VERSION ""

NS_ :

BS_:

BU_: TCM HCM IPMA_ADAS PSCM ABS_ESC TCCM TCM_DSL PCM_HEV PCM ECM_HEVDSL ECM_HEV ECM_Diesel ECM SIMA_DLCS BCMD_IPDB VDM CMR_DSMC SOBDMC_HPCM CHCM GWM _delete AWD_DLCM GENERIC TSTR

BO_ 495 EngineData_14_FD1: 8 GWM
 SG_ AlchlLck_D_RqLimActvtn : 2|2@0+ (1,0) [0|3] "unitless"  ECM,ECM_Diesel,ECM_HEV,PCM,PCM_HEV
 SG_ AlchlLck2_D_RqLim : 7|5@0+ (1,0) [0|31] "unitless"  ECM,ECM_Diesel,ECM_HEV,PCM,PCM_HEV
 SG_ AlchlLck1_D_RqLim : 15|5@0+ (1,0) [0|31] "unitless"  ECM,ECM_Diesel,ECM_HEV,PCM,PCM_HEV

BO_ 466 EngineData_13: 8 ECM
 SG_ AlchlLck1_D_ResLim : 27|5@0+ (1,0) [0|31] "unitless"  GWM
 SG_ AlchlLck2_D_ResLim : 35|5@0+ (1,0) [0|31] "unitless"  GWM
 SG_ AlchlLck1_D_StatLim : 38|3@0+ (1,0) [0|7] "unitless"  GWM
 SG_ AlchlLck2_D_StatLim : 46|3@0+ (1,0) [0|7] "unitless"  GWM

BO_ 283 HEV_EngineData3: 8 ECM_HEV
 SG_ AirCondClnt_Te_Actl : 7|8@0+ (1,-60) [-60|194] "degC"  SOBDMC_HPCM

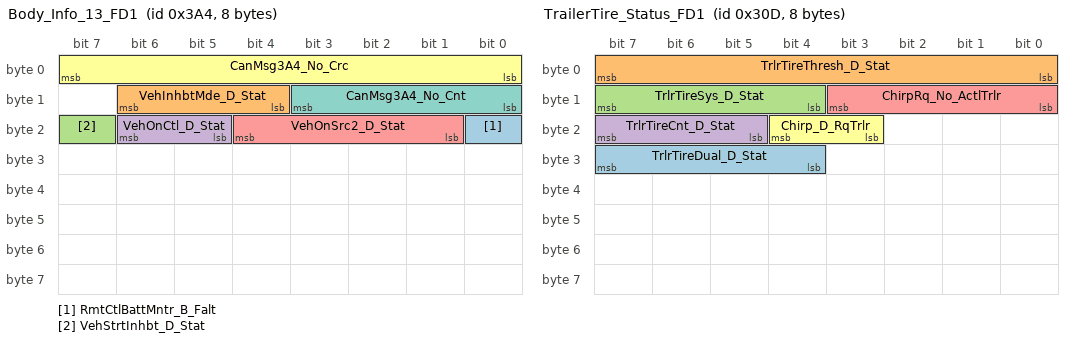
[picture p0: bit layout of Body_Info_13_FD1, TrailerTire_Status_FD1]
BO_ 932 Body_Info_13_FD1: 8 BCM
 SG_ RmtCtlBattMntr_B_Falt : 16|1@0+ (1,0) [0|1] "SED"  GENERIC
 SG_ VehInhbtMde_D_Stat : 14|3@0+ (1,0) [0|7] "SED"  GENERIC
 SG_ VehStrtInhbt_D_Stat : 23|1@0+ (1,0) [0|1] "SED"  GENERIC
 SG_ VehOnCtl_D_Stat : 22|2@0+ (1,0) [0|3] "SED"  GENERIC
 SG_ VehOnSrc2_D_Stat : 20|4@0+ (1,0) [0|15] "SED"  IPMA_ADAS
 SG_ CanMsg3A4_No_Crc : 7|8@0+ (1,0) [0|255] "Unitless"  GENERIC
 SG_ CanMsg3A4_No_Cnt : 11|4@0+ (1,0) [0|15] "Unitless"  GENERIC

BO_ 781 TrailerTire_Status_FD1: 8 GFM_TTPMS
 SG_ TrlrTireDual_D_Stat : 31|4@0+ (1,0) [0|15] "SED"  GENERIC
 SG_ TrlrTireThresh_D_Stat : 7|8@0+ (1,0) [0|255] "unitless"  GENERIC
 SG_ TrlrTireSys_D_Stat : 15|4@0+ (1,0) [0|15] "SED"  IPMA_ADAS
 SG_ TrlrTireCnt_D_Stat : 23|3@0+ (1,0) [0|6] "SED"  GENERIC
 SG_ ChirpRq_No_ActlTrlr : 11|4@0+ (1,0) [0|15] "unitless"  GENERIC
 SG_ Chirp_D_RqTrlr : 20|2@0+ (1,0) [0|3] "SED"  GENERIC

BO_ 368 PowertrainData_4: 8 SOBDMC_HPCM
 SG_ PrplBrkTqCtl_No_Cs : 7|8@0+ (1,0) [0|255] "Unitless"  ABS_ESC
 SG_ PrplBrkTqCtl_No_Cnt : 15|4@0+ (1,0) [0|15] "Unitless"  ABS_ESC
 SG_ PrplWhlTot_Tq_RqFilt : 23|16@0+ (4,-131072) [-131072|131060] "Nm"  ABS_ESC

BO_ 1267 Battery_Traction_14_FD1: 8 BECM
 SG_ BattTracLearn_R_Est : 7|20@0+ (1E-005,0) [0|10.48573] "ohm"  SOBDMC_HPCM
 SG_ BattTracLearnRC_C_Est : 19|20@0+ (0.1,0) [0|104857.3] "farad"  SOBDMC_HPCM
 SG_ BattTracLearnRC_R_Est : 47|20@0+ (1E-005,0) [0|10.48573] "ohm"  SOBDMC_HPCM

BO_ 393 AssistedFrontLighting: 64 IPMA_ADAS
 SG_ Afl6TrnstnRight_An_Rq : 419|4@0+ (0.2,0) [0|3] "degrees" Vector__XXX
 SG_ Afl6TrnstnLeft_An_Rq : 423|4@0+ (0.2,0) [0|3] "degrees" Vector__XXX
 SG_ Afl6RightLghtRigh_An_Rq : 432|9@0+ (0.1,-25.6) [-25.6|25.5] "degrees" Vector__XXX
 SG_ Afl6RightLghtLeft_An_Rq : 400|9@0+ (0.1,-25.6) [-25.6|25.5] "degrees" Vector__XXX
 SG_ Afl6Ramping_T_Rq : 387|4@0+ (0.2,0) [0|3] "second" Vector__XXX
 SG_ Afl6LeftLghtRight_An_Rq : 431|9@0+ (0.1,-25.6) [-25.6|25.5] "degrees" Vector__XXX
 SG_ Afl6LeftLghtLeft_An_Rq : 399|9@0+ (0.1,-25.6) [-25.6|25.5] "degrees" Vector__XXX
 SG_ Afl6BrdrTop_An_Rq : 438|6@0+ (0.1,-5) [-5|1.3] "degrees" Vector__XXX
 SG_ Afl6BrdrBottom_An_Rq : 406|6@0+ (0.1,-5) [-5|1.3] "degrees" Vector__XXX
 SG_ Afl5TrnstnRight_An_Rq : 355|4@0+ (0.2,0) [0|3] "degrees" Vector__XXX
 SG_ Afl5TrnstnLeft_An_Rq : 359|4@0+ (0.2,0) [0|3] "degrees" Vector__XXX
 SG_ Afl5RightLghtRigh_An_Rq : 368|9@0+ (0.1,-25.6) [-25.6|25.5] "degrees" Vector__XXX
 SG_ Afl5RightLghtLeft_An_Rq : 336|9@0+ (0.1,-25.6) [-25.6|25.5] "degrees" Vector__XXX
 SG_ Afl5Ramping_T_Rq : 323|4@0+ (0.2,0) [0|3] "second" Vector__XXX
 SG_ Afl5LeftLghtRight_An_Rq : 367|9@0+ (0.1,-25.6) [-25.6|25.5] "degrees" Vector__XXX
 SG_ Afl5LeftLghtLeft_An_Rq : 335|9@0+ (0.1,-25.6) [-25.6|25.5] "degrees" Vector__XXX
 SG_ Afl5BrdrTop_An_Rq : 374|6@0+ (0.1,-5) [-5|1.3] "degrees" Vector__XXX
 SG_ Afl5BrdrBottom_An_Rq : 342|6@0+ (0.1,-5) [-5|1.3] "degrees" Vector__XXX
 SG_ Afl4TrnstnRight_An_Rq : 291|4@0+ (0.2,0) [0|3] "degrees" Vector__XXX
 SG_ Afl4TrnstnLeft_An_Rq : 295|4@0+ (0.2,0) [0|3] "degrees" Vector__XXX
 SG_ Afl4RightLghtRigh_An_Rq : 304|9@0+ (0.1,-25.6) [-25.6|25.5] "degrees" Vector__XXX
 SG_ Afl4RightLghtLeft_An_Rq : 272|9@0+ (0.1,-25.6) [-25.6|25.5] "degrees" Vector__XXX
 SG_ Afl4Ramping_T_Rq : 259|4@0+ (0.2,0) [0|3] "second" Vector__XXX
 SG_ Afl4LeftLghtRight_An_Rq : 303|9@0+ (0.1,-25.6) [-25.6|25.5] "degrees" Vector__XXX
 SG_ Afl4LeftLghtLeft_An_Rq : 271|9@0+ (0.1,-25.6) [-25.6|25.5] "degrees" Vector__XXX
 SG_ Afl4BrdrTop_An_Rq : 310|6@0+ (0.1,-5) [-5|1.3] "degrees" Vector__XXX
 SG_ Afl4BrdrBottom_An_Rq : 278|6@0+ (0.1,-5) [-5|1.3] "degrees" Vector__XXX
 SG_ Afl3TrnstnRight_An_Rq : 227|4@0+ (0.2,0) [0|3] "degrees" Vector__XXX
 SG_ Afl3TrnstnLeft_An_Rq : 231|4@0+ (0.2,0) [0|3] "degrees" Vector__XXX
 SG_ Afl3RightLghtRigh_An_Rq : 240|9@0+ (0.1,-25.6) [-25.6|25.5] "degrees" Vector__XXX
 SG_ Afl3RightLghtLeft_An_Rq : 208|9@0+ (0.1,-25.6) [-25.6|25.5] "degrees" Vector__XXX
 SG_ Afl3Ramping_T_Rq : 195|4@0+ (0.2,0) [0|3] "second" Vector__XXX
 SG_ Afl3LeftLghtRight_An_Rq : 239|9@0+ (0.1,-25.6) [-25.6|25.5] "degrees" Vector__XXX
 SG_ Afl3BrdrTop_An_Rq : 246|6@0+ (0.1,-5) [-5|1.3] "degrees" Vector__XXX
 SG_ Afl3BrdrBottom_An_Rq : 214|6@0+ (0.1,-5) [-5|1.3] "degrees" Vector__XXX
 SG_ Afl2BrdrBottom_An_Rq : 150|6@0+ (0.1,-5) [-5|1.3] "degrees" Vector__XXX
 SG_ Afl1BrdrBottom_An_Rq : 86|6@0+ (0.1,-5) [-5|1.3] "degrees" Vector__XXX
 SG_ Afl2BrdrTop_An_Rq : 182|6@0+ (0.1,-5) [-5|1.3] "degrees" Vector__XXX
 SG_ Afl1BrdrTop_An_Rq : 118|6@0+ (0.1,-5) [-5|1.3] "degrees" Vector__XXX
 SG_ Afl2TrnstnRight_An_Rq : 163|4@0+ (0.2,0) [0|3] "degrees" Vector__XXX
 SG_ Afl1TrnstnRight_An_Rq : 99|4@0+ (0.2,0) [0|3] "degrees" Vector__XXX
 SG_ Afl2RightLghtRigh_An_Rq : 176|9@0+ (0.1,-25.6) [-25.6|25.5] "degrees" Vector__XXX
 SG_ Afl1RightLghtRigh_An_Rq : 112|9@0+ (0.1,-25.6) [-25.6|25.5] "degrees" Vector__XXX
 SG_ Afl2LeftLghtRight_An_Rq : 175|9@0+ (0.1,-25.6) [-25.6|25.5] "degrees" Vector__XXX
 SG_ Afl1LeftLghtRight_An_Rq : 111|9@0+ (0.1,-25.6) [-25.6|25.5] "degrees" Vector__XXX
 SG_ Afl2TrnstnLeft_An_Rq : 167|4@0+ (0.2,0) [0|3] "degrees" Vector__XXX
 SG_ Afl1TrnstnLeft_An_Rq : 103|4@0+ (0.2,0) [0|3] "degrees" Vector__XXX
 SG_ Afl2RightLghtLeft_An_Rq : 144|9@0+ (0.1,-25.6) [-25.6|25.5] "degrees" Vector__XXX
 SG_ Afl1RightLghtLeft_An_Rq : 80|9@0+ (0.1,-25.6) [-25.6|25.5] "degrees" Vector__XXX
 SG_ Afl3LeftLghtLeft_An_Rq : 207|9@0+ (0.1,-25.6) [-25.6|25.5] "degrees" Vector__XXX
 SG_ Afl2LeftLghtLeft_An_Rq : 143|9@0+ (0.1,-25.6) [-25.6|25.5] "degrees" Vector__XXX
 SG_ Afl1LeftLghtLeft_An_Rq : 79|9@0+ (0.1,-25.6) [-25.6|25.5] "degrees" Vector__XXX
 SG_ Afl2Ramping_T_Rq : 131|4@0+ (0.2,0) [0|3] "second" Vector__XXX
 SG_ Afl1Ramping_T_Rq : 67|4@0+ (0.2,0) [0|3] "second" Vector__XXX
 SG_ Afl6Mde_D_Rq : 391|4@0+ (1,0) [0|15] "SED" Vector__XXX
 SG_ Afl5Mde_D_Rq : 327|4@0+ (1,0) [0|15] "SED" Vector__XXX
 SG_ Afl4Mde_D_Rq : 263|4@0+ (1,0) [0|15] "SED" Vector__XXX
 SG_ Afl3Mde_D_Rq : 199|4@0+ (1,0) [0|15] "SED" Vector__XXX
 SG_ Afl2Mde_D_Rq : 135|4@0+ (1,0) [0|15] "SED" Vector__XXX
 SG_ Afl1Mde_D_Rq : 71|4@0+ (1,0) [0|15] "SED" Vector__XXX
 SG_ HeadLghtHi_T_Rq : 4|4@0+ (0.2,0) [0|3] "second" Vector__XXX
 SG_ HeadLghtHi_D_Rq : 7|3@0+ (1,0) [0|7] "SED" Vector__XXX

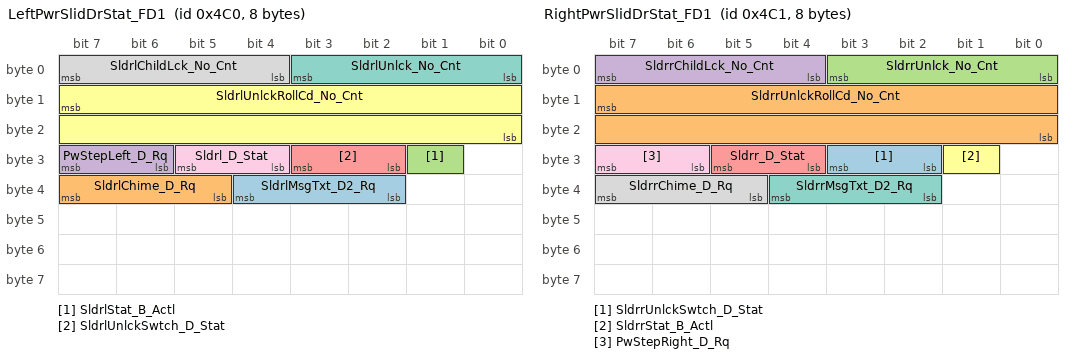
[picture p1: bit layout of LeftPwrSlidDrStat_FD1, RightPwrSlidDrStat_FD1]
BO_ 1216 LeftPwrSlidDrStat_FD1: 8 DCMG_LPSDM
 SG_ SldrlMsgTxt_D2_Rq : 36|3@0+ (1,0) [0|7] "SED"  GENERIC
 SG_ SldrlChime_D_Rq : 39|3@0+ (1,0) [0|7] "SED"  GENERIC
 SG_ SldrlStat_B_Actl : 25|1@0+ (1,0) [0|1] "SED"  GENERIC
 SG_ PwStepLeft_D_Rq : 31|2@0+ (1,0) [0|3] "SED"  GENERIC
 SG_ SldrlUnlckSwtch_D_Stat : 27|2@0+ (1,0) [0|3] "SED"  GENERIC
 SG_ SldrlUnlckRollCd_No_Cnt : 15|16@0+ (1,0) [0|65535] "unitless"  GENERIC
 SG_ SldrlUnlck_No_Cnt : 3|4@0+ (1,0) [0|15] "unitless"  GENERIC
 SG_ SldrlChildLck_No_Cnt : 7|4@0+ (1,0) [0|15] "unitless"  GENERIC
 SG_ Sldrl_D_Stat : 29|2@0+ (1,0) [0|3] "SED"  IPMA_ADAS

BO_ 1217 RightPwrSlidDrStat_FD1: 8 DCMH_RPSDM
 SG_ SldrrUnlckSwtch_D_Stat : 27|2@0+ (1,0) [0|3] "SED"  GENERIC
 SG_ SldrrUnlckRollCd_No_Cnt : 15|16@0+ (1,0) [0|65535] "unitless"  GENERIC
 SG_ SldrrUnlck_No_Cnt : 3|4@0+ (1,0) [0|15] "unitless"  GENERIC
 SG_ SldrrChildLck_No_Cnt : 7|4@0+ (1,0) [0|15] "unitless"  GENERIC
 SG_ Sldrr_D_Stat : 29|2@0+ (1,0) [0|3] "SED"  IPMA_ADAS
 SG_ SldrrStat_B_Actl : 25|1@0+ (1,0) [0|1] "SED"  GENERIC
 SG_ SldrrMsgTxt_D2_Rq : 36|3@0+ (1,0) [0|7] "SED"  GENERIC
 SG_ SldrrChime_D_Rq : 39|3@0+ (1,0) [0|7] "SED"  GENERIC
 SG_ PwStepRight_D_Rq : 31|2@0+ (1,0) [0|3] "SED"  GENERIC

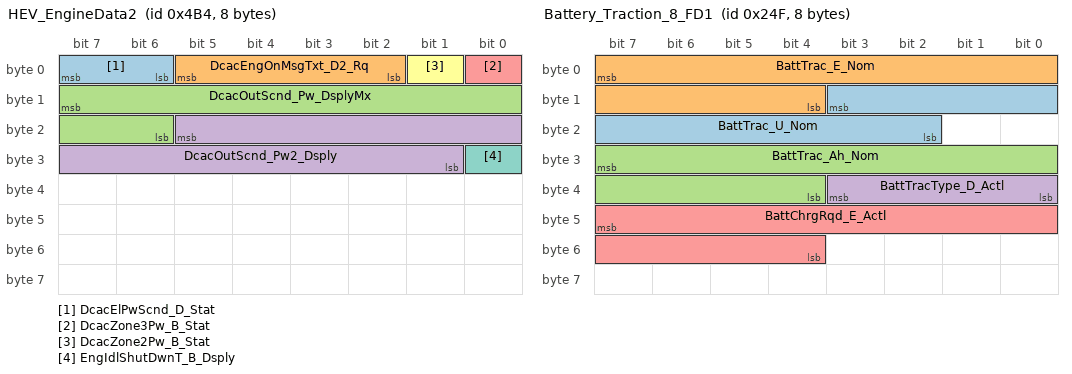
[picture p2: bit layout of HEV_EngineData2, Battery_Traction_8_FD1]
BO_ 1204 HEV_EngineData2: 8 ECM_HEV
 SG_ DcacElPwScnd_D_Stat : 7|2@0+ (1,0) [0|3] "SED"  GWM
 SG_ DcacEngOnMsgTxt_D2_Rq : 5|4@0+ (1,0) [0|15] "SED"  GWM
 SG_ DcacOutScnd_Pw_DsplyMx : 15|10@0+ (10,0) [0|10220] "watts"  GWM
 SG_ DcacOutScnd_Pw2_Dsply : 21|13@0+ (1,0) [0|8189] "watts"  GWM
 SG_ DcacZone3Pw_B_Stat : 0|1@0+ (1,0) [0|1] "SED"  GWM
 SG_ DcacZone2Pw_B_Stat : 1|1@0+ (1,0) [0|1] "SED"  GWM
 SG_ EngIdlShutDwnT_B_Dsply : 24|1@0+ (1,0) [0|1] "SED"  GWM

BO_ 816 APIM_Send_Signals_3_FD1: 8 APIM_CISM
 SG_ Dimming_Lvl_RqMnu : 63|5@0+ (1,0) [0|31] "SED"  GENERIC
 SG_ DcacPwResetScnd_B_Rq : 24|1@0+ (1,0) [0|1] "SED"  ECM_HEV
 SG_ DcacPwScnd_D_Rq : 53|2@0+ (1,0) [0|3] "SED"  ECM_HEV
 SG_ DcacZone3Pw_D_Rq : 55|2@0+ (1,0) [0|3] "SED"  ECM_HEV
 SG_ DcacZone2Pw_D_Rq : 35|2@0+ (1,0) [0|3] "SED"  ECM_HEV
 SG_ DcacAllZone_D_Rq : 37|2@0+ (1,0) [0|3] "SED"  ECM_HEV
 SG_ DcacLoFuelLim_L_RqMnu : 32|9@0+ (1,0) [0|509] "kilometer"  ECM_HEV
 SG_ KeylessIdl_D_Rq : 39|2@0+ (1,0) [0|3] "SED"  GENERIC
 SG_ KeyPadCodeDgt7_D_Stat : 31|4@0+ (1,0) [0|15] "SED"  GENERIC
 SG_ KeyPadCodeDgt6_D_Stat : 19|4@0+ (1,0) [0|15] "SED"  GENERIC
 SG_ KeyPadCodeDgt5_D_Stat : 23|4@0+ (1,0) [0|15] "SED"  GENERIC
 SG_ KeyPadCodeDgt4_D_Stat : 11|4@0+ (1,0) [0|15] "SED"  GENERIC
 SG_ KeyPadCodeDgt3_D_Stat : 15|4@0+ (1,0) [0|15] "SED"  GENERIC
 SG_ KeyPadCodeDgt2_D_Stat : 3|4@0+ (1,0) [0|15] "SED"  GENERIC
 SG_ HybMdeSel_D_Rq : 58|3@0+ (1,0) [0|7] "SED"  PCM_HEV,SOBDMC_HPCM
 SG_ KeyPadCodeDgt1_D_Stat : 7|4@0+ (1,0) [0|15] "SED"  GENERIC
 SG_ CntrStk2_D_RqAssoc : 27|3@0+ (1,0) [0|7] "SED"  GENERIC

BO_ 805 InstFuelEconomy_2_FD1: 8 IPC
 SG_ FuelRange_L2_Dsply : 31|15@0+ (0.1,0) [0|3276.7] "kilometer"  ECM_HEV,ECM_Diesel
 SG_ InstFeTripUnit_D_Stat : 23|4@0+ (1,0) [0|15] "SED"  GENERIC
 SG_ InstFe_No_Dsply : 7|14@0+ (0.1,0) [0|1638.3] "unitless"  GENERIC

BO_ 646 Battery_Traction_13_FD1: 8 BECM
 SG_ BattTrac3_Pw_LimDchrg : 55|16@0+ (50,0) [0|3276750] "watts"  SOBDMC_HPCM
 SG_ BattTrac3_Pw_LimChrg : 39|16@0+ (50,0) [0|3276750] "watts"  SOBDMC_HPCM
 SG_ BattTrac3_Pw_DchrgInst : 23|16@0+ (50,0) [0|3276750] "watts"  SOBDMC_HPCM
 SG_ BattTrac3_Pw_ChrgInst : 7|16@0+ (50,0) [0|3276750] "watts"  SOBDMC_HPCM

BO_ 591 Battery_Traction_8_FD1: 8 BECM
 SG_ BattTrac_U_Nom : 11|10@0+ (0.5,0) [0|510.5] "volt"  GENERIC
 SG_ BattTrac_E_Nom : 7|12@0+ (50,0) [0|204650] "watt*hr"  GENERIC
 SG_ BattTrac_Ah_Nom : 31|12@0+ (0.1,0) [0|409.4] "ampere*hour"  GENERIC
 SG_ BattTracType_D_Actl : 35|4@0+ (1,0) [0|15] "SED"  GENERIC
 SG_ BattChrgRqd_E_Actl : 47|12@0+ (50,0) [0|204650] "watt*hour"  SOBDMC_HPCM

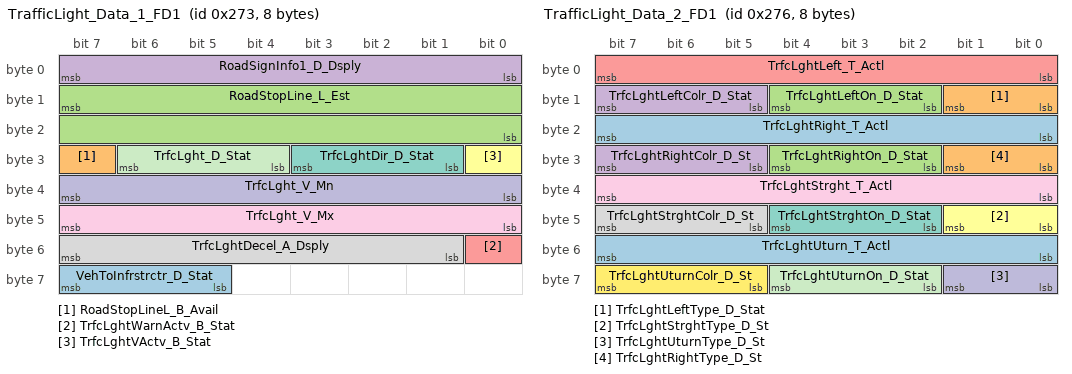
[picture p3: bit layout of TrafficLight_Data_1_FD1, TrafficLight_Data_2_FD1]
BO_ 627 TrafficLight_Data_1_FD1: 8 APIM_CISM
 SG_ VehToInfrstrctr_D_Stat : 63|3@0+ (1,0) [0|7] "SED"  PCM
 SG_ RoadStopLineL_B_Avail : 31|1@0+ (1,0) [0|1] "SED"  PCM
 SG_ RoadStopLine_L_Est : 15|16@0+ (1,0) [0|65533] "cm"  PCM
 SG_ RoadSignInfo1_D_Dsply : 7|8@0+ (1,0) [0|255] "SED"  PCM
 SG_ TrfcLghtWarnActv_B_Stat : 48|1@0+ (1,0) [0|1] "SED"  PCM
 SG_ TrfcLghtVActv_B_Stat : 24|1@0+ (1,0) [0|1] "SED"  PCM
 SG_ TrfcLghtDir_D_Stat : 27|3@0+ (1,0) [0|7] "SED"  PCM
 SG_ TrfcLghtDecel_A_Dsply : 55|7@0+ (1,0) [0|125] "km/hour"  PCM
 SG_ TrfcLght_V_Mx : 47|8@0+ (1,0) [0|253] "km/hour"  PCM
 SG_ TrfcLght_V_Mn : 39|8@0+ (1,0) [0|253] "km/hour"  PCM
 SG_ TrfcLght_D_Stat : 30|3@0+ (1,0) [0|7] "SED"  PCM

BO_ 630 TrafficLight_Data_2_FD1: 8 APIM_CISM
 SG_ TrfcLghtRight_T_Actl : 23|8@0+ (1,0) [0|253] "second"  PCM
 SG_ TrfcLghtLeftType_D_Stat : 9|2@0+ (1,0) [0|3] "SED"  PCM
 SG_ TrfcLghtLeftOn_D_Stat : 12|3@0+ (1,0) [0|7] "SED"  PCM
 SG_ TrfcLghtLeftColr_D_Stat : 15|3@0+ (1,0) [0|7] "SED"  PCM
 SG_ TrfcLghtLeft_T_Actl : 7|8@0+ (1,0) [0|253] "second"  PCM
 SG_ TrfcLghtStrghtType_D_St : 41|2@0+ (1,0) [0|3] "SED"  PCM
 SG_ TrfcLghtStrghtOn_D_Stat : 44|3@0+ (1,0) [0|7] "SED"  PCM
 SG_ TrfcLghtStrghtColr_D_St : 47|3@0+ (1,0) [0|7] "SED"  PCM
 SG_ TrfcLghtStrght_T_Actl : 39|8@0+ (1,0) [0|253] "second"  PCM
 SG_ TrfcLghtUturnType_D_St : 57|2@0+ (1,0) [0|3] "SED"  PCM
 SG_ TrfcLghtUturnOn_D_Stat : 60|3@0+ (1,0) [0|7] "SED"  PCM
 SG_ TrfcLghtUturnColr_D_St : 63|3@0+ (1,0) [0|7] "SED"  PCM
 SG_ TrfcLghtUturn_T_Actl : 55|8@0+ (1,0) [0|253] "second"  PCM
 SG_ TrfcLghtRightType_D_St : 25|2@0+ (1,0) [0|3] "SED"  PCM
 SG_ TrfcLghtRightOn_D_Stat : 28|3@0+ (1,0) [0|7] "SED"  PCM
 SG_ TrfcLghtRightColr_D_St : 31|3@0+ (1,0) [0|7] "SED"  PCM

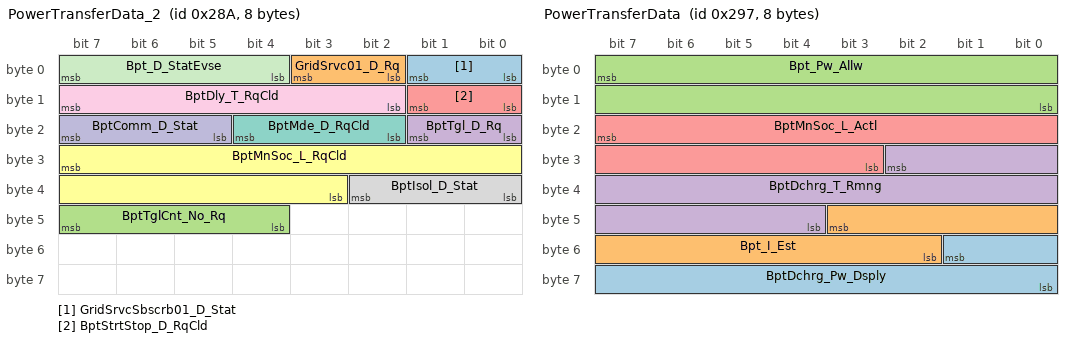
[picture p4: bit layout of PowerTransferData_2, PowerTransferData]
BO_ 650 PowerTransferData_2: 8 GWM
 SG_ GridSrvcSbscrb01_D_Stat : 1|2@0+ (1,0) [0|3] "SED"  SOBDMC_HPCM
 SG_ GridSrvc01_D_Rq : 3|2@0+ (1,0) [0|3] "SED"  SOBDMC_HPCM
 SG_ BptTglCnt_No_Rq : 47|4@0+ (1,0) [0|13] "unitless"  SOBDMC_HPCM
 SG_ BptTgl_D_Rq : 17|2@0+ (1,0) [0|3] "SED"  SOBDMC_HPCM
 SG_ BptStrtStop_D_RqCld : 9|2@0+ (1,0) [0|3] "SED"  SOBDMC_HPCM
 SG_ BptMnSoc_L_RqCld : 31|13@0+ (0.1,0) [0|818.9] "kilometer"  SOBDMC_HPCM
 SG_ BptMde_D_RqCld : 20|3@0+ (1,0) [0|7] "SED"  SOBDMC_HPCM
 SG_ BptIsol_D_Stat : 34|3@0+ (1,0) [0|7] "SED"  SOBDMC_HPCM
 SG_ BptDly_T_RqCld : 15|6@0+ (0.5,0) [0|30.5] "minute"  SOBDMC_HPCM
 SG_ BptComm_D_Stat : 23|3@0+ (1,0) [0|7] "SED"  SOBDMC_HPCM
 SG_ Bpt_D_StatEvse : 7|4@0+ (1,0) [0|15] "SED"  SOBDMC_HPCM

BO_ 663 PowerTransferData: 8 SOBDMC_HPCM
 SG_ BptDchrg_Pw_Dsply : 49|10@0+ (0.1,0) [0|102.1] "kilowatt"  GWM
 SG_ Bpt_I_Est : 43|10@0+ (1,-510) [-510|511] "ampere"  GWM
 SG_ Bpt_Pw_Allw : 7|16@0+ (0.1,0) [0|6553.3] "kilowatt"  GWM
 SG_ BptDchrg_T_Rmng : 26|15@0+ (1,0) [0|32765] "minute"  GWM
 SG_ BptMnSoc_L_Actl : 23|13@0+ (0.1,0) [0|818.9] "kilometer"  GWM

BO_ 655 ECG_Data5_FD1: 8 GWM
 SG_ EvseChrgOutHi_U_ActlBpt : 42|10@0+ (0.5,0) [0|510.5] "volt"  SOBDMC_HPCM
 SG_ EvseChrgOutHi_I_ActlBpt : 25|15@0+ (0.05,-750) [-750|888.25] "ampere"  SOBDMC_HPCM
 SG_ EvseDchrg_Pw_Mx : 8|15@0+ (50,0) [0|1638250] "wattS"  SOBDMC_HPCM
 SG_ EvseDchrg_I_Mx : 7|15@0+ (0.05,0) [0|1638.25] "ampere"  SOBDMC_HPCM

BO_ 599 Battery_Traction_12_FD1: 8 BECM
 SG_ Bpt_D_StatBattTrac : 7|3@0+ (1,0) [0|7] "SED"  SOBDMC_HPCM

BO_ 1227 DCACB_Data6_FD1: 8 GFM3_DCACB
 SG_ DcacCabinScnd_I_Actl : 55|16@0+ (0.001,0) [0|65.533] "ampere"  ECM_HEV,PCM
 SG_ DcacOutlet8Scnd_I_Actl : 39|16@0+ (0.001,0) [0|65.533] "ampere"  ECM_HEV,PCM
 SG_ DcacOutlet7Scnd_I_Actl : 23|16@0+ (0.001,0) [0|65.533] "ampere"  ECM_HEV,PCM
 SG_ DcacOutlet6Scnd_I_Actl : 7|16@0+ (0.001,0) [0|65.533] "ampere"  ECM_HEV,PCM

BO_ 1222 DCACA_Data5_FD1: 8 DCACA_HEV
 SG_ DcacOutlet8_I_Actl : 55|16@0+ (0.001,0) [0|65.533] "ampere"  ECM_HEV,PCM
 SG_ DcacOutlet7_I_Actl : 39|16@0+ (0.001,0) [0|65.533] "ampere"  ECM_HEV,PCM
 SG_ DcacOutlet6_I_Actl : 23|16@0+ (0.001,0) [0|65.533] "ampere"  ECM_HEV,PCM
 SG_ DcacCabin_I_Actl : 7|16@0+ (0.001,0) [0|65.533] "ampere"  ECM_HEV,PCM

BO_ 595 APIM_Send_Signals_7_FD1: 8 APIM_CISM
 SG_ DrvIdMde_D_Rq : 7|3@0+ (1,0) [0|7] "SED"  CMR_DSMC
 SG_ DrvIdDelete_No_Rq : 15|32@0+ (1,0) [0|4294967295] "Unitless"  CMR_DSMC

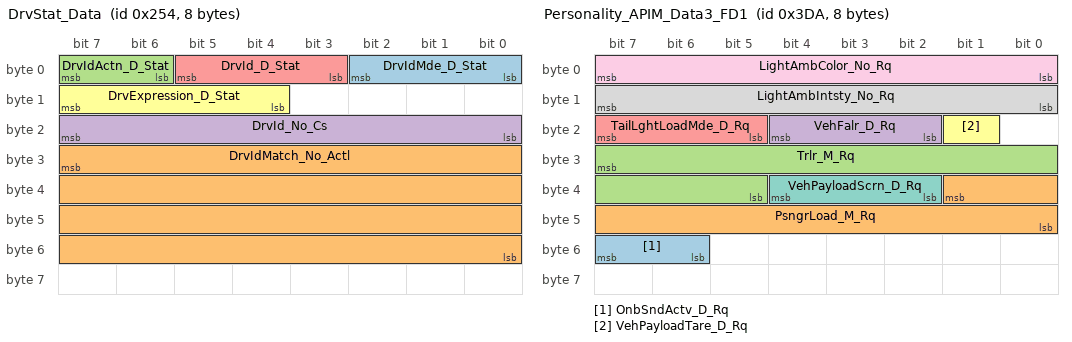
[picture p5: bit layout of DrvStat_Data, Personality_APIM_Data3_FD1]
BO_ 596 DrvStat_Data: 8 CMR_DSMC
 SG_ DrvIdMde_D_Stat : 2|3@0+ (1,0) [0|7] "SED"  GWM
 SG_ DrvIdMatch_No_Actl : 31|32@0+ (1,0) [0|4294967295] "Unitless"  GWM
 SG_ DrvIdActn_D_Stat : 7|2@0+ (1,0) [0|3] "SED"  GWM
 SG_ DrvId_No_Cs : 23|8@0+ (1,0) [0|255] "unitless"  GWM
 SG_ DrvId_D_Stat : 5|3@0+ (1,0) [0|7] "SED"  GWM
 SG_ DrvExpression_D_Stat : 15|4@0+ (1,0) [0|15] "SED"  GWM

BO_ 612 AUXM_Data_FD1: 8 BCMB_AUXM
 SG_ SelDrvMdeSwtch_D_Stat6 : 7|2@0+ (1,0) [0|3] "SED"  ABS_ESC

BO_ 1015 Clmt_Button_Stat8_FD1: 8 FCIM
 SG_ SelDrvMdeSwtch_D_Stat7 : 1|2@0+ (1,0) [0|3] "SED"  ABS_ESC
 SG_ E_Frt_Btn_Status_2nd : 15|6@0+ (1,0) [0|63] "SED"  GENERIC
 SG_ E_Frt_Btn_Status_1st : 7|6@0+ (1,0) [0|63] "SED"  GENERIC

BO_ 2611034328 PARSEDPhysGWM_ECGtoLDCMB: 64 GWM
 SG_ PARSEDPhysGWM_ECGtoLDCMB : 7|29@0+ (1,0) [0|536870911] "unitless"  HCM

BO_ 2611035352 PARSEDPhysGWM_ECGtoLDCMA: 64 GWM
 SG_ PARSEDPhysGWM_ECGtoLDCMA : 7|29@0+ (1,0) [0|536870911] "unitless"  HCM

BO_ 2611175502 PARSEDPhysLDCMBtoGWM_ECG: 64 HCM
 SG_ PARSEDPhysLDCMBtoGWM_ECG : 7|29@0+ (1,0) [0|536870911] "Unitless"  GWM

BO_ 2611175503 PARSEDPhysLDCMAtoGWM_ECG: 64 HCM
 SG_ PARSEDPhysLDCMAtoGWM_ECG : 7|29@0+ (1,0) [0|536870911] "unitless"  GWM

BO_ 2612224078 PARSEDPushLDCMBtoGWM_ECG: 8 HCM
 SG_ PARSEDPushLDCMBtoGWM_ECG : 7|29@0+ (1,0) [0|536870911] "unitless"  GWM

BO_ 2612224079 PARSEDPushLDCMAtoGWM_ECG: 8 HCM
 SG_ PARSEDPushLDCMAtoGWM_ECG : 7|29@0+ (1,0) [0|536870911] "unitless"  GWM

BO_ 2612082904 PARSEDPushFcGWM_ECGtoLDCMB: 8 GWM
 SG_ PARSEDPushFcGWM_ECGtoLDCMB : 7|29@0+ (1,0) [0|536870911] "unitless"  HCM

BO_ 2612083928 PARSEDPushFcGWM_ECGtoLDCMA: 8 GWM
 SG_ PARSEDPushFcGWM_ECGtoLDCMA : 7|29@0+ (1,0) [0|536870911] "unitless"  HCM

BO_ 2610126926 OTAPhysLDCMBtoGWM_ECG: 64 HCM
 SG_ OTAPhysLDCMBtoGWM_ECG : 7|29@0+ (1,0) [0|536870911] "unitless"  GWM

BO_ 2610126927 OTAPhysLDCMAtoGWM_ECG: 64 HCM
 SG_ OTAPhysLDCMAtoGWM_ECG : 7|29@0+ (1,0) [0|536870911] "unitless"  GWM

BO_ 2609985752 OTAPhysGWM_ECGtoLDCMB: 64 GWM
 SG_ OTAPhysGWM_ECGtoLDCMB : 7|29@0+ (1,0) [0|536870911] "unitless"  HCM

BO_ 2609986776 OTAPhysGWM_ECGtoLDCMA: 64 GWM
 SG_ OTAPhysGWM_ECGtoLDCMA : 7|29@0+ (1,0) [0|536870911] "unitless"  HCM

BO_ 986 Personality_APIM_Data3_FD1: 8 APIM
 SG_ OnbSndActv_D_Rq : 55|2@0+ (1,0) [0|3] "SED"  GENERIC
 SG_ PsngrLoad_M_Rq : 33|10@0+ (1,0) [0|1021] "kilogram"  VDM
 SG_ Trlr_M_Rq : 31|11@0+ (10,0) [0|20450] "kilogram"  VDM
 SG_ VehFalr_D_Rq : 20|3@0+ (1,0) [0|7] "SED"  VDM
 SG_ TailLghtLoadMde_D_Rq : 23|3@0+ (1,0) [0|7] "SED"  GENERIC
 SG_ VehPayloadTare_D_Rq : 17|1@0+ (1,0) [0|1] "SED"  VDM
 SG_ VehPayloadScrn_D_Rq : 36|3@0+ (1,0) [0|7] "SED"  VDM
 SG_ LightAmbIntsty_No_Rq : 15|8@0+ (1,0) [0|255] "unitless"  GENERIC
 SG_ LightAmbColor_No_Rq : 7|8@0+ (1,0) [0|255] "Discrete"  GENERIC

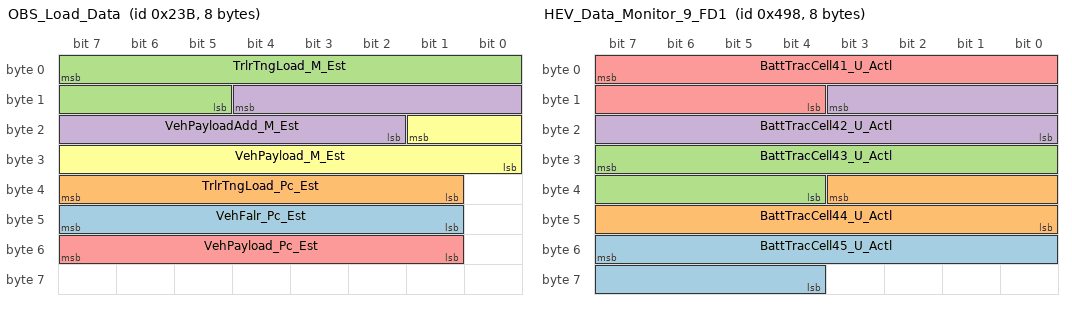
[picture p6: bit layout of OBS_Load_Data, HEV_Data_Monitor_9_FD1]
BO_ 571 OBS_Load_Data: 8 VDM
 SG_ VehFalr_Pc_Est : 47|7@0+ (1,0) [0|125] "percent"  GWM
 SG_ TrlrTngLoad_Pc_Est : 39|7@0+ (1,0) [0|125] "percent"  GWM
 SG_ TrlrTngLoad_M_Est : 7|11@0+ (10,-10240) [-10240|10210] "kilogram"  GWM
 SG_ VehPayloadAdd_M_Est : 12|11@0+ (5,-5115) [-5115|5110] "kilogram"  GWM
 SG_ VehPayload_Pc_Est : 55|7@0+ (1,0) [0|125] "percent"  GWM
 SG_ VehPayload_M_Est : 17|10@0+ (5,0) [0|5105] "kilogram"  ABS_ESC,GWM

BO_ 2612224024 PARSEDPushTCMtoGWM_ECG: 8 TCM_DSL
 SG_ PARSEDPushTCMtoGWM_ECG : 7|29@0+ (1,0) [0|536870911] "unitless"  GWM

BO_ 2612027608 PARSEDPushFcGWM_ECGtoTCM: 8 GWM
 SG_ PARSEDPushFcGWM_ECGtoTCM : 7|29@0+ (1,0) [0|536870911] "unitless"  TCM_DSL

BO_ 2610126872 OTAPhysTCMtoGWM_ECG: 64 TCM_DSL
 SG_ OTAPhysTCMtoGWM_ECG : 7|29@0+ (1,0) [0|536870911] "unitless"  GWM

BO_ 2609930456 OTAPhysGWM_ECGtoTCM: 64 GWM
 SG_ OTAPhysGWM_ECGtoTCM : 7|29@0+ (1,0) [0|536870911] "unitless"  TCM_DSL

BO_ 2610979032 PARSEDPhysGWM_ECGtoTCM: 64 GWM
 SG_ PARSEDPhysGWM_ECGtoTCM : 7|29@0+ (1,0) [0|536870911] "unitless"  TCM_DSL

BO_ 2611175448 PARSEDPhysTCMtoGWM_ECG: 64 TCM_DSL
 SG_ PARSEDPhysTCMCtoGWM_ECG : 7|29@0+ (1,0) [0|536870911] "Unitless"  GWM

BO_ 537 ABS_BrkBst_Data_2: 8 ABS_ESC
 SG_ BrkVacPmpDmd_D_Stat : 5|2@0+ (1,0) [0|3] "SED"  ECM,ECM_HEV
 SG_ BrkBstrStat_No_Cs : 15|8@0+ (1,0) [0|255] "Unitless"  ECM,ECM_HEV
 SG_ BrkBstrStat_No_Cnt : 3|4@0+ (1,0) [0|15] "Unitless"  ECM,ECM_HEV
 SG_ BrkBstrAvail_D_Stat : 7|2@0+ (1,0) [0|3] "SED"  ECM,ECM_HEV

BO_ 1176 HEV_Data_Monitor_9_FD1: 8 BECM
 SG_ BattTracCell45_U_Actl : 55|12@0+ (0.001,1) [1|5.093] "volt"  SOBDMC_HPCM
 SG_ BattTracCell44_U_Actl : 35|12@0+ (0.001,1) [1|5.093] "volt"  SOBDMC_HPCM
 SG_ BattTracCell43_U_Actl : 31|12@0+ (0.001,1) [1|5.093] "volt"  SOBDMC_HPCM
 SG_ BattTracCell42_U_Actl : 11|12@0+ (0.001,1) [1|5.093] "volt"  SOBDMC_HPCM
 SG_ BattTracCell41_U_Actl : 7|12@0+ (0.001,1) [1|5.093] "volt"  SOBDMC_HPCM

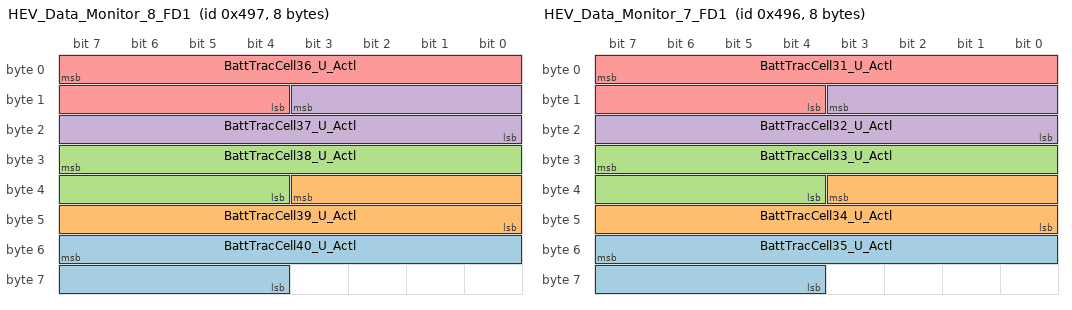
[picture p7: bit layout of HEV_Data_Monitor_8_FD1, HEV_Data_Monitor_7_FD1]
BO_ 1175 HEV_Data_Monitor_8_FD1: 8 BECM
 SG_ BattTracCell40_U_Actl : 55|12@0+ (0.001,1) [1|5.093] "volt"  SOBDMC_HPCM
 SG_ BattTracCell39_U_Actl : 35|12@0+ (0.001,1) [1|5.093] "volt"  SOBDMC_HPCM
 SG_ BattTracCell38_U_Actl : 31|12@0+ (0.001,1) [1|5.093] "volt"  SOBDMC_HPCM
 SG_ BattTracCell37_U_Actl : 11|12@0+ (0.001,1) [1|5.093] "volt"  SOBDMC_HPCM
 SG_ BattTracCell36_U_Actl : 7|12@0+ (0.001,1) [1|5.093] "volt"  SOBDMC_HPCM

BO_ 1174 HEV_Data_Monitor_7_FD1: 8 BECM
 SG_ BattTracCell35_U_Actl : 55|12@0+ (0.001,1) [1|5.093] "volt"  SOBDMC_HPCM
 SG_ BattTracCell34_U_Actl : 35|12@0+ (0.001,1) [1|5.093] "volt"  SOBDMC_HPCM
 SG_ BattTracCell33_U_Actl : 31|12@0+ (0.001,1) [1|5.093] "volt"  SOBDMC_HPCM
 SG_ BattTracCell32_U_Actl : 11|12@0+ (0.001,1) [1|5.093] "volt"  SOBDMC_HPCM
 SG_ BattTracCell31_U_Actl : 7|12@0+ (0.001,1) [1|5.093] "volt"  SOBDMC_HPCM

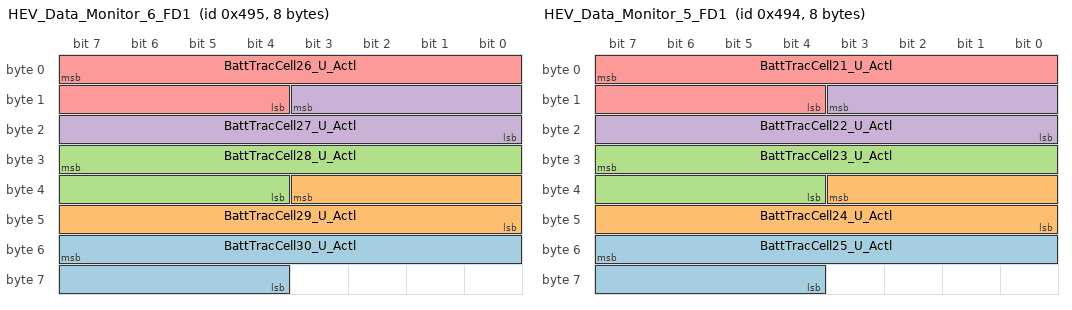
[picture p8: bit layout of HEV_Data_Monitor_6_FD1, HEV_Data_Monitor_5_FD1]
BO_ 1173 HEV_Data_Monitor_6_FD1: 8 BECM
 SG_ BattTracCell30_U_Actl : 55|12@0+ (0.001,1) [1|5.093] "volt"  SOBDMC_HPCM
 SG_ BattTracCell29_U_Actl : 35|12@0+ (0.001,1) [1|5.093] "volt"  SOBDMC_HPCM
 SG_ BattTracCell28_U_Actl : 31|12@0+ (0.001,1) [1|5.093] "volt"  SOBDMC_HPCM
 SG_ BattTracCell27_U_Actl : 11|12@0+ (0.001,1) [1|5.093] "volt"  SOBDMC_HPCM
 SG_ BattTracCell26_U_Actl : 7|12@0+ (0.001,1) [1|5.093] "volt"  SOBDMC_HPCM

BO_ 1172 HEV_Data_Monitor_5_FD1: 8 BECM
 SG_ BattTracCell25_U_Actl : 55|12@0+ (0.001,1) [1|5.093] "volt"  SOBDMC_HPCM
 SG_ BattTracCell24_U_Actl : 35|12@0+ (0.001,1) [1|5.093] "volt"  SOBDMC_HPCM
 SG_ BattTracCell23_U_Actl : 31|12@0+ (0.001,1) [1|5.093] "volt"  SOBDMC_HPCM
 SG_ BattTracCell22_U_Actl : 11|12@0+ (0.001,1) [1|5.093] "volt"  SOBDMC_HPCM
 SG_ BattTracCell21_U_Actl : 7|12@0+ (0.001,1) [1|5.093] "volt"  SOBDMC_HPCM

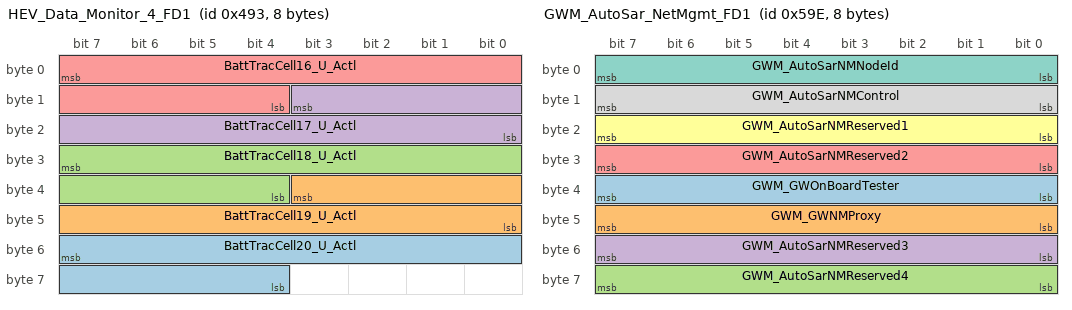
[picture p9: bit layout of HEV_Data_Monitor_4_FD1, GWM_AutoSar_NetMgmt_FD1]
BO_ 1171 HEV_Data_Monitor_4_FD1: 8 BECM
 SG_ BattTracCell20_U_Actl : 55|12@0+ (0.001,1) [1|5.093] "volt"  SOBDMC_HPCM
 SG_ BattTracCell19_U_Actl : 35|12@0+ (0.001,1) [1|5.093] "volt"  SOBDMC_HPCM
 SG_ BattTracCell18_U_Actl : 31|12@0+ (0.001,1) [1|5.093] "volt"  SOBDMC_HPCM
 SG_ BattTracCell17_U_Actl : 11|12@0+ (0.001,1) [1|5.093] "volt"  SOBDMC_HPCM
 SG_ BattTracCell16_U_Actl : 7|12@0+ (0.001,1) [1|5.093] "volt"  SOBDMC_HPCM

BO_ 1822 TesterPhysicalResGWM_FD1: 64 GWM
 SG_ TesterPhysicalResGWM_F1 : 7|64@0+ (1,0) [0|1.84467E+019] "unitless"  TSTR

BO_ 1438 GWM_AutoSar_NetMgmt_FD1: 8 GWM
 SG_ GWM_GWOnBoardTester : 39|8@0+ (1,0) [0|255] "unitless"  HCM,CHCM,SOBDMC_HPCM,SIMA_DLCS,CMR_DSMC,ABS_ESC,AWD_DLCM,ECM,ECM_Diesel,ECM_HEV,ECM_HEVDSL,PCM,PCM_HEV,PSCM,TCCM,TCM,TCM_DSL
 SG_ GWM_GWNMProxy : 47|8@0+ (1,0) [0|255] "unitless"  HCM,SIMA_DLCS,CHCM,SOBDMC_HPCM,CMR_DSMC,ABS_ESC,AWD_DLCM,ECM,ECM_Diesel,ECM_HEV,ECM_HEVDSL,PCM,PCM_HEV,PSCM,TCCM,TCM,TCM_DSL
 SG_ GWM_AutoSarNMReserved4 : 63|8@0+ (1,0) [0|255] "unitless"  HCM,SIMA_DLCS,CHCM,SOBDMC_HPCM,CMR_DSMC,ABS_ESC,AWD_DLCM,ECM,ECM_Diesel,ECM_HEV,ECM_HEVDSL,PCM,PCM_HEV,PSCM,TCCM,TCM,TCM_DSL
 SG_ GWM_AutoSarNMReserved3 : 55|8@0+ (1,0) [0|255] "unitless"  HCM,SIMA_DLCS,CHCM,SOBDMC_HPCM,CMR_DSMC,ABS_ESC,AWD_DLCM,ECM,ECM_Diesel,ECM_HEV,ECM_HEVDSL,PCM,PCM_HEV,PSCM,TCCM,TCM,TCM_DSL
 SG_ GWM_AutoSarNMReserved2 : 31|8@0+ (1,0) [0|255] "unitless"  HCM,SIMA_DLCS,CHCM,SOBDMC_HPCM,CMR_DSMC,ABS_ESC,AWD_DLCM,ECM,ECM_Diesel,ECM_HEV,ECM_HEVDSL,PCM,PCM_HEV,PSCM,TCCM,TCM,TCM_DSL
 SG_ GWM_AutoSarNMReserved1 : 23|8@0+ (1,0) [0|255] "unitless"  HCM,SIMA_DLCS,CHCM,SOBDMC_HPCM,CMR_DSMC,ABS_ESC,AWD_DLCM,ECM,ECM_Diesel,ECM_HEV,ECM_HEVDSL,PCM,PCM_HEV,PSCM,TCCM,TCM,TCM_DSL
 SG_ GWM_AutoSarNMNodeId : 7|8@0+ (1,0) [0|255] "unitless"  HCM,SIMA_DLCS,CHCM,SOBDMC_HPCM,CMR_DSMC,ABS_ESC,AWD_DLCM,ECM,ECM_Diesel,ECM_HEV,ECM_HEVDSL,PCM,PCM_HEV,PSCM,TCCM,TCM,TCM_DSL
 SG_ GWM_AutoSarNMControl : 15|8@0+ (1,0) [0|255] "unitless"  HCM,SIMA_DLCS,SOBDMC_HPCM,CMR_DSMC,ABS_ESC,AWD_DLCM,ECM,ECM_Diesel,ECM_HEV,ECM_HEVDSL,PCM,PCM_HEV,PSCM,TCCM,TCM,TCM_DSL

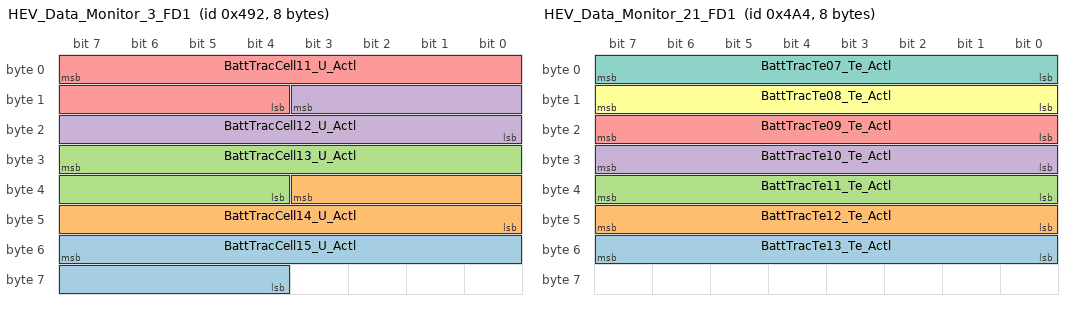
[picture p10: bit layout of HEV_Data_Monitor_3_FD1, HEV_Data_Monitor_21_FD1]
BO_ 1170 HEV_Data_Monitor_3_FD1: 8 BECM
 SG_ BattTracCell15_U_Actl : 55|12@0+ (0.001,1) [1|5.093] "volt"  SOBDMC_HPCM
 SG_ BattTracCell14_U_Actl : 35|12@0+ (0.001,1) [1|5.093] "volt"  SOBDMC_HPCM
 SG_ BattTracCell13_U_Actl : 31|12@0+ (0.001,1) [1|5.093] "volt"  SOBDMC_HPCM
 SG_ BattTracCell12_U_Actl : 11|12@0+ (0.001,1) [1|5.093] "volt"  SOBDMC_HPCM
 SG_ BattTracCell11_U_Actl : 7|12@0+ (0.001,1) [1|5.093] "volt"  SOBDMC_HPCM

BO_ 1191 HEV_Data_Monitor_23_FD1: 8 BECM
 SG_ BattTracTe14_Te_Actl : 7|8@0+ (1,-50) [-50|203] "degC"  SOBDMC_HPCM
 SG_ BattTracTe19_Te_Actl : 47|8@0+ (1,-50) [-50|203] "degC"  SOBDMC_HPCM
 SG_ BattTracTe18_Te_Actl : 39|8@0+ (1,-50) [-50|203] "degC"  SOBDMC_HPCM
 SG_ BattTracTe17_Te_Actl : 31|8@0+ (1,-50) [-50|203] "degC"  SOBDMC_HPCM
 SG_ BattTracTe16_Te_Actl : 23|8@0+ (1,-50) [-50|203] "degC"  SOBDMC_HPCM
 SG_ BattTracTe15_Te_Actl : 15|8@0+ (1,-50) [-50|203] "degC"  SOBDMC_HPCM

BO_ 1190 HEV_Data_Monitor_22_FD1: 8 BECM
 SG_ BattTracUMxArry_No_Actl : 52|5@0+ (1,0) [0|30] "unitless"  SOBDMC_HPCM
 SG_ BattTracCellUMx_No_Actl : 63|8@0+ (1,0) [0|253] "Unitless"  SOBDMC_HPCM
 SG_ BattChrgUMx_B_Falt : 53|1@0+ (1,0) [0|1] "SED"  SOBDMC_HPCM
 SG_ BattTracCellUMn_No_Actl : 15|8@0+ (1,0) [0|253] "Unitless"  SOBDMC_HPCM
 SG_ BattTracCellCnt_No_Actl : 7|8@0+ (1,0) [0|253] "Unitless"  SOBDMC_HPCM
 SG_ BattChrgIsltn_B_Falt : 47|1@0+ (1,0) [0|1] "SED"  SOBDMC_HPCM
 SG_ BattTracCellDiff_B_Falt : 43|1@0+ (1,0) [0|1] "SED"  SOBDMC_HPCM
 SG_ BattChrgSocMx_B_Falt : 44|1@0+ (1,0) [0|1] "SED"  SOBDMC_HPCM
 SG_ BattChrgSocMn_B_Falt : 45|1@0+ (1,0) [0|1] "SED"  SOBDMC_HPCM
 SG_ BattChrgSocErrtc_B_Falt : 46|1@0+ (1,0) [0|1] "SED"  SOBDMC_HPCM
 SG_ BattTracUMx_B_Falt : 54|1@0+ (1,0) [0|1] "SED"  SOBDMC_HPCM
 SG_ BattTracUMn_B_Falt : 55|1@0+ (1,0) [0|1] "SED"  SOBDMC_HPCM
 SG_ BattTracTeMx_No_Actl : 39|8@0+ (1,0) [0|253] "Unitless"  SOBDMC_HPCM
 SG_ BattTracTeMx_B_Falt : 40|1@0+ (1,0) [0|1] "SED"  SOBDMC_HPCM
 SG_ BattTracTeMn_No_Actl : 31|8@0+ (1,0) [0|253] "Unitless"  SOBDMC_HPCM
 SG_ BattTracTeDelta_B_Falt : 41|1@0+ (1,0) [0|1] "SED"  SOBDMC_HPCM
 SG_ BattTracTeCnt_No_Actl : 23|8@0+ (1,0) [0|253] "Unitless"  SOBDMC_HPCM
 SG_ BattTracSoftware_B_Falt : 42|1@0+ (1,0) [0|1] "SED"  SOBDMC_HPCM

BO_ 1188 HEV_Data_Monitor_21_FD1: 8 BECM
 SG_ BattTracTe13_Te_Actl : 55|8@0+ (1,-50) [-50|203] "degC"  SOBDMC_HPCM
 SG_ BattTracTe12_Te_Actl : 47|8@0+ (1,-50) [-50|203] "degC"  SOBDMC_HPCM
 SG_ BattTracTe11_Te_Actl : 39|8@0+ (1,-50) [-50|203] "degC"  SOBDMC_HPCM
 SG_ BattTracTe10_Te_Actl : 31|8@0+ (1,-50) [-50|203] "degC"  SOBDMC_HPCM
 SG_ BattTracTe09_Te_Actl : 23|8@0+ (1,-50) [-50|203] "degC"  SOBDMC_HPCM
 SG_ BattTracTe08_Te_Actl : 15|8@0+ (1,-50) [-50|203] "degC"  SOBDMC_HPCM
 SG_ BattTracTe07_Te_Actl : 7|8@0+ (1,-50) [-50|203] "degC"  SOBDMC_HPCM

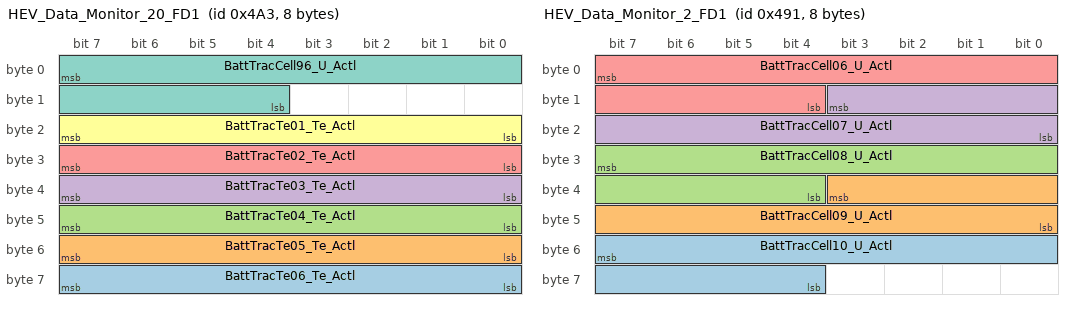
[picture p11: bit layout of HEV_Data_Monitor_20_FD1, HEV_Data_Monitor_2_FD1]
BO_ 1187 HEV_Data_Monitor_20_FD1: 8 BECM
 SG_ BattTracTe06_Te_Actl : 63|8@0+ (1,-50) [-50|203] "degC"  SOBDMC_HPCM
 SG_ BattTracTe05_Te_Actl : 55|8@0+ (1,-50) [-50|203] "degC"  SOBDMC_HPCM
 SG_ BattTracTe04_Te_Actl : 47|8@0+ (1,-50) [-50|203] "degC"  SOBDMC_HPCM
 SG_ BattTracTe03_Te_Actl : 39|8@0+ (1,-50) [-50|203] "degC"  SOBDMC_HPCM
 SG_ BattTracTe02_Te_Actl : 31|8@0+ (1,-50) [-50|203] "degC"  SOBDMC_HPCM
 SG_ BattTracTe01_Te_Actl : 23|8@0+ (1,-50) [-50|203] "degC"  SOBDMC_HPCM
 SG_ BattTracCell96_U_Actl : 7|12@0+ (0.001,1) [1|5.093] "volt"  SOBDMC_HPCM

BO_ 1169 HEV_Data_Monitor_2_FD1: 8 BECM
 SG_ BattTracCell10_U_Actl : 55|12@0+ (0.001,1) [1|5.093] "volt"  SOBDMC_HPCM
 SG_ BattTracCell09_U_Actl : 35|12@0+ (0.001,1) [1|5.093] "volt"  SOBDMC_HPCM
 SG_ BattTracCell08_U_Actl : 31|12@0+ (0.001,1) [1|5.093] "volt"  SOBDMC_HPCM
 SG_ BattTracCell07_U_Actl : 11|12@0+ (0.001,1) [1|5.093] "volt"  SOBDMC_HPCM
 SG_ BattTracCell06_U_Actl : 7|12@0+ (0.001,1) [1|5.093] "volt"  SOBDMC_HPCM

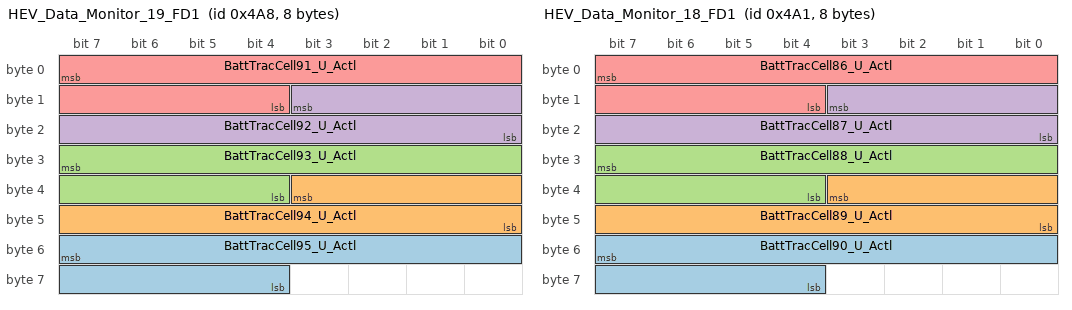
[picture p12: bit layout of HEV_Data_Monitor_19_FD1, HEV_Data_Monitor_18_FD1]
BO_ 1192 HEV_Data_Monitor_19_FD1: 8 BECM
 SG_ BattTracCell95_U_Actl : 55|12@0+ (0.001,1) [1|5.093] "volt"  SOBDMC_HPCM
 SG_ BattTracCell94_U_Actl : 35|12@0+ (0.001,1) [1|5.093] "volt"  SOBDMC_HPCM
 SG_ BattTracCell93_U_Actl : 31|12@0+ (0.001,1) [1|5.093] "volt"  SOBDMC_HPCM
 SG_ BattTracCell92_U_Actl : 11|12@0+ (0.001,1) [1|5.093] "volt"  SOBDMC_HPCM
 SG_ BattTracCell91_U_Actl : 7|12@0+ (0.001,1) [1|5.093] "volt"  SOBDMC_HPCM

BO_ 1185 HEV_Data_Monitor_18_FD1: 8 BECM
 SG_ BattTracCell90_U_Actl : 55|12@0+ (0.001,1) [1|5.093] "volt"  SOBDMC_HPCM
 SG_ BattTracCell89_U_Actl : 35|12@0+ (0.001,1) [1|5.093] "volt"  SOBDMC_HPCM
 SG_ BattTracCell88_U_Actl : 31|12@0+ (0.001,1) [1|5.093] "volt"  SOBDMC_HPCM
 SG_ BattTracCell87_U_Actl : 11|12@0+ (0.001,1) [1|5.093] "volt"  SOBDMC_HPCM
 SG_ BattTracCell86_U_Actl : 7|12@0+ (0.001,1) [1|5.093] "volt"  SOBDMC_HPCM

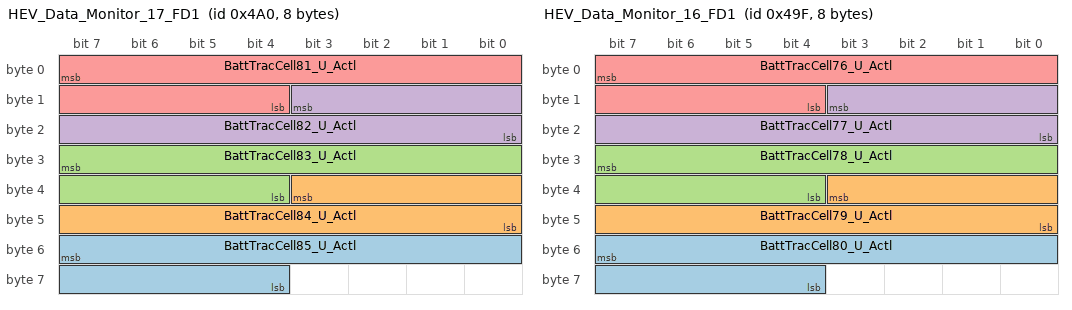
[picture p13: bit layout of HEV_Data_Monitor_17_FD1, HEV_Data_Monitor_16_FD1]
BO_ 1184 HEV_Data_Monitor_17_FD1: 8 BECM
 SG_ BattTracCell85_U_Actl : 55|12@0+ (0.001,1) [1|5.093] "volt"  SOBDMC_HPCM
 SG_ BattTracCell84_U_Actl : 35|12@0+ (0.001,1) [1|5.093] "volt"  SOBDMC_HPCM
 SG_ BattTracCell83_U_Actl : 31|12@0+ (0.001,1) [1|5.093] "volt"  SOBDMC_HPCM
 SG_ BattTracCell82_U_Actl : 11|12@0+ (0.001,1) [1|5.093] "volt"  SOBDMC_HPCM
 SG_ BattTracCell81_U_Actl : 7|12@0+ (0.001,1) [1|5.093] "volt"  SOBDMC_HPCM

BO_ 1183 HEV_Data_Monitor_16_FD1: 8 BECM
 SG_ BattTracCell80_U_Actl : 55|12@0+ (0.001,1) [1|5.093] "volt"  SOBDMC_HPCM
 SG_ BattTracCell79_U_Actl : 35|12@0+ (0.001,1) [1|5.093] "volt"  SOBDMC_HPCM
 SG_ BattTracCell78_U_Actl : 31|12@0+ (0.001,1) [1|5.093] "volt"  SOBDMC_HPCM
 SG_ BattTracCell77_U_Actl : 11|12@0+ (0.001,1) [1|5.093] "volt"  SOBDMC_HPCM
 SG_ BattTracCell76_U_Actl : 7|12@0+ (0.001,1) [1|5.093] "volt"  SOBDMC_HPCM

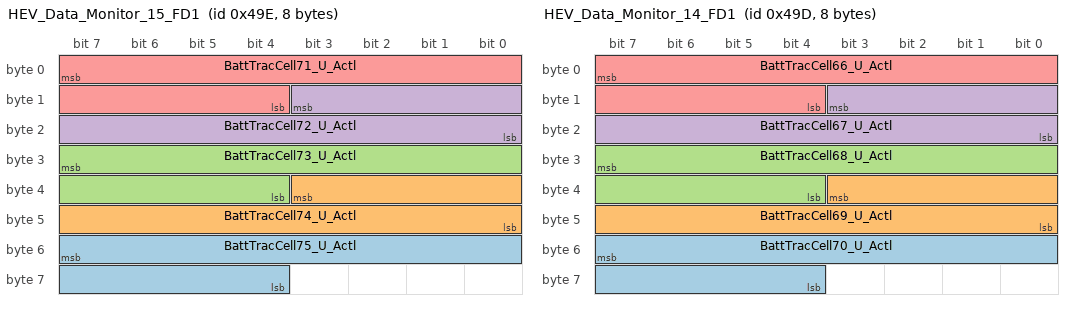
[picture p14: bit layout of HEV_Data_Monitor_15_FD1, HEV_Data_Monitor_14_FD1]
BO_ 1182 HEV_Data_Monitor_15_FD1: 8 BECM
 SG_ BattTracCell75_U_Actl : 55|12@0+ (0.001,1) [1|5.093] "volt"  SOBDMC_HPCM
 SG_ BattTracCell74_U_Actl : 35|12@0+ (0.001,1) [1|5.093] "volt"  SOBDMC_HPCM
 SG_ BattTracCell73_U_Actl : 31|12@0+ (0.001,1) [1|5.093] "volt"  SOBDMC_HPCM
 SG_ BattTracCell72_U_Actl : 11|12@0+ (0.001,1) [1|5.093] "volt"  SOBDMC_HPCM
 SG_ BattTracCell71_U_Actl : 7|12@0+ (0.001,1) [1|5.093] "volt"  SOBDMC_HPCM

BO_ 1181 HEV_Data_Monitor_14_FD1: 8 BECM
 SG_ BattTracCell70_U_Actl : 55|12@0+ (0.001,1) [1|5.093] "volt"  SOBDMC_HPCM
 SG_ BattTracCell69_U_Actl : 35|12@0+ (0.001,1) [1|5.093] "volt"  SOBDMC_HPCM
 SG_ BattTracCell68_U_Actl : 31|12@0+ (0.001,1) [1|5.093] "volt"  SOBDMC_HPCM
 SG_ BattTracCell67_U_Actl : 11|12@0+ (0.001,1) [1|5.093] "volt"  SOBDMC_HPCM
 SG_ BattTracCell66_U_Actl : 7|12@0+ (0.001,1) [1|5.093] "volt"  SOBDMC_HPCM

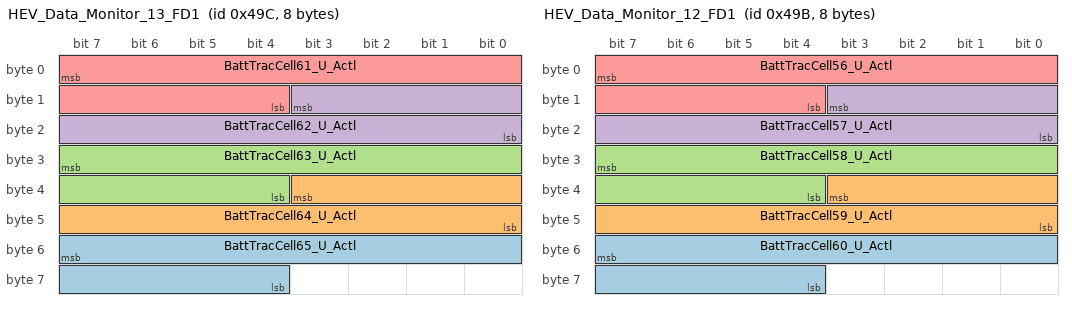
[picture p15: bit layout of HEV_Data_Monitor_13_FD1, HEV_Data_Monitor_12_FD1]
BO_ 1180 HEV_Data_Monitor_13_FD1: 8 BECM
 SG_ BattTracCell65_U_Actl : 55|12@0+ (0.001,1) [1|5.093] "volt"  SOBDMC_HPCM
 SG_ BattTracCell64_U_Actl : 35|12@0+ (0.001,1) [1|5.093] "volt"  SOBDMC_HPCM
 SG_ BattTracCell63_U_Actl : 31|12@0+ (0.001,1) [1|5.093] "volt"  SOBDMC_HPCM
 SG_ BattTracCell62_U_Actl : 11|12@0+ (0.001,1) [1|5.093] "volt"  SOBDMC_HPCM
 SG_ BattTracCell61_U_Actl : 7|12@0+ (0.001,1) [1|5.093] "volt"  SOBDMC_HPCM

BO_ 1179 HEV_Data_Monitor_12_FD1: 8 BECM
 SG_ BattTracCell60_U_Actl : 55|12@0+ (0.001,1) [1|5.093] "volt"  SOBDMC_HPCM
 SG_ BattTracCell59_U_Actl : 35|12@0+ (0.001,1) [1|5.093] "volt"  SOBDMC_HPCM
 SG_ BattTracCell58_U_Actl : 31|12@0+ (0.001,1) [1|5.093] "volt"  SOBDMC_HPCM
 SG_ BattTracCell57_U_Actl : 11|12@0+ (0.001,1) [1|5.093] "volt"  SOBDMC_HPCM
 SG_ BattTracCell56_U_Actl : 7|12@0+ (0.001,1) [1|5.093] "volt"  SOBDMC_HPCM

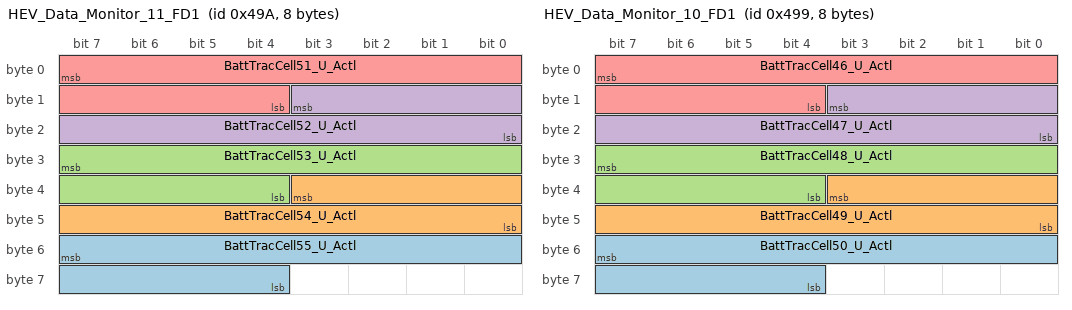
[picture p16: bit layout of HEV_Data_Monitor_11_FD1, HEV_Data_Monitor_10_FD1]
BO_ 1178 HEV_Data_Monitor_11_FD1: 8 BECM
 SG_ BattTracCell55_U_Actl : 55|12@0+ (0.001,1) [1|5.093] "volt"  SOBDMC_HPCM
 SG_ BattTracCell54_U_Actl : 35|12@0+ (0.001,1) [1|5.093] "volt"  SOBDMC_HPCM
 SG_ BattTracCell53_U_Actl : 31|12@0+ (0.001,1) [1|5.093] "volt"  SOBDMC_HPCM
 SG_ BattTracCell52_U_Actl : 11|12@0+ (0.001,1) [1|5.093] "volt"  SOBDMC_HPCM
 SG_ BattTracCell51_U_Actl : 7|12@0+ (0.001,1) [1|5.093] "volt"  SOBDMC_HPCM

BO_ 1177 HEV_Data_Monitor_10_FD1: 8 BECM
 SG_ BattTracCell50_U_Actl : 55|12@0+ (0.001,1) [1|5.093] "volt"  SOBDMC_HPCM
 SG_ BattTracCell49_U_Actl : 35|12@0+ (0.001,1) [1|5.093] "volt"  SOBDMC_HPCM
 SG_ BattTracCell48_U_Actl : 31|12@0+ (0.001,1) [1|5.093] "volt"  SOBDMC_HPCM
 SG_ BattTracCell47_U_Actl : 11|12@0+ (0.001,1) [1|5.093] "volt"  SOBDMC_HPCM
 SG_ BattTracCell46_U_Actl : 7|12@0+ (0.001,1) [1|5.093] "volt"  SOBDMC_HPCM

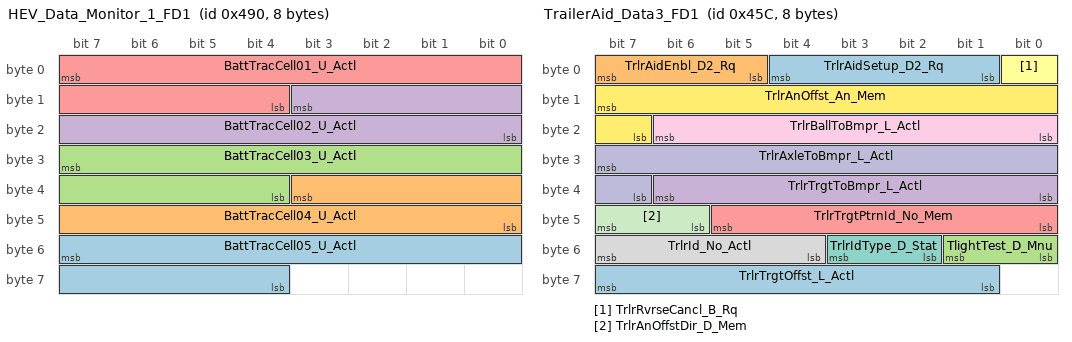
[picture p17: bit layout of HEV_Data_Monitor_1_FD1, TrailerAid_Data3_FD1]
BO_ 1168 HEV_Data_Monitor_1_FD1: 8 BECM
 SG_ BattTracCell05_U_Actl : 55|12@0+ (0.001,1) [1|5.093] "volt"  SOBDMC_HPCM
 SG_ BattTracCell04_U_Actl : 35|12@0+ (0.001,1) [1|5.093] "volt"  SOBDMC_HPCM
 SG_ BattTracCell03_U_Actl : 31|12@0+ (0.001,1) [1|5.093] "volt"  SOBDMC_HPCM
 SG_ BattTracCell02_U_Actl : 11|12@0+ (0.001,1) [1|5.093] "volt"  SOBDMC_HPCM
 SG_ BattTracCell01_U_Actl : 7|12@0+ (0.001,1) [1|5.093] "volt"  SOBDMC_HPCM

BO_ 1245 DrivelineCstmFeatures: 8 GWM
 SG_ RearDiffLckLamp_D_Cstm : 13|2@0+ (1,0) [0|3] "SED"  AWD_DLCM
 SG_ FrontDiffLckLamp_D_Cstm : 15|2@0+ (1,0) [0|3] "SED"  AWD_DLCM,TCCM
 SG_ AwdMdeCstm_D_RqDrv : 7|3@0+ (1,0) [0|7] "SED"  AWD_DLCM,TCCM
 SG_ SelDrvMdeAwd2_D_Cstm : 4|5@0+ (1,0) [0|31] "SED"  AWD_DLCM,TCCM

BO_ 1242 PowertrainCstmData: 8 GWM
 SG_ SelDrvMdeCstmPt_D_Rq : 4|5@0+ (1,0) [0|31] "SED"  ECM_Diesel,ECM_HEV,ECM_HEVDSL,PCM_HEV,ECM,PCM
 SG_ EngExhMdeQuietCstm_D_Rq : 7|3@0+ (1,0) [0|7] "SED"  PCM_HEV,ECM_HEVDSL,ECM_HEV,ECM_Diesel,ECM,PCM
 SG_ StopStrtCstm_D_Rq : 15|2@0+ (1,0) [0|3] "SED"  ECM_HEV,PCM_HEV,ECM_Diesel,ECM_HEVDSL,ECM,PCM

BO_ 1116 TrailerAid_Data3_FD1: 8 APIM
 SG_ TrlrAidSetup_D2_Rq : 4|4@0+ (1,0) [0|15] "SED"  IPMA_ADAS,PSCM
 SG_ TrlrAidEnbl_D2_Rq : 7|3@0+ (1,0) [0|7] "SED"  PSCM,IPMA_ADAS
 SG_ TlightTest_D_Mnu : 49|2@0+ (1,0) [0|3] "SED"  GENERIC
 SG_ TrlrTrgtToBmpr_L_Actl : 38|7@0+ (0.0127,0) [0|1.6129] "meter"  IPMA_ADAS,PSCM
 SG_ TrlrTrgtPtrnId_No_Mem : 45|6@0+ (1,0) [0|63] "unitless"  IPMA_ADAS
 SG_ TrlrRvrseCancl_B_Rq : 0|1@0+ (1,0) [0|1] "SED"  IPMA_ADAS,PSCM
 SG_ TrlrIdType_D_Stat : 51|2@0+ (1,0) [0|3] "SED"  IPMA_ADAS,PSCM
 SG_ TrlrId_No_Actl : 55|4@0+ (1,0) [0|15] "unitless"  IPMA_ADAS,PSCM
 SG_ TrlrBallToBmpr_L_Actl : 22|7@0+ (0.0127,0) [0|1.6129] "meter"  IPMA_ADAS,PSCM
 SG_ TrlrAxleToBmpr_L_Actl : 31|9@0+ (0.0254,0) [0|12.9794] "meter"  IPMA_ADAS,PSCM
 SG_ TrlrAnOffstDir_D_Mem : 47|2@0+ (1,0) [0|3] "SED"  IPMA_ADAS,PSCM
 SG_ TrlrAnOffst_An_Mem : 15|9@0+ (0.1,0) [0|51.1] "degrees"  IPMA_ADAS,PSCM
 SG_ TrlrTrgtOffst_L_Actl : 63|7@0+ (0.0127,0) [0|1.6129] "meter"  PSCM,IPMA_ADAS

BO_ 1844 TesterPhysicalReqHCM: 64 TSTR
 SG_ TesterPhysicalReqHCM : 7|64@0+ (1,0) [0|1.84467E+019] "unitless"  HCM

BO_ 954 Body_Info_10_FD1: 8 BCM
 SG_ ExtLghtFront_D_RqBody : 61|2@0+ (1,0) [0|3] "SED"  HCM
 SG_ VehWlcmFrwlMde_D_Stat : 29|3@0+ (1,0) [0|7] "SED"  ABS_ESC,HCM,SIMA_DLCS
 SG_ CrtsyLghtRear_D_Stat : 63|2@0+ (1,0) [0|3] "SED"  GENERIC
 SG_ TrlrHitchLamp_D2_Stat : 57|2@0+ (1,0) [0|3] "SED" Vector__XXX
 SG_ ChildLckMaint_D_Stat : 59|2@0+ (1,0) [0|3] "SED"  IPMA_ADAS
 SG_ GenericSwtch3_No_Actl : 15|3@0+ (1,0) [0|7] "unitless"  PCM,HCM,GENERIC
 SG_ GenericSwtch2_No_Actl : 4|3@0+ (1,0) [0|7] "unitless"  PCM,PCM_HEV,TCM_DSL,HCM
 SG_ GenericSwtch1_No_Actl : 7|3@0+ (1,0) [0|7] "unitless"  HCM,GENERIC
 SG_ PosLghtFl_D_Stat : 51|2@0+ (1,0) [0|3] "SED"  HCM
 SG_ PosLghtFr_D_Stat : 49|2@0+ (1,0) [0|3] "SED"  HCM
 SG_ PudSptLghtRight_D_Rq : 17|2@0+ (1,0) [0|3] "SED"  GENERIC
 SG_ PudSptLghtLeft_D_Rq : 19|2@0+ (1,0) [0|3] "SED"  GENERIC
 SG_ ExtLghtRight_D_Stat : 21|2@0+ (1,0) [0|3] "SED"  GENERIC
 SG_ ExtLghtRear_D_Stat : 23|2@0+ (1,0) [0|3] "SED"  GENERIC
 SG_ ExtLghtLeft_D_Stat : 9|2@0+ (1,0) [0|3] "SED"  GENERIC
 SG_ ExtLghtFront_D_Stat : 11|2@0+ (1,0) [0|3] "SED"  GENERIC
 SG_ CargoLght_D_Stat : 55|2@0+ (1,0) [0|3] "SED" Vector__XXX
 SG_ TlghtTestLght_D_Stat : 44|3@0+ (1,0) [0|7] "SED"  GENERIC
 SG_ LghtAmbDrvMde_B_Stat : 34|1@0+ (1,0) [0|1] "SED"  GENERIC
 SG_ KeylessIdl_B_Stat : 41|1@0+ (1,0) [0|1] "SED"  GENERIC
 SG_ PwRnngBoardPoll_D_Stat : 36|2@0+ (1,0) [0|3] "SED"  GENERIC
 SG_ PoliceDmngLvl_D_Stat : 39|3@0+ (1,0) [0|7] "SED"  GENERIC
 SG_ TrlrHitchLamp_D_Stat : 25|1@0+ (1,0) [0|1] "SED"  GENERIC
 SG_ LicPlateLght_B_Stat : 26|1@0+ (1,0) [0|1] "SED"  GENERIC
 SG_ TrukBedLght_B_Stat : 24|1@0+ (1,0) [0|1] "SED"  GENERIC
 SG_ VehWlcmFrwl_D_Stat : 31|2@0+ (1,0) [0|3] "SED"  HCM,SIMA_DLCS
 SG_ TlghtTestPrecnd_D_Stat : 47|3@0+ (1,0) [0|7] "SED"  GENERIC
 SG_ TlghtTest_D_Stat : 33|2@0+ (1,0) [0|3] "SED"  GENERIC
 SG_ ExtLghtAlrt_B_Rq : 12|1@0+ (1,0) [0|1] "SED"  GENERIC
 SG_ ExtLght_D_Falt : 1|2@0+ (1,0) [0|3] "SED"  GENERIC

BO_ 1852 TesterPhysicalResHCM: 64 HCM
 SG_ TesterPhysicalResHCM : 7|64@0+ (1,0) [0|1.84467E+019] "unitless"  TSTR

BO_ 989 Personality_HCM_Data: 8 HCM
 SG_ FeatNoHcm_No_Actl : 23|16@0+ (1,0) [0|65535] "Number"  GWM
 SG_ FeatConfigHcmActl : 7|16@0+ (1,0) [0|65535] "Undefined"  GWM

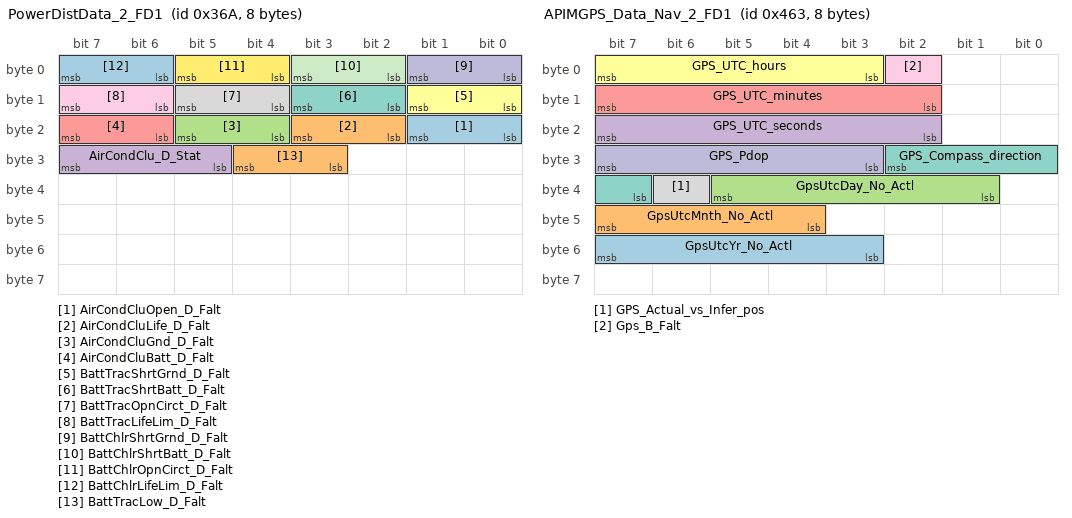
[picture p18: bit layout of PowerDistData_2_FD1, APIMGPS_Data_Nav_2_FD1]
BO_ 874 PowerDistData_2_FD1: 8 BCMC_CPDB
 SG_ AirCondCluOpen_D_Falt : 17|2@0+ (1,0) [0|3] "SED"  ECM_Diesel,ECM_HEVDSL,PCM
 SG_ AirCondCluLife_D_Falt : 19|2@0+ (1,0) [0|3] "SED"  ECM_Diesel,ECM_HEVDSL,PCM
 SG_ AirCondCluGnd_D_Falt : 21|2@0+ (1,0) [0|3] "SED"  ECM_Diesel,ECM_HEVDSL,PCM
 SG_ AirCondClu_D_Stat : 31|3@0+ (1,0) [0|7] "SED"  ECM_Diesel,ECM_HEVDSL,PCM
 SG_ AirCondCluBatt_D_Falt : 23|2@0+ (1,0) [0|3] "SED"  ECM_Diesel,ECM_HEVDSL,PCM
 SG_ BattTracShrtGrnd_D_Falt : 9|2@0+ (1,0) [0|3] "SED"  SOBDMC_HPCM,GENERIC,BCMD_IPDB
 SG_ BattTracShrtBatt_D_Falt : 11|2@0+ (1,0) [0|3] "SED"  SOBDMC_HPCM,GENERIC,BCMD_IPDB
 SG_ BattTracOpnCirct_D_Falt : 13|2@0+ (1,0) [0|3] "SED"  SOBDMC_HPCM,GENERIC,BCMD_IPDB
 SG_ BattTracLifeLim_D_Falt : 15|2@0+ (1,0) [0|3] "SED"  SOBDMC_HPCM,GENERIC,BCMD_IPDB
 SG_ BattChlrShrtGrnd_D_Falt : 1|2@0+ (1,0) [0|3] "SED"  SOBDMC_HPCM,GENERIC,BCMD_IPDB
 SG_ BattChlrShrtBatt_D_Falt : 3|2@0+ (1,0) [0|3] "SED"  SOBDMC_HPCM,GENERIC,BCMD_IPDB
 SG_ BattChlrOpnCirct_D_Falt : 5|2@0+ (1,0) [0|3] "SED"  SOBDMC_HPCM,GENERIC,BCMD_IPDB
 SG_ BattChlrLifeLim_D_Falt : 7|2@0+ (1,0) [0|3] "SED"  SOBDMC_HPCM,GENERIC,BCMD_IPDB
 SG_ BattTracLow_D_Falt : 28|2@0+ (1,0) [0|3] "SED"  SOBDMC_HPCM,BCMD_IPDB

BO_ 551 APIM_Request_Signals_1_FD1: 8 APIM_CISM
 SG_ PrkBrkPerfMnuOn_D_Stat : 1|2@0+ (1,0) [0|3] "SED"  ABS_ESC
 SG_ PrkBrkPerfButtn_D_Stat : 3|2@0+ (1,0) [0|3] "SED"  ABS_ESC
 SG_ TjaLaneBiasEnbl_D_RqMnu : 5|2@0+ (1,0) [0|3] "SED"  IPMA_ADAS
 SG_ VehPerfDemo_B_RqDrv : 8|1@0+ (1,0) [0|1] "SED"  SOBDMC_HPCM
 SG_ Rba_D_Rq : 31|2@0+ (1,0) [0|3] "SED"  IPMA_ADAS
 SG_ EmPrflNo_D_Rq : 61|3@0+ (1,0) [0|7] "SED"  GENERIC
 SG_ EmPrflButtnAssoc_D_Rq : 33|2@0+ (1,0) [0|3] "SED"  GENERIC
 SG_ EmPrflKeyAssoc_D_Rq : 46|3@0+ (1,0) [0|7] "SED"  GENERIC
 SG_ Em_D_Stat : 63|2@0+ (1,0) [0|3] "SED"  GENERIC
 SG_ ChrgOvrdExitScrn_D_Rq : 58|2@0+ (1,0) [0|3] "SED"  GENERIC
 SG_ PrcondEdit_D_RqMnu : 15|3@0+ (1,0) [0|7] "SED"  SOBDMC_HPCM
 SG_ ChrgToPcEdit_Pc_RqMnu : 23|7@0+ (1,0) [0|125] "percent"  SOBDMC_HPCM
 SG_ EcoIdl_D_Rq : 7|2@0+ (1,0) [0|3] "SED"  PCM_HEV,SOBDMC_HPCM
 SG_ PmCabnLvl_D_Stat : 36|3@0+ (1,0) [0|7] "SED"  GENERIC
 SG_ PmCabn_D_Stat : 38|2@0+ (1,0) [0|3] "SED"  GENERIC
 SG_ PwRnngBoardSwtch_D_Rq : 27|2@0+ (1,0) [0|3] "SED"  GENERIC
 SG_ PwRnngBoardMde_D_Rq : 29|2@0+ (1,0) [0|3] "SED"  GENERIC
 SG_ PwRnngBoardT_D_Rq : 25|2@0+ (1,0) [0|3] "SED"  GENERIC
 SG_ OneTEditActv_B_RqMnu : 40|1@0+ (1,0) [0|1] "SED"  SOBDMC_HPCM
 SG_ GoTElementEdit_No_RqMnu : 12|4@0+ (1,0) [0|15] "unitless"  SOBDMC_HPCM
 SG_ Cntr_Plg_Mode_Cmd : 39|1@0+ (1,0) [0|1] "SED"  GENERIC
 SG_ BattTracLoThres_D_Rq : 43|3@0+ (1,0) [0|7] "SED"  SOBDMC_HPCM
 SG_ ChrgCrdLckEnbl_B_Stat : 47|1@0+ (1,0) [0|1] "SED"  GENERIC
 SG_ Btt_L_Actl2 : 55|7@0+ (0.1,0) [0|12.5] "meter"  IPMA_ADAS

BO_ 132 GlobalClock_Data_FD1: 8 BCM
 SG_ GlblClkYr_No_Actl : 7|8@0+ (1,2000) [2000|2255] "year"  ECM_Diesel,SOBDMC_HPCM,IPMA_ADAS,CMR_DSMC
 SG_ GlblClkScnd_No_Actl : 47|8@0+ (1,0) [0|255] "second"  SOBDMC_HPCM,IPMA_ADAS,CMR_DSMC
 SG_ GlblClkMnte_No_Actl : 39|8@0+ (1,0) [0|255] "minute"  SOBDMC_HPCM,IPMA_ADAS,CMR_DSMC
 SG_ GlblClkHr_No_Actl : 55|8@0+ (1,0) [0|255] "hour"  PCM,SOBDMC_HPCM,IPMA_ADAS,CMR_DSMC,ECM
 SG_ GlblClkDay_No_Actl : 23|16@0+ (1,0) [0|65535] "julian day"  ECM_Diesel,SOBDMC_HPCM,IPMA_ADAS,CMR_DSMC

BO_ 1006 Personality_IPMB_Data: 8 IPMA_ADAS
 SG_ PersIndexIpmb_D_Actl : 39|3@0+ (1,0) [0|7] "SED"  GWM
 SG_ FeatNoIpmbActl : 23|16@0+ (1,0) [0|65535] "Number"  GWM
 SG_ FeatConfigIpmbActl : 7|16@0+ (1,0) [0|65535] "Undefined"  GWM

BO_ 1123 APIMGPS_Data_Nav_2_FD1: 8 APIM
 SG_ GpsUtcYr_No_Actl : 55|5@0+ (1,2010) [2010|2040] "Year"  SOBDMC_HPCM,IPMA_ADAS
 SG_ GpsUtcMnth_No_Actl : 47|4@0+ (1,1) [1|15] "Month"  SOBDMC_HPCM,IPMA_ADAS
 SG_ GpsUtcDay_No_Actl : 37|5@0+ (1,1) [1|32] "Day"  SOBDMC_HPCM,IPMA_ADAS
 SG_ GPS_UTC_seconds : 23|6@0+ (1,0) [0|59] "seconds"  SOBDMC_HPCM,IPMA_ADAS
 SG_ GPS_UTC_minutes : 15|6@0+ (1,0) [0|59] "Minutes"  SOBDMC_HPCM,IPMA_ADAS
 SG_ GPS_UTC_hours : 7|5@0+ (1,0) [0|23] "Hours"  SOBDMC_HPCM,IPMA_ADAS
 SG_ GPS_Compass_direction : 26|4@0+ (1,0) [0|15] "SED"  SOBDMC_HPCM,IPMA_ADAS
 SG_ GPS_Actual_vs_Infer_pos : 38|1@0+ (1,0) [0|1] "SED"  SOBDMC_HPCM,IPMA_ADAS
 SG_ Gps_B_Falt : 2|1@0+ (1,0) [0|1] "SED"  SOBDMC_HPCM,IPMA_ADAS
 SG_ GPS_Pdop : 31|5@0+ (0.2,0) [0|5.8] "unitless"  IPMA_ADAS,SOBDMC_HPCM

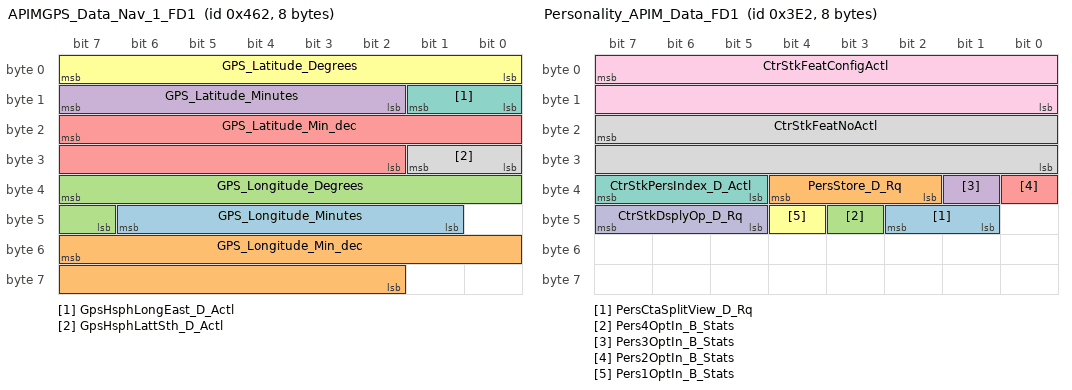
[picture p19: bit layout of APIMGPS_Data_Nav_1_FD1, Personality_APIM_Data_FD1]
BO_ 1122 APIMGPS_Data_Nav_1_FD1: 8 APIM
 SG_ GPS_Longitude_Minutes : 46|6@0+ (1,0) [0|61] "Minutes"  SOBDMC_HPCM,IPMA_ADAS
 SG_ GPS_Longitude_Min_dec : 55|14@0+ (0.0001,0) [0|1.6381] "Minutes"  SOBDMC_HPCM,IPMA_ADAS
 SG_ GPS_Longitude_Degrees : 39|9@0+ (1,-179) [-179|330] "Degrees"  SOBDMC_HPCM,IPMA_ADAS
 SG_ GPS_Latitude_Minutes : 15|6@0+ (1,0) [0|61] "Minutes"  SOBDMC_HPCM,IPMA_ADAS
 SG_ GPS_Latitude_Min_dec : 23|14@0+ (0.0001,0) [0|1.6381] "Minutes"  SOBDMC_HPCM,IPMA_ADAS
 SG_ GPS_Latitude_Degrees : 7|8@0+ (1,-89) [-89|164] "Degrees"  SOBDMC_HPCM,IPMA_ADAS
 SG_ GpsHsphLongEast_D_Actl : 9|2@0+ (1,0) [0|3] "SED"  SOBDMC_HPCM,IPMA_ADAS
 SG_ GpsHsphLattSth_D_Actl : 25|2@0+ (1,0) [0|3] "SED"  SOBDMC_HPCM,IPMA_ADAS

BO_ 1003 Personality_BCM2_Data_FD1: 8 BCM
 SG_ TailLghtLoadMde_D_Stat : 60|3@0+ (1,0) [0|7] "SED"  GENERIC
 SG_ PersRecallSrc_D_Actl : 63|3@0+ (1,0) [0|7] "SED"  GENERIC
 SG_ Pers4Key_D_Stat : 49|2@0+ (1,0) [0|3] "SED"  GENERIC
 SG_ Pers3Key_D_Stat : 41|2@0+ (1,0) [0|3] "SED"  GENERIC
 SG_ Pers2Key_D_Stat : 43|2@0+ (1,0) [0|3] "SED"  GENERIC
 SG_ Pers1Key_D_Stat : 12|2@0+ (1,0) [0|3] "SED"  GENERIC
 SG_ EmPrflNo_D_Stat : 52|3@0+ (1,0) [0|7] "SED"  GENERIC
 SG_ EmPrflKeyAssoc_D_Stat : 55|3@0+ (1,0) [0|7] "SED"  GENERIC
 SG_ VehKeyActv_D_Stat : 47|4@0+ (1,0) [0|15] "SED"  SOBDMC_HPCM,HCM,GENERIC
 SG_ PersNoPos_D_Actl : 18|3@0+ (1,0) [0|7] "SED"  HCM,VDM,GENERIC
 SG_ PersSetupRestr_D_Actl : 21|2@0+ (1,0) [0|3] "SED"  SOBDMC_HPCM,HCM,VDM,GENERIC
 SG_ PersSetupAccessCtrl : 19|1@0+ (1,0) [0|1] "SED"  SOBDMC_HPCM,HCM,VDM,GENERIC
 SG_ PersSetup_No_Actl : 31|16@0+ (1,0) [0|65535] "Number"  SOBDMC_HPCM,HCM,VDM,GENERIC
 SG_ PersConflict_D_Actl : 22|1@0+ (1,0) [0|1] "SED"  HCM,GENERIC
 SG_ AssocConfirm_D_Actl : 15|3@0+ (1,0) [0|7] "SED"  HCM,GENERIC
 SG_ RecallEvent_No_Cnt : 7|8@0+ (1,0) [0|255] "Counts"  HCM,VDM,IPMA_ADAS
 SG_ PersNo_D_Actl : 10|3@0+ (1,0) [0|7] "SED"  ECM_HEV,SOBDMC_HPCM,HCM,VDM,IPMA_ADAS,ABS_ESC

BO_ 580 Battery_Traction_11_FD1: 8 BECM
 SG_ BattTracVrtOck_B_Rq : 7|1@0+ (1,0) [0|1] "SED"  SOBDMC_HPCM

BO_ 994 Personality_APIM_Data_FD1: 8 APIM
 SG_ PersCtaSplitView_D_Rq : 42|2@0+ (1,0) [0|3] "SED"  IPMA_ADAS
 SG_ PersStore_D_Rq : 36|3@0+ (1,0) [0|7] "SED"  GENERIC
 SG_ Pers4OptIn_B_Stats : 43|1@0+ (1,0) [0|1] "SED"  GENERIC
 SG_ Pers3OptIn_B_Stats : 33|1@0+ (1,0) [0|1] "SED"  GENERIC
 SG_ Pers2OptIn_B_Stats : 32|1@0+ (1,0) [0|1] "SED"  GENERIC
 SG_ Pers1OptIn_B_Stats : 44|1@0+ (1,0) [0|1] "SED"  GENERIC
 SG_ CtrStkPersIndex_D_Actl : 39|3@0+ (1,0) [0|7] "SED"  ECM_HEV,ABS_ESC,SOBDMC_HPCM,HCM,VDM,IPMA_ADAS
 SG_ CtrStkFeatNoActl : 23|16@0+ (1,0) [0|65535] "Undefined"  ECM_HEV,PCM,ABS_ESC,SOBDMC_HPCM,HCM,VDM,IPMA_ADAS
 SG_ CtrStkFeatConfigActl : 7|16@0+ (1,0) [0|65535] "Undefined"  ECM_HEV,PCM,ABS_ESC,SOBDMC_HPCM,HCM,VDM,IPMA_ADAS
 SG_ CtrStkDsplyOp_D_Rq : 47|3@0+ (1,0) [0|7] "SED"  ECM_HEV,PCM,ABS_ESC,SOBDMC_HPCM,HCM,VDM,IPMA_ADAS

BO_TX_BU_ 466 : PCM_HEV,PCM,ECM_HEV,ECM_Diesel,ECM;

CM_ "FNV2 FD1 CAN";
CM_ BU_ TCM "Transmission Control Module";
CM_ BU_ HCM "Headlamp Ctrl. Mod.A (HS_CAN), Adaptive Headlamps";
CM_ BU_ IPMA_ADAS "Assist Driving Alert System";
CM_ BU_ PSCM "Power Steering Control Module";
CM_ BU_ ABS_ESC "Anti-lock Brake / Traction Control Module";
CM_ BU_ TCCM "Transfer Case Control Module, 4x4 Control Module";
CM_ BU_ TCM_DSL "Transmission Control Module";
CM_ BU_ PCM_HEV "PCM HEV";
CM_ BU_ PCM "Powertrain Control Module";
CM_ BU_ ECM_HEVDSL "HEV Diesel ";
CM_ BU_ ECM_HEV "HEV ECM";
CM_ BU_ ECM_Diesel "Diesel";
CM_ BU_ ECM "Gas FD";
CM_ BU_ SIMA_DLCS "Switch Input Module A - Driveline Chassis Switch";
CM_ BU_ BCMD_IPDB "IPDB Interior Power Distribtuion Box";
CM_ BU_ VDM "Vehicle Dynamics Control Module";
CM_ BU_ CMR_DSMC "Driver Status Monitor Camera";
CM_ BU_ CHCM "Chassis Control Module Stabilizer bar disconnect module ";
CM_ BU_ GWM "Gateway Module CGEA1.3(Star Architecture)";
CM_ BU_ AWD_DLCM "Differential Lock Control module";
CM_ BU_ GENERIC "holding pattern ECU for developmental messages";
CM_ BU_ TSTR "Diagnostic Tester";
CM_ BO_ 932 "NOTE: START BITS 8-11 MUST BE OPEN SPEC REQUIREMENT";
CM_ SG_ 932 CanMsg3A4_No_Crc "Signal not transmitted on gas and HEV variants.";
CM_ SG_ 932 CanMsg3A4_No_Cnt "Signal not transmitted on gas and HEV variants.";
CM_ SG_ 368 PrplBrkTqCtl_No_Cs "Signal not transmitted on gas variants.";
CM_ SG_ 612 SelDrvMdeSwtch_D_Stat6 "ECM_HEV does not support or Transmit signal.";
CM_ BO_ 986 "APIM Tx";
CM_ SG_ 954 GenericSwtch2_No_Actl "U625 Police Wig Wag feature";
CM_ BO_ 1123 "HS3 APIM Sync Gen3 Tx 0x463.  FrameGateway to 0x466 on HS1, HS2, HS3 and MS1.";
CM_ BO_ 1122 "HS3 APIM Sync Gen3 Tx 0x462.  FrameGateway to 0x465 on HS1, HS2, HS3 and MS1.";
BA_DEF_ BO_  "VFrameFormat" ENUM  "StandardCAN","ExtendedCAN","reserved","reserved","reserved","reserved","reserved","reserved","reserved","reserved","reserved","reserved","reserved","reserved","StandardCAN_FD","ExtendedCAN_FD";
BA_DEF_  "BusType" STRING ;
BA_DEF_ SG_  "GenSigSendType" ENUM  "Cyclic","OnWrite","vector_leerstring","OnChange","vector_leerstring","IfActive","vector_leerstring","NoSigSendType";
BA_DEF_ SG_  "GenSigInactiveValue" INT 0 100000;
BA_DEF_ SG_  "WakeupSignal" ENUM  "No","Yes";
BA_DEF_ SG_  "UsedOnPgmDBC" ENUM  "No","Yes";
BA_DEF_ SG_  "GenSigStartValueInteger" INT 0 1000000000;
BA_DEF_ SG_  "ContentDependant" ENUM  "No","Yes";
BA_DEF_ SG_  "MetaData" ENUM  "No","Yes";
BA_DEF_ SG_  "GenSigStartValue" HEX 0 268435455;
BA_DEF_ SG_  "U_CX727_MY2021_Rx" ENUM  "No","Yes";
BA_DEF_ SG_  "U_P702_MY2021_Rx" ENUM  "No","Yes";
BA_DEF_ SG_  "U_T6_MCA_MY2020_Rx" ENUM  "No","Yes";
BA_DEF_ SG_  "ECGUsedRxSignal" ENUM  "No","Yes";
BA_DEF_ SG_  "U_CD542_MY2021_Rx" ENUM  "No","Yes";
BA_DEF_ SG_  "U_U55X_MY2022_Rx" ENUM  "No","Yes";
BA_DEF_ SG_  "U_CD764_MY2022_Rx" ENUM  "No","Yes";
BA_DEF_ SG_  "U_CDX706_MY2023_Rx" ENUM  "No","Yes";
BA_DEF_ SG_  "U_CX727_MY2021_Tx" ENUM  "No","Yes";
BA_DEF_ SG_  "U_P702_MY2021_Tx" ENUM  "No","Yes";
BA_DEF_ SG_  "U_T6_MCA_MY2020_Tx" ENUM  "No","Yes";
BA_DEF_ SG_  "ECGUsedTxSignal" ENUM  "No","Yes";
BA_DEF_ SG_  "U_CD542_MY2021_Tx" ENUM  "No","Yes";
BA_DEF_ SG_  "U_U55X_MY2022_Tx" ENUM  "No","Yes";
BA_DEF_ SG_  "U_CD764_MY2022_Tx" ENUM  "No","Yes";
BA_DEF_ SG_  "U_CDX706_MY2023_Tx" ENUM  "No","Yes";
BA_DEF_ BO_  "GenMsgILSupport" ENUM  "No","Yes";
BA_DEF_ BO_  "DiagResponse" ENUM  "No","Yes";
BA_DEF_ BO_  "DiagRequest" ENUM  "No","Yes";
BA_DEF_ BO_  "TpTxIndex" INT 0 536870911;
BA_DEF_ BO_  "DiagState" ENUM  "No","Yes";
BA_DEF_ BO_  "TpApplType" STRING ;
BA_DEF_ BO_  "NmAsrMessage" ENUM  "No","Yes";
BA_DEF_ BO_  "ProgBWConditional" STRING ;
BA_DEF_ BO_  "SCP_AuthInfoTxLength" INT 0 512;
BA_DEF_ BO_  "SCP_FreshnessValueTxLength" INT 0 512;
BA_DEF_ BO_  "SCP_FreshnessValueLength" INT 0 512;
BA_DEF_ BO_  "OvtpPushApplication" ENUM  "FALSE","TRUE";
BA_DEF_ BO_  "GenMsgSendType" ENUM  "FixedPeriodic","Event","EnabledPeriodic","NotUsed","NotUsed","EventPeriodic","NotUsed","NotUsed","NoMsgSendType";
BA_DEF_ BO_  "GenMsgCycleTime" INT 0 100000;
BA_DEF_ BO_  "GenMsgDelayTime" INT 0 1000;
BA_DEF_ BO_  "GenMsgNrOfRepetition" INT 0 100;
BA_DEF_ BO_  "GenMsgStartDelayTime" INT 0 10000;
BA_DEF_ BO_  "EventRateOfChange" INT 10 10000;
BA_DEF_ BO_  "FrameGatewayId" HEX 0 1407;
BA_DEF_ BO_  "NetworkInitialization" ENUM  "No","Yes";
BA_DEF_ BO_  "FrameGatewayNetwork" STRING ;
BA_DEF_ BO_  "FrameRouting" STRING ;
BA_DEF_ BU_  "GatewayECU" ENUM  "No","Yes";
BA_DEF_ BU_  "PackageID" STRING ;
BA_DEF_ BU_  "NosPackage" ENUM  "None","I3_1","I3_2","1.0.1","RP","EuCD","Volcano","I3_3","FNOS_Autosar";
BA_DEF_ BU_  "NmStationAddress" INT 0 255;
BA_DEF_ BU_  "EOL_SB_Flash" ENUM  "GGDS","GDS","NONE","vector_leerstring";
BA_DEF_ BU_  "DiagNode" ENUM  "GGDS","GDS","NONE";
BA_DEF_ BU_  "PowerType" ENUM  "Switched","Latched","Sleep","vector_leerstring","vector_leerstring";
BA_DEF_ BU_  "NmAsrNode" ENUM  "No","Yes";
BA_DEF_ BU_  "NmAsrNodeIdentifier" HEX 0 255;
BA_DEF_ BU_  "NodeStartUpTime" INT 0 10000;
BA_DEF_ BU_  "NodeWakeUpTime" INT 0 10000;
BA_DEF_ BU_  "Terminator" ENUM  "No","Yes";
BA_DEF_ BU_  "ILUsed" ENUM  "No","Yes";
BA_DEF_ BU_  "OvtpEcuAddress" INT 0 1022;
BA_DEF_ BU_  "OvtpOperationMode" ENUM  "SERVER","CLIENT";
BA_DEF_  "NmMessageCount" INT 0 128;
BA_DEF_  "NmBaseAddress" HEX 1280 1280;
BA_DEF_  "VersionYear" INT 2000 3000;
BA_DEF_  "VersionMonth" INT 1 12;
BA_DEF_  "Manufacturer" STRING ;
BA_DEF_  "VersionDay" INT 1 31;
BA_DEF_  "DBName" STRING ;
BA_DEF_  "NmAsrBaseAddress" HEX 1280 1408;
BA_DEF_  "NmAsrMessageCount" INT 128 256;
BA_DEF_  "NmType" STRING ;
BA_DEF_  "CMDB_Version" STRING ;
BA_DEF_  "StarNetworkGwType" ENUM  "0=NotDefined","1=HS1","2=HS2","3=HS3","4=HS4","5=HS5","6=MS1","7=HS6","8=HS7","9=MS2","10=FD1","11=FD2","12=FD3","13=FD4","14=FD5","15=FD6","16=FD7","17=FD8";
BA_DEF_  "VersionNumber" INT 0 10000;
BA_DEF_  "NetworkSpeed" ENUM  "500kBits/s","125kBit/s";
BA_DEF_DEF_  "VFrameFormat" "ExtendedCAN_FD";
BA_DEF_DEF_  "BusType" "";
BA_DEF_DEF_  "GenSigSendType" "NoSigSendType";
BA_DEF_DEF_  "GenSigInactiveValue" 0;
BA_DEF_DEF_  "WakeupSignal" "No";
BA_DEF_DEF_  "UsedOnPgmDBC" "Yes";
BA_DEF_DEF_  "GenSigStartValueInteger" 0;
BA_DEF_DEF_  "ContentDependant" "No";
BA_DEF_DEF_  "MetaData" "No";
BA_DEF_DEF_  "GenSigStartValue" 0;
BA_DEF_DEF_  "U_CX727_MY2021_Rx" "No";
BA_DEF_DEF_  "U_P702_MY2021_Rx" "No";
BA_DEF_DEF_  "U_T6_MCA_MY2020_Rx" "No";
BA_DEF_DEF_  "ECGUsedRxSignal" "No";
BA_DEF_DEF_  "U_CD542_MY2021_Rx" "No";
BA_DEF_DEF_  "U_U55X_MY2022_Rx" "No";
BA_DEF_DEF_  "U_CD764_MY2022_Rx" "No";
BA_DEF_DEF_  "U_CDX706_MY2023_Rx" "No";
BA_DEF_DEF_  "U_CX727_MY2021_Tx" "No";
BA_DEF_DEF_  "U_P702_MY2021_Tx" "No";
BA_DEF_DEF_  "U_T6_MCA_MY2020_Tx" "No";
BA_DEF_DEF_  "ECGUsedTxSignal" "No";
BA_DEF_DEF_  "U_CD542_MY2021_Tx" "No";
BA_DEF_DEF_  "U_U55X_MY2022_Tx" "No";
BA_DEF_DEF_  "U_CD764_MY2022_Tx" "No";
BA_DEF_DEF_  "U_CDX706_MY2023_Tx" "No";
BA_DEF_DEF_  "GenMsgILSupport" "Yes";
BA_DEF_DEF_  "DiagResponse" "No";
BA_DEF_DEF_  "DiagRequest" "No";
BA_DEF_DEF_  "TpTxIndex" 0;
BA_DEF_DEF_  "DiagState" "No";
BA_DEF_DEF_  "TpApplType" "";
BA_DEF_DEF_  "NmAsrMessage" "No";
BA_DEF_DEF_  "ProgBWConditional" "NONE";
BA_DEF_DEF_  "SCP_AuthInfoTxLength" 53;
BA_DEF_DEF_  "SCP_FreshnessValueTxLength" 11;
BA_DEF_DEF_  "SCP_FreshnessValueLength" 64;
BA_DEF_DEF_  "OvtpPushApplication" "FALSE";
BA_DEF_DEF_  "GenMsgSendType" "NoMsgSendType";
BA_DEF_DEF_  "GenMsgCycleTime" 0;
BA_DEF_DEF_  "GenMsgDelayTime" 20;
BA_DEF_DEF_  "GenMsgNrOfRepetition" 1;
BA_DEF_DEF_  "GenMsgStartDelayTime" 0;
BA_DEF_DEF_  "EventRateOfChange" 10000;
BA_DEF_DEF_  "FrameGatewayId" 0;
BA_DEF_DEF_  "NetworkInitialization" "Yes";
BA_DEF_DEF_  "FrameGatewayNetwork" "NONE";
BA_DEF_DEF_  "FrameRouting" "";
BA_DEF_DEF_  "GatewayECU" "No";
BA_DEF_DEF_  "PackageID" "08.05.00.00.71.xx.xx.rr.00.00";
BA_DEF_DEF_  "NosPackage" "I3_3";
BA_DEF_DEF_  "NmStationAddress" 0;
BA_DEF_DEF_  "EOL_SB_Flash" "GGDS";
BA_DEF_DEF_  "DiagNode" "GGDS";
BA_DEF_DEF_  "PowerType" "Switched";
BA_DEF_DEF_  "NmAsrNode" "No";
BA_DEF_DEF_  "NmAsrNodeIdentifier" 128;
BA_DEF_DEF_  "NodeStartUpTime" 250;
BA_DEF_DEF_  "NodeWakeUpTime" 100;
BA_DEF_DEF_  "Terminator" "No";
BA_DEF_DEF_  "ILUsed" "Yes";
BA_DEF_DEF_  "OvtpEcuAddress" 0;
BA_DEF_DEF_  "OvtpOperationMode" "SERVER";
BA_DEF_DEF_  "NmMessageCount" 128;
BA_DEF_DEF_  "NmBaseAddress" 1280;
BA_DEF_DEF_  "VersionYear" 2011;
BA_DEF_DEF_  "VersionMonth" 1;
BA_DEF_DEF_  "Manufacturer" "Ford";
BA_DEF_DEF_  "VersionDay" 1;
BA_DEF_DEF_  "DBName" "";
BA_DEF_DEF_  "NmAsrBaseAddress" 1408;
BA_DEF_DEF_  "NmAsrMessageCount" 128;
BA_DEF_DEF_  "NmType" "Ford-OSEK";
BA_DEF_DEF_  "CMDB_Version" "v11.01";
BA_DEF_DEF_  "StarNetworkGwType" "0=NotDefined";
BA_DEF_DEF_  "VersionNumber" 1;
BA_DEF_DEF_  "NetworkSpeed" "500kBits/s";

BA_ "GenMsgSendType" BO_ 932 0;
BA_ "GenMsgCycleTime" BO_ 932 200;
BA_ "GenMsgSendType" BO_ 781 5;
BA_ "GenMsgCycleTime" BO_ 781 100;
BA_ "GenMsgSendType" BO_ 1267 0;
BA_ "GenMsgCycleTime" BO_ 1267 1000;
BA_ "GenMsgSendType" BO_ 1216 5;
BA_ "GenMsgCycleTime" BO_ 1216 1000;
BA_ "GenMsgSendType" BO_ 1217 5;
BA_ "GenMsgCycleTime" BO_ 1217 1000;
BA_ "GenMsgSendType" BO_ 816 5;
BA_ "GenMsgCycleTime" BO_ 816 1000;
BA_ "GenMsgSendType" BO_ 805 0;
BA_ "GenMsgCycleTime" BO_ 805 100;
BA_ "GenMsgSendType" BO_ 646 0;
BA_ "GenMsgCycleTime" BO_ 646 100;
BA_ "GenMsgSendType" BO_ 591 0;
BA_ "GenMsgCycleTime" BO_ 591 1000;
BA_ "GenMsgSendType" BO_ 627 0;
BA_ "GenMsgCycleTime" BO_ 627 100;
BA_ "GenMsgSendType" BO_ 630 0;
BA_ "GenMsgCycleTime" BO_ 630 100;
BA_ "GenMsgSendType" BO_ 599 5;
BA_ "GenMsgCycleTime" BO_ 599 1000;
BA_ "GenMsgSendType" BO_ 1227 0;
BA_ "GenMsgCycleTime" BO_ 1227 1000;
BA_ "GenMsgSendType" BO_ 1222 0;
BA_ "GenMsgCycleTime" BO_ 1222 1000;
BA_ "GenMsgSendType" BO_ 595 5;
BA_ "GenMsgCycleTime" BO_ 595 500;
BA_ "GenMsgSendType" BO_ 612 5;
BA_ "GenMsgCycleTime" BO_ 612 1000;
BA_ "GenMsgSendType" BO_ 1015 5;
BA_ "GenMsgCycleTime" BO_ 1015 1000;
BA_ "GenMsgSendType" BO_ 986 5;
BA_ "GenMsgCycleTime" BO_ 986 1000;
BA_ "GenMsgSendType" BO_ 1176 0;
BA_ "GenMsgCycleTime" BO_ 1176 1000;
BA_ "GenMsgSendType" BO_ 1175 0;
BA_ "GenMsgCycleTime" BO_ 1175 1000;
BA_ "GenMsgSendType" BO_ 1174 0;
BA_ "GenMsgCycleTime" BO_ 1174 1000;
BA_ "GenMsgSendType" BO_ 1173 0;
BA_ "GenMsgCycleTime" BO_ 1173 1000;
BA_ "GenMsgSendType" BO_ 1172 0;
BA_ "GenMsgCycleTime" BO_ 1172 1000;
BA_ "GenMsgSendType" BO_ 1171 0;
BA_ "GenMsgCycleTime" BO_ 1171 1000;
BA_ "GenMsgSendType" BO_ 1170 0;
BA_ "GenMsgCycleTime" BO_ 1170 1000;
BA_ "GenMsgSendType" BO_ 1191 0;
BA_ "GenMsgCycleTime" BO_ 1191 1000;
BA_ "GenMsgSendType" BO_ 1190 0;
BA_ "GenMsgCycleTime" BO_ 1190 1000;
BA_ "GenMsgSendType" BO_ 1188 0;
BA_ "GenMsgCycleTime" BO_ 1188 1000;
BA_ "GenMsgSendType" BO_ 1187 0;
BA_ "GenMsgCycleTime" BO_ 1187 1000;
BA_ "GenMsgSendType" BO_ 1169 0;
BA_ "GenMsgCycleTime" BO_ 1169 1000;
BA_ "GenMsgSendType" BO_ 1192 0;
BA_ "GenMsgCycleTime" BO_ 1192 1000;
BA_ "GenMsgSendType" BO_ 1185 0;
BA_ "GenMsgCycleTime" BO_ 1185 1000;
BA_ "GenMsgSendType" BO_ 1184 0;
BA_ "GenMsgCycleTime" BO_ 1184 1000;
BA_ "GenMsgSendType" BO_ 1183 0;
BA_ "GenMsgCycleTime" BO_ 1183 1000;
BA_ "GenMsgSendType" BO_ 1182 0;
BA_ "GenMsgCycleTime" BO_ 1182 1000;
BA_ "GenMsgSendType" BO_ 1181 0;
BA_ "GenMsgCycleTime" BO_ 1181 1000;
BA_ "GenMsgSendType" BO_ 1180 0;
BA_ "GenMsgCycleTime" BO_ 1180 1000;
BA_ "GenMsgSendType" BO_ 1179 0;
BA_ "GenMsgCycleTime" BO_ 1179 1000;
BA_ "GenMsgSendType" BO_ 1178 0;
BA_ "GenMsgCycleTime" BO_ 1178 1000;
BA_ "GenMsgSendType" BO_ 1177 0;
BA_ "GenMsgCycleTime" BO_ 1177 1000;
BA_ "GenMsgSendType" BO_ 1168 0;
BA_ "GenMsgCycleTime" BO_ 1168 1000;
BA_ "GenMsgSendType" BO_ 1116 5;
BA_ "GenMsgCycleTime" BO_ 1116 1000;
BA_ "GenMsgSendType" BO_ 954 5;
BA_ "GenMsgCycleTime" BO_ 954 1000;
BA_ "GenMsgSendType" BO_ 874 5;
BA_ "GenMsgCycleTime" BO_ 874 1000;
BA_ "GenMsgSendType" BO_ 551 5;
BA_ "GenMsgCycleTime" BO_ 551 1000;
BA_ "GenMsgSendType" BO_ 132 1;
BA_ "GenMsgSendType" BO_ 1123 1;
BA_ "GenMsgSendType" BO_ 1122 1;
BA_ "GenMsgSendType" BO_ 1003 5;
BA_ "GenMsgCycleTime" BO_ 1003 1000;
BA_ "GenMsgSendType" BO_ 580 5;
BA_ "GenMsgCycleTime" BO_ 580 1000;
BA_ "GenMsgSendType" BO_ 994 5;
BA_ "GenMsgCycleTime" BO_ 994 1000;

BA_ "VersionYear" 2021;
BA_ "VersionMonth" 9;
BA_ "VersionDay" 23;
BA_ "CMDB_Version" "FNV2_v21.07";
BA_ "StarNetworkGwType" 10;
BA_ "VersionNumber" 7;
BA_ "BusType" "CAN FD";
BA_ "DBName" "FD1_CAN";
BA_ "NosPackage" BU_ TCM 4;
BA_ "NmStationAddress" BU_ TCM 32;
BA_ "PowerType" BU_ TCM 2;
BA_ "NmAsrNode" BU_ TCM 1;
BA_ "NmAsrNodeIdentifier" BU_ TCM 160;
BA_ "NodeStartUpTime" BU_ TCM 1000;
BA_ "NodeWakeUpTime" BU_ TCM 150;
BA_ "OvtpEcuAddress" BU_ TCM 24;
BA_ "NmStationAddress" BU_ HCM 55;
BA_ "OvtpEcuAddress" BU_ HCM 113;
BA_ "NmStationAddress" BU_ IPMA_ADAS 28;
BA_ "PowerType" BU_ IPMA_ADAS 1;
BA_ "NmAsrNode" BU_ IPMA_ADAS 1;
BA_ "NmAsrNodeIdentifier" BU_ IPMA_ADAS 156;
BA_ "NodeStartUpTime" BU_ IPMA_ADAS 300;
BA_ "OvtpEcuAddress" BU_ IPMA_ADAS 33;
BA_ "NmStationAddress" BU_ PSCM 53;
BA_ "PowerType" BU_ PSCM 1;
BA_ "NmAsrNode" BU_ PSCM 1;
BA_ "NmAsrNodeIdentifier" BU_ PSCM 181;
BA_ "Terminator" BU_ PSCM 1;
BA_ "OvtpEcuAddress" BU_ PSCM 48;
BA_ "NmStationAddress" BU_ ABS_ESC 22;
BA_ "PowerType" BU_ ABS_ESC 2;
BA_ "NmAsrNode" BU_ ABS_ESC 1;
BA_ "NmAsrNodeIdentifier" BU_ ABS_ESC 150;
BA_ "NodeStartUpTime" BU_ ABS_ESC 1000;
BA_ "NodeWakeUpTime" BU_ ABS_ESC 300;
BA_ "OvtpEcuAddress" BU_ ABS_ESC 40;
BA_ "NmStationAddress" BU_ TCCM 33;
BA_ "NmAsrNode" BU_ TCCM 1;
BA_ "NmAsrNodeIdentifier" BU_ TCCM 161;
BA_ "NodeStartUpTime" BU_ TCCM 1000;
BA_ "NodeWakeUpTime" BU_ TCCM 25;
BA_ "OvtpEcuAddress" BU_ TCCM 25;
BA_ "NosPackage" BU_ TCM_DSL 4;
BA_ "NmStationAddress" BU_ TCM_DSL 32;
BA_ "PowerType" BU_ TCM_DSL 1;
BA_ "NmAsrNode" BU_ TCM_DSL 1;
BA_ "NmAsrNodeIdentifier" BU_ TCM_DSL 160;
BA_ "NodeWakeUpTime" BU_ TCM_DSL 250;
BA_ "OvtpEcuAddress" BU_ TCM_DSL 24;
BA_ "NmStationAddress" BU_ PCM_HEV 21;
BA_ "PowerType" BU_ PCM_HEV 1;
BA_ "NmAsrNode" BU_ PCM_HEV 1;
BA_ "NmAsrNodeIdentifier" BU_ PCM_HEV 149;
BA_ "NodeStartUpTime" BU_ PCM_HEV 350;
BA_ "Terminator" BU_ PCM_HEV 1;
BA_ "OvtpEcuAddress" BU_ PCM_HEV 16;
BA_ "NmStationAddress" BU_ PCM 21;
BA_ "PowerType" BU_ PCM 1;
BA_ "NmAsrNode" BU_ PCM 1;
BA_ "NmAsrNodeIdentifier" BU_ PCM 149;
BA_ "NodeStartUpTime" BU_ PCM 350;
BA_ "Terminator" BU_ PCM 1;
BA_ "OvtpEcuAddress" BU_ PCM 16;
BA_ "NmStationAddress" BU_ ECM_HEVDSL 21;
BA_ "PowerType" BU_ ECM_HEVDSL 1;
BA_ "NmAsrNode" BU_ ECM_HEVDSL 1;
BA_ "NmAsrNodeIdentifier" BU_ ECM_HEVDSL 149;
BA_ "Terminator" BU_ ECM_HEVDSL 1;
BA_ "OvtpEcuAddress" BU_ ECM_HEVDSL 16;
BA_ "NmStationAddress" BU_ ECM_HEV 21;
BA_ "PowerType" BU_ ECM_HEV 1;
BA_ "NmAsrNode" BU_ ECM_HEV 1;
BA_ "NmAsrNodeIdentifier" BU_ ECM_HEV 149;
BA_ "NodeStartUpTime" BU_ ECM_HEV 350;
BA_ "Terminator" BU_ ECM_HEV 1;
BA_ "OvtpEcuAddress" BU_ ECM_HEV 16;
BA_ "NmStationAddress" BU_ ECM_Diesel 21;
BA_ "PowerType" BU_ ECM_Diesel 1;
BA_ "NmAsrNode" BU_ ECM_Diesel 1;
BA_ "NmAsrNodeIdentifier" BU_ ECM_Diesel 149;
BA_ "Terminator" BU_ ECM_Diesel 1;
BA_ "OvtpEcuAddress" BU_ ECM_Diesel 16;
BA_ "NmStationAddress" BU_ ECM 21;
BA_ "PowerType" BU_ ECM 1;
BA_ "NmAsrNode" BU_ ECM 1;
BA_ "NmAsrNodeIdentifier" BU_ ECM 149;
BA_ "NodeStartUpTime" BU_ ECM 350;
BA_ "Terminator" BU_ ECM 1;
BA_ "OvtpEcuAddress" BU_ ECM 16;
BA_ "NmStationAddress" BU_ SIMA_DLCS 247;
BA_ "PowerType" BU_ SIMA_DLCS 2;
BA_ "NmAsrNode" BU_ SIMA_DLCS 1;
BA_ "NmAsrNodeIdentifier" BU_ SIMA_DLCS 247;
BA_ "NodeWakeUpTime" BU_ SIMA_DLCS 250;
BA_ "OvtpEcuAddress" BU_ SIMA_DLCS 67;
BA_ "NmStationAddress" BU_ BCMD_IPDB 47;
BA_ "PowerType" BU_ BCMD_IPDB 2;
BA_ "NmAsrNode" BU_ BCMD_IPDB 1;
BA_ "NmAsrNodeIdentifier" BU_ BCMD_IPDB 175;
BA_ "OvtpEcuAddress" BU_ BCMD_IPDB 85;
BA_ "NmStationAddress" BU_ VDM 48;
BA_ "PowerType" BU_ VDM 1;
BA_ "NmAsrNode" BU_ VDM 1;
BA_ "NmAsrNodeIdentifier" BU_ VDM 176;
BA_ "OvtpEcuAddress" BU_ VDM 32;
BA_ "NmStationAddress" BU_ CMR_DSMC 95;
BA_ "PowerType" BU_ CMR_DSMC 2;
BA_ "NmAsrNode" BU_ CMR_DSMC 1;
BA_ "NmAsrNodeIdentifier" BU_ CMR_DSMC 223;
BA_ "OvtpEcuAddress" BU_ CMR_DSMC 187;
BA_ "NmStationAddress" BU_ SOBDMC_HPCM 37;
BA_ "PowerType" BU_ SOBDMC_HPCM 1;
BA_ "NmAsrNode" BU_ SOBDMC_HPCM 1;
BA_ "NmAsrNodeIdentifier" BU_ SOBDMC_HPCM 165;
BA_ "OvtpEcuAddress" BU_ SOBDMC_HPCM 17;
BA_ "NmStationAddress" BU_ CHCM 115;
BA_ "PowerType" BU_ CHCM 1;
BA_ "OvtpEcuAddress" BU_ CHCM 46;
BA_ "GatewayECU" BU_ GWM 1;
BA_ "NosPackage" BU_ GWM 4;
BA_ "NmStationAddress" BU_ GWM 30;
BA_ "PowerType" BU_ GWM 2;
BA_ "NmAsrNode" BU_ GWM 1;
BA_ "NmAsrNodeIdentifier" BU_ GWM 158;
BA_ "NodeStartUpTime" BU_ GWM 100;
BA_ "Terminator" BU_ GWM 1;
BA_ "OvtpEcuAddress" BU_ GWM 216;
BA_ "OvtpOperationMode" BU_ GWM 1;
BA_ "NmStationAddress" BU_ AWD_DLCM 112;
BA_ "PowerType" BU_ AWD_DLCM 1;
BA_ "NmAsrNode" BU_ AWD_DLCM 1;
BA_ "NmAsrNodeIdentifier" BU_ AWD_DLCM 240;
BA_ "NodeStartUpTime" BU_ AWD_DLCM 350;
BA_ "OvtpEcuAddress" BU_ AWD_DLCM 30;
BA_ "NmAsrNode" BU_ GENERIC 1;
BA_ "FrameGatewayId" BO_ 495 495;
BA_ "FrameGatewayNetwork" BO_ 495 "MS1_CAN";
BA_ "FrameRouting" BO_ 495 "MS1_CAN,0x1EF;";
BA_ "VFrameFormat" BO_ 495 14;
BA_ "GenMsgSendType" BO_ 466 0;
BA_ "GenMsgCycleTime" BO_ 466 100;
BA_ "VFrameFormat" BO_ 466 14;
BA_ "GenMsgSendType" BO_ 283 0;
BA_ "GenMsgCycleTime" BO_ 283 200;
BA_ "VFrameFormat" BO_ 283 14;
BA_ "FrameGatewayId" BO_ 932 932;
BA_ "FrameGatewayNetwork" BO_ 932 "HS1_CAN";
BA_ "FrameRouting" BO_ 932 "HS1_CAN,0x3A4;";
BA_ "VFrameFormat" BO_ 932 14;
BA_ "FrameGatewayId" BO_ 781 781;
BA_ "FrameGatewayNetwork" BO_ 781 "MS2_CAN";
BA_ "FrameRouting" BO_ 781 "MS2_CAN,0x30D;";
BA_ "VFrameFormat" BO_ 781 14;
BA_ "GenMsgSendType" BO_ 368 0;
BA_ "GenMsgCycleTime" BO_ 368 20;
BA_ "GenMsgDelayTime" BO_ 368 10;
BA_ "VFrameFormat" BO_ 368 14;
BA_ "FrameGatewayId" BO_ 1267 1267;
BA_ "FrameGatewayNetwork" BO_ 1267 "HS1_CAN";
BA_ "FrameRouting" BO_ 1267 "HS1_CAN,0x4F3;";
BA_ "VFrameFormat" BO_ 1267 14;
BA_ "GenMsgSendType" BO_ 393 5;
BA_ "GenMsgCycleTime" BO_ 393 1000;
BA_ "VFrameFormat" BO_ 393 14;
BA_ "FrameGatewayId" BO_ 1216 1216;
BA_ "FrameGatewayNetwork" BO_ 1216 "MS1_CAN";
BA_ "FrameRouting" BO_ 1216 "MS1_CAN,0x4C0;";
BA_ "VFrameFormat" BO_ 1216 14;
BA_ "FrameGatewayId" BO_ 1217 1217;
BA_ "FrameGatewayNetwork" BO_ 1217 "MS1_CAN";
BA_ "FrameRouting" BO_ 1217 "MS1_CAN,0x4C1;";
BA_ "VFrameFormat" BO_ 1217 14;
BA_ "GenMsgSendType" BO_ 1204 5;
BA_ "GenMsgCycleTime" BO_ 1204 1000;
BA_ "VFrameFormat" BO_ 1204 14;
BA_ "FrameGatewayId" BO_ 816 816;
BA_ "FrameGatewayNetwork" BO_ 816 "HS3_CAN";
BA_ "FrameRouting" BO_ 816 "HS3_CAN,0x330;";
BA_ "VFrameFormat" BO_ 816 14;
BA_ "FrameGatewayId" BO_ 805 805;
BA_ "FrameGatewayNetwork" BO_ 805 "HS3_CAN";
BA_ "FrameRouting" BO_ 805 "HS3_CAN,0x325;";
BA_ "VFrameFormat" BO_ 805 14;
BA_ "FrameGatewayId" BO_ 646 646;
BA_ "FrameGatewayNetwork" BO_ 646 "HS1_CAN";
BA_ "FrameRouting" BO_ 646 "HS1_CAN,0x286;";
BA_ "VFrameFormat" BO_ 646 14;
BA_ "FrameGatewayId" BO_ 591 591;
BA_ "FrameGatewayNetwork" BO_ 591 "HS1_CAN";
BA_ "FrameRouting" BO_ 591 "HS1_CAN,0x24F;";
BA_ "VFrameFormat" BO_ 591 14;
BA_ "FrameGatewayId" BO_ 627 627;
BA_ "FrameGatewayNetwork" BO_ 627 "HS3_CAN";
BA_ "FrameRouting" BO_ 627 "HS3_CAN,0x273;";
BA_ "VFrameFormat" BO_ 627 14;
BA_ "FrameGatewayId" BO_ 630 630;
BA_ "FrameGatewayNetwork" BO_ 630 "HS3_CAN";
BA_ "FrameRouting" BO_ 630 "HS3_CAN,0x276;";
BA_ "VFrameFormat" BO_ 630 14;
BA_ "GenMsgSendType" BO_ 650 5;
BA_ "GenMsgCycleTime" BO_ 650 500;
BA_ "VFrameFormat" BO_ 650 14;
BA_ "GenMsgSendType" BO_ 663 0;
BA_ "GenMsgCycleTime" BO_ 663 1000;
BA_ "VFrameFormat" BO_ 663 14;
BA_ "GenMsgSendType" BO_ 655 0;
BA_ "GenMsgCycleTime" BO_ 655 500;
BA_ "VFrameFormat" BO_ 655 14;
BA_ "FrameGatewayId" BO_ 599 599;
BA_ "FrameGatewayNetwork" BO_ 599 "HS1_CAN";
BA_ "FrameRouting" BO_ 599 "HS1_CAN,0x257;";
BA_ "VFrameFormat" BO_ 599 14;
BA_ "FrameGatewayId" BO_ 1227 1227;
BA_ "FrameGatewayNetwork" BO_ 1227 "HS1_CAN";
BA_ "FrameRouting" BO_ 1227 "HS1_CAN,0x4CB;";
BA_ "VFrameFormat" BO_ 1227 14;
BA_ "FrameGatewayId" BO_ 1222 1222;
BA_ "FrameGatewayNetwork" BO_ 1222 "HS1_CAN";
BA_ "FrameRouting" BO_ 1222 "HS1_CAN,0x4C6;";
BA_ "VFrameFormat" BO_ 1222 14;
BA_ "FrameGatewayId" BO_ 595 595;
BA_ "FrameGatewayNetwork" BO_ 595 "HS3_CAN";
BA_ "FrameRouting" BO_ 595 "HS3_CAN,0x253;";
BA_ "VFrameFormat" BO_ 595 14;
BA_ "GenMsgSendType" BO_ 596 5;
BA_ "GenMsgCycleTime" BO_ 596 500;
BA_ "VFrameFormat" BO_ 596 14;
BA_ "FrameGatewayId" BO_ 612 612;
BA_ "FrameGatewayNetwork" BO_ 612 "MS1_CAN";
BA_ "FrameRouting" BO_ 612 "MS1_CAN,0x264;";
BA_ "VFrameFormat" BO_ 612 14;
BA_ "FrameGatewayId" BO_ 1015 1015;
BA_ "FrameGatewayNetwork" BO_ 1015 "MS1_CAN";
BA_ "FrameRouting" BO_ 1015 "MS1_CAN,0x3F7;";
BA_ "VFrameFormat" BO_ 1015 14;
BA_ "TpTxIndex" BO_ 2611034328 463550680;
BA_ "GenMsgSendType" BO_ 2611034328 1;
BA_ "GenMsgDelayTime" BO_ 2611034328 0;
BA_ "TpTxIndex" BO_ 2611035352 463551704;
BA_ "GenMsgSendType" BO_ 2611035352 1;
BA_ "GenMsgDelayTime" BO_ 2611035352 0;
BA_ "TpTxIndex" BO_ 2611175502 463550680;
BA_ "GenMsgSendType" BO_ 2611175502 1;
BA_ "GenMsgDelayTime" BO_ 2611175502 0;
BA_ "TpTxIndex" BO_ 2611175503 463551704;
BA_ "GenMsgSendType" BO_ 2611175503 1;
BA_ "GenMsgDelayTime" BO_ 2611175503 0;
BA_ "TpTxIndex" BO_ 2612224078 464599256;
BA_ "OvtpPushApplication" BO_ 2612224078 1;
BA_ "GenMsgSendType" BO_ 2612224078 1;
BA_ "GenMsgDelayTime" BO_ 2612224078 0;
BA_ "TpTxIndex" BO_ 2612224079 464600280;
BA_ "OvtpPushApplication" BO_ 2612224079 1;
BA_ "GenMsgSendType" BO_ 2612224079 1;
BA_ "GenMsgDelayTime" BO_ 2612224079 0;
BA_ "TpTxIndex" BO_ 2612082904 464599256;
BA_ "OvtpPushApplication" BO_ 2612082904 1;
BA_ "GenMsgSendType" BO_ 2612082904 1;
BA_ "GenMsgDelayTime" BO_ 2612082904 0;
BA_ "TpTxIndex" BO_ 2612083928 464600280;
BA_ "OvtpPushApplication" BO_ 2612083928 1;
BA_ "GenMsgSendType" BO_ 2612083928 1;
BA_ "GenMsgDelayTime" BO_ 2612083928 0;
BA_ "TpTxIndex" BO_ 2610126926 462502104;
BA_ "GenMsgSendType" BO_ 2610126926 1;
BA_ "GenMsgDelayTime" BO_ 2610126926 0;
BA_ "TpTxIndex" BO_ 2610126927 462503128;
BA_ "GenMsgSendType" BO_ 2610126927 1;
BA_ "GenMsgDelayTime" BO_ 2610126927 0;
BA_ "TpTxIndex" BO_ 2609985752 462502104;
BA_ "GenMsgSendType" BO_ 2609985752 1;
BA_ "GenMsgDelayTime" BO_ 2609985752 0;
BA_ "TpTxIndex" BO_ 2609986776 462503128;
BA_ "GenMsgSendType" BO_ 2609986776 1;
BA_ "GenMsgDelayTime" BO_ 2609986776 0;
BA_ "FrameGatewayId" BO_ 986 986;
BA_ "FrameGatewayNetwork" BO_ 986 "HS3_CAN";
BA_ "FrameRouting" BO_ 986 "HS3_CAN,0x3DA;";
BA_ "VFrameFormat" BO_ 986 14;
BA_ "GenMsgSendType" BO_ 571 0;
BA_ "GenMsgCycleTime" BO_ 571 150;
BA_ "VFrameFormat" BO_ 571 14;
BA_ "TpTxIndex" BO_ 2612224024 464543960;
BA_ "OvtpPushApplication" BO_ 2612224024 1;
BA_ "GenMsgSendType" BO_ 2612224024 1;
BA_ "GenMsgDelayTime" BO_ 2612224024 0;
BA_ "TpTxIndex" BO_ 2612027608 464543960;
BA_ "OvtpPushApplication" BO_ 2612027608 1;
BA_ "GenMsgSendType" BO_ 2612027608 1;
BA_ "GenMsgDelayTime" BO_ 2612027608 0;
BA_ "TpTxIndex" BO_ 2610126872 462446808;
BA_ "GenMsgSendType" BO_ 2610126872 1;
BA_ "GenMsgDelayTime" BO_ 2610126872 0;
BA_ "TpTxIndex" BO_ 2609930456 462446808;
BA_ "GenMsgSendType" BO_ 2609930456 1;
BA_ "GenMsgDelayTime" BO_ 2609930456 0;
BA_ "TpTxIndex" BO_ 2610979032 463495384;
BA_ "GenMsgSendType" BO_ 2610979032 1;
BA_ "GenMsgDelayTime" BO_ 2610979032 0;
BA_ "TpTxIndex" BO_ 2611175448 463495384;
BA_ "GenMsgSendType" BO_ 2611175448 1;
BA_ "GenMsgDelayTime" BO_ 2611175448 0;
BA_ "GenMsgSendType" BO_ 537 0;
BA_ "GenMsgCycleTime" BO_ 537 50;
BA_ "VFrameFormat" BO_ 537 14;
BA_ "FrameGatewayId" BO_ 1176 1176;
BA_ "FrameGatewayNetwork" BO_ 1176 "HS1_CAN";
BA_ "FrameRouting" BO_ 1176 "HS1_CAN,0x498;";
BA_ "VFrameFormat" BO_ 1176 14;
BA_ "FrameGatewayId" BO_ 1175 1175;
BA_ "FrameGatewayNetwork" BO_ 1175 "HS1_CAN";
BA_ "FrameRouting" BO_ 1175 "HS1_CAN,0x497;";
BA_ "VFrameFormat" BO_ 1175 14;
BA_ "FrameGatewayId" BO_ 1174 1174;
BA_ "FrameGatewayNetwork" BO_ 1174 "HS1_CAN";
BA_ "FrameRouting" BO_ 1174 "HS1_CAN,0x496;";
BA_ "VFrameFormat" BO_ 1174 14;
BA_ "FrameGatewayId" BO_ 1173 1173;
BA_ "FrameGatewayNetwork" BO_ 1173 "HS1_CAN";
BA_ "FrameRouting" BO_ 1173 "HS1_CAN,0x495;";
BA_ "VFrameFormat" BO_ 1173 14;
BA_ "FrameGatewayId" BO_ 1172 1172;
BA_ "FrameGatewayNetwork" BO_ 1172 "HS1_CAN";
BA_ "FrameRouting" BO_ 1172 "HS1_CAN,0x494;";
BA_ "VFrameFormat" BO_ 1172 14;
BA_ "FrameGatewayId" BO_ 1171 1171;
BA_ "FrameGatewayNetwork" BO_ 1171 "HS1_CAN";
BA_ "FrameRouting" BO_ 1171 "HS1_CAN,0x493;";
BA_ "VFrameFormat" BO_ 1171 14;
BA_ "GenMsgILSupport" BO_ 1822 0;
BA_ "DiagResponse" BO_ 1822 1;
BA_ "GenMsgSendType" BO_ 1822 1;
BA_ "GenMsgDelayTime" BO_ 1822 0;
BA_ "NetworkInitialization" BO_ 1822 0;
BA_ "VFrameFormat" BO_ 1822 14;
BA_ "GenMsgILSupport" BO_ 1438 0;
BA_ "NmAsrMessage" BO_ 1438 1;
BA_ "GenMsgSendType" BO_ 1438 0;
BA_ "GenMsgCycleTime" BO_ 1438 1000;
BA_ "NetworkInitialization" BO_ 1438 0;
BA_ "VFrameFormat" BO_ 1438 14;
BA_ "FrameGatewayId" BO_ 1170 1170;
BA_ "FrameGatewayNetwork" BO_ 1170 "HS1_CAN";
BA_ "FrameRouting" BO_ 1170 "HS1_CAN,0x492;";
BA_ "VFrameFormat" BO_ 1170 14;
BA_ "FrameGatewayId" BO_ 1191 1191;
BA_ "FrameGatewayNetwork" BO_ 1191 "HS1_CAN";
BA_ "FrameRouting" BO_ 1191 "HS1_CAN,0x4A7;";
BA_ "VFrameFormat" BO_ 1191 14;
BA_ "FrameGatewayId" BO_ 1190 1189;
BA_ "FrameGatewayNetwork" BO_ 1190 "HS1_CAN";
BA_ "FrameRouting" BO_ 1190 "HS1_CAN,0x4A5;";
BA_ "VFrameFormat" BO_ 1190 14;
BA_ "FrameGatewayId" BO_ 1188 1188;
BA_ "FrameGatewayNetwork" BO_ 1188 "HS1_CAN";
BA_ "FrameRouting" BO_ 1188 "HS1_CAN,0x4A4;";
BA_ "VFrameFormat" BO_ 1188 14;
BA_ "FrameGatewayId" BO_ 1187 1187;
BA_ "FrameGatewayNetwork" BO_ 1187 "HS1_CAN";
BA_ "FrameRouting" BO_ 1187 "HS1_CAN,0x4A3;";
BA_ "VFrameFormat" BO_ 1187 14;
BA_ "FrameGatewayId" BO_ 1169 1169;
BA_ "FrameGatewayNetwork" BO_ 1169 "HS1_CAN";
BA_ "FrameRouting" BO_ 1169 "HS1_CAN,0x491;";
BA_ "VFrameFormat" BO_ 1169 14;
BA_ "FrameGatewayId" BO_ 1192 1186;
BA_ "FrameGatewayNetwork" BO_ 1192 "HS1_CAN";
BA_ "FrameRouting" BO_ 1192 "HS1_CAN,0x4A2;";
BA_ "VFrameFormat" BO_ 1192 14;
BA_ "FrameGatewayId" BO_ 1185 1185;
BA_ "FrameGatewayNetwork" BO_ 1185 "HS1_CAN";
BA_ "FrameRouting" BO_ 1185 "HS1_CAN,0x4A1;";
BA_ "VFrameFormat" BO_ 1185 14;
BA_ "FrameGatewayId" BO_ 1184 1184;
BA_ "FrameGatewayNetwork" BO_ 1184 "HS1_CAN";
BA_ "FrameRouting" BO_ 1184 "HS1_CAN,0x4A0;";
BA_ "VFrameFormat" BO_ 1184 14;
BA_ "FrameGatewayId" BO_ 1183 1183;
BA_ "FrameGatewayNetwork" BO_ 1183 "HS1_CAN";
BA_ "FrameRouting" BO_ 1183 "HS1_CAN,0x49F;";
BA_ "VFrameFormat" BO_ 1183 14;
BA_ "FrameGatewayId" BO_ 1182 1182;
BA_ "FrameGatewayNetwork" BO_ 1182 "HS1_CAN";
BA_ "FrameRouting" BO_ 1182 "HS1_CAN,0x49E;";
BA_ "VFrameFormat" BO_ 1182 14;
BA_ "FrameGatewayId" BO_ 1181 1181;
BA_ "FrameGatewayNetwork" BO_ 1181 "HS1_CAN";
BA_ "FrameRouting" BO_ 1181 "HS1_CAN,0x49D;";
BA_ "VFrameFormat" BO_ 1181 14;
BA_ "FrameGatewayId" BO_ 1180 1180;
BA_ "FrameGatewayNetwork" BO_ 1180 "HS1_CAN";
BA_ "FrameRouting" BO_ 1180 "HS1_CAN,0x49C;";
BA_ "VFrameFormat" BO_ 1180 14;
BA_ "FrameGatewayId" BO_ 1179 1179;
BA_ "FrameGatewayNetwork" BO_ 1179 "HS1_CAN";
BA_ "FrameRouting" BO_ 1179 "HS1_CAN,0x49B;";
BA_ "VFrameFormat" BO_ 1179 14;
BA_ "FrameGatewayId" BO_ 1178 1178;
BA_ "FrameGatewayNetwork" BO_ 1178 "HS1_CAN";
BA_ "FrameRouting" BO_ 1178 "HS1_CAN,0x49A;";
BA_ "VFrameFormat" BO_ 1178 14;
BA_ "FrameGatewayId" BO_ 1177 1177;
BA_ "FrameGatewayNetwork" BO_ 1177 "HS1_CAN";
BA_ "FrameRouting" BO_ 1177 "HS1_CAN,0x499;";
BA_ "VFrameFormat" BO_ 1177 14;
BA_ "FrameGatewayId" BO_ 1168 1168;
BA_ "FrameGatewayNetwork" BO_ 1168 "HS1_CAN";
BA_ "FrameRouting" BO_ 1168 "HS1_CAN,0x490;";
BA_ "VFrameFormat" BO_ 1168 14;
BA_ "GenMsgSendType" BO_ 1245 5;
BA_ "GenMsgCycleTime" BO_ 1245 1000;
BA_ "VFrameFormat" BO_ 1245 14;
BA_ "GenMsgSendType" BO_ 1242 5;
BA_ "GenMsgCycleTime" BO_ 1242 1000;
BA_ "VFrameFormat" BO_ 1242 14;
BA_ "FrameGatewayId" BO_ 1116 1116;
BA_ "FrameGatewayNetwork" BO_ 1116 "HS3_CAN";
BA_ "FrameRouting" BO_ 1116 "HS3_CAN,0x45C;";
BA_ "VFrameFormat" BO_ 1116 14;
BA_ "GenMsgILSupport" BO_ 1844 0;
BA_ "DiagRequest" BO_ 1844 1;
BA_ "GenMsgSendType" BO_ 1844 1;
BA_ "GenMsgDelayTime" BO_ 1844 0;
BA_ "NetworkInitialization" BO_ 1844 0;
BA_ "VFrameFormat" BO_ 1844 14;
BA_ "FrameGatewayId" BO_ 954 954;
BA_ "FrameGatewayNetwork" BO_ 954 "HS1_CAN";
BA_ "FrameRouting" BO_ 954 "HS1_CAN,0x3BA;";
BA_ "VFrameFormat" BO_ 954 14;
BA_ "GenMsgILSupport" BO_ 1852 0;
BA_ "DiagResponse" BO_ 1852 1;
BA_ "GenMsgSendType" BO_ 1852 1;
BA_ "GenMsgDelayTime" BO_ 1852 0;
BA_ "NetworkInitialization" BO_ 1852 0;
BA_ "VFrameFormat" BO_ 1852 14;
BA_ "GenMsgSendType" BO_ 989 5;
BA_ "GenMsgCycleTime" BO_ 989 1000;
BA_ "VFrameFormat" BO_ 989 14;
BA_ "FrameGatewayId" BO_ 874 874;
BA_ "FrameGatewayNetwork" BO_ 874 "HS1_CAN";
BA_ "FrameRouting" BO_ 874 "HS1_CAN,0x36A;";
BA_ "VFrameFormat" BO_ 874 14;
BA_ "FrameGatewayId" BO_ 551 551;
BA_ "FrameGatewayNetwork" BO_ 551 "HS3_CAN";
BA_ "FrameRouting" BO_ 551 "HS3_CAN,0x227;";
BA_ "VFrameFormat" BO_ 551 14;
BA_ "FrameGatewayId" BO_ 132 132;
BA_ "FrameGatewayNetwork" BO_ 132 "HS1_CAN";
BA_ "FrameRouting" BO_ 132 "HS1_CAN,0x84;";
BA_ "VFrameFormat" BO_ 132 14;
BA_ "GenMsgSendType" BO_ 1006 5;
BA_ "GenMsgCycleTime" BO_ 1006 1000;
BA_ "FrameRouting" BO_ 1006 "FD1_CAN,0x3EE;HS2_CAN,0x3EE";
BA_ "VFrameFormat" BO_ 1006 14;
BA_ "FrameGatewayId" BO_ 1123 1123;
BA_ "FrameGatewayNetwork" BO_ 1123 "HS3_CAN";
BA_ "FrameRouting" BO_ 1123 "HS3_CAN,0x463;";
BA_ "VFrameFormat" BO_ 1123 14;
BA_ "FrameGatewayId" BO_ 1122 1122;
BA_ "FrameGatewayNetwork" BO_ 1122 "HS3_CAN";
BA_ "FrameRouting" BO_ 1122 "HS3_CAN,0x462;";
BA_ "VFrameFormat" BO_ 1122 14;
BA_ "FrameGatewayId" BO_ 1003 1003;
BA_ "FrameGatewayNetwork" BO_ 1003 "HS1_CAN";
BA_ "FrameRouting" BO_ 1003 "HS1_CAN,0x3EB;";
BA_ "VFrameFormat" BO_ 1003 14;
BA_ "FrameGatewayId" BO_ 580 580;
BA_ "FrameGatewayNetwork" BO_ 580 "HS1_CAN";
BA_ "FrameRouting" BO_ 580 "HS1_CAN,0x244;";
BA_ "VFrameFormat" BO_ 580 14;
BA_ "FrameGatewayId" BO_ 994 994;
BA_ "FrameGatewayNetwork" BO_ 994 "HS3_CAN";
BA_ "FrameRouting" BO_ 994 "HS3_CAN,0x3E2;";
BA_ "VFrameFormat" BO_ 994 14;
BA_ "ContentDependant" SG_ 932 CanMsg3A4_No_Crc 1;
BA_ "MetaData" SG_ 932 CanMsg3A4_No_Crc 1;
BA_ "ContentDependant" SG_ 932 CanMsg3A4_No_Cnt 1;
BA_ "MetaData" SG_ 932 CanMsg3A4_No_Cnt 1;
BA_ "ContentDependant" SG_ 368 PrplBrkTqCtl_No_Cs 1;
BA_ "MetaData" SG_ 368 PrplBrkTqCtl_No_Cs 1;
BA_ "ContentDependant" SG_ 368 PrplBrkTqCtl_No_Cnt 1;
BA_ "MetaData" SG_ 368 PrplBrkTqCtl_No_Cnt 1;
BA_ "GenSigStartValue" SG_ 368 PrplWhlTot_Tq_RqFilt 65534;
BA_ "GenSigStartValue" SG_ 1267 BattTracLearn_R_Est 1048574;
BA_ "GenSigStartValue" SG_ 1267 BattTracLearnRC_C_Est 1048574;
BA_ "GenSigStartValue" SG_ 1267 BattTracLearnRC_R_Est 1048574;
BA_ "GenSigSendType" SG_ 393 Afl6TrnstnRight_An_Rq 3;
BA_ "U_CDX706_MY2023_Tx" SG_ 393 Afl6TrnstnRight_An_Rq 1;
BA_ "GenSigSendType" SG_ 393 Afl6TrnstnLeft_An_Rq 3;
BA_ "U_CDX706_MY2023_Tx" SG_ 393 Afl6TrnstnLeft_An_Rq 1;
BA_ "GenSigSendType" SG_ 393 Afl6RightLghtRigh_An_Rq 3;
BA_ "GenSigStartValue" SG_ 393 Afl6RightLghtRigh_An_Rq 256;
BA_ "U_CDX706_MY2023_Tx" SG_ 393 Afl6RightLghtRigh_An_Rq 1;
BA_ "GenSigSendType" SG_ 393 Afl6RightLghtLeft_An_Rq 3;
BA_ "GenSigStartValue" SG_ 393 Afl6RightLghtLeft_An_Rq 256;
BA_ "U_CDX706_MY2023_Tx" SG_ 393 Afl6RightLghtLeft_An_Rq 1;
BA_ "GenSigSendType" SG_ 393 Afl6Ramping_T_Rq 3;
BA_ "U_CDX706_MY2023_Tx" SG_ 393 Afl6Ramping_T_Rq 1;
BA_ "GenSigSendType" SG_ 393 Afl6LeftLghtRight_An_Rq 3;
BA_ "GenSigStartValue" SG_ 393 Afl6LeftLghtRight_An_Rq 256;
BA_ "U_CDX706_MY2023_Tx" SG_ 393 Afl6LeftLghtRight_An_Rq 1;
BA_ "GenSigSendType" SG_ 393 Afl6LeftLghtLeft_An_Rq 3;
BA_ "GenSigStartValue" SG_ 393 Afl6LeftLghtLeft_An_Rq 256;
BA_ "U_CDX706_MY2023_Tx" SG_ 393 Afl6LeftLghtLeft_An_Rq 1;
BA_ "GenSigSendType" SG_ 393 Afl6BrdrTop_An_Rq 3;
BA_ "GenSigStartValue" SG_ 393 Afl6BrdrTop_An_Rq 50;
BA_ "U_CDX706_MY2023_Tx" SG_ 393 Afl6BrdrTop_An_Rq 1;
BA_ "GenSigSendType" SG_ 393 Afl6BrdrBottom_An_Rq 3;
BA_ "GenSigStartValue" SG_ 393 Afl6BrdrBottom_An_Rq 50;
BA_ "U_CDX706_MY2023_Tx" SG_ 393 Afl6BrdrBottom_An_Rq 1;
BA_ "GenSigSendType" SG_ 393 Afl5TrnstnRight_An_Rq 3;
BA_ "U_CDX706_MY2023_Tx" SG_ 393 Afl5TrnstnRight_An_Rq 1;
BA_ "GenSigSendType" SG_ 393 Afl5TrnstnLeft_An_Rq 3;
BA_ "U_CDX706_MY2023_Tx" SG_ 393 Afl5TrnstnLeft_An_Rq 1;
BA_ "GenSigSendType" SG_ 393 Afl5RightLghtRigh_An_Rq 3;
BA_ "GenSigStartValue" SG_ 393 Afl5RightLghtRigh_An_Rq 256;
BA_ "U_CDX706_MY2023_Tx" SG_ 393 Afl5RightLghtRigh_An_Rq 1;
BA_ "GenSigSendType" SG_ 393 Afl5RightLghtLeft_An_Rq 3;
BA_ "GenSigStartValue" SG_ 393 Afl5RightLghtLeft_An_Rq 256;
BA_ "U_CDX706_MY2023_Tx" SG_ 393 Afl5RightLghtLeft_An_Rq 1;
BA_ "GenSigSendType" SG_ 393 Afl5Ramping_T_Rq 3;
BA_ "U_CDX706_MY2023_Tx" SG_ 393 Afl5Ramping_T_Rq 1;
BA_ "GenSigSendType" SG_ 393 Afl5LeftLghtRight_An_Rq 3;
BA_ "GenSigStartValue" SG_ 393 Afl5LeftLghtRight_An_Rq 256;
BA_ "U_CDX706_MY2023_Tx" SG_ 393 Afl5LeftLghtRight_An_Rq 1;
BA_ "GenSigSendType" SG_ 393 Afl5LeftLghtLeft_An_Rq 3;
BA_ "GenSigStartValue" SG_ 393 Afl5LeftLghtLeft_An_Rq 256;
BA_ "U_CDX706_MY2023_Tx" SG_ 393 Afl5LeftLghtLeft_An_Rq 1;
BA_ "GenSigSendType" SG_ 393 Afl5BrdrTop_An_Rq 3;
BA_ "GenSigStartValue" SG_ 393 Afl5BrdrTop_An_Rq 50;
BA_ "U_CDX706_MY2023_Tx" SG_ 393 Afl5BrdrTop_An_Rq 1;
BA_ "GenSigSendType" SG_ 393 Afl5BrdrBottom_An_Rq 3;
BA_ "GenSigStartValue" SG_ 393 Afl5BrdrBottom_An_Rq 50;
BA_ "U_CDX706_MY2023_Tx" SG_ 393 Afl5BrdrBottom_An_Rq 1;
BA_ "GenSigSendType" SG_ 393 Afl4TrnstnRight_An_Rq 3;
BA_ "U_CDX706_MY2023_Tx" SG_ 393 Afl4TrnstnRight_An_Rq 1;
BA_ "GenSigSendType" SG_ 393 Afl4TrnstnLeft_An_Rq 3;
BA_ "U_CDX706_MY2023_Tx" SG_ 393 Afl4TrnstnLeft_An_Rq 1;
BA_ "GenSigSendType" SG_ 393 Afl4RightLghtRigh_An_Rq 3;
BA_ "GenSigStartValue" SG_ 393 Afl4RightLghtRigh_An_Rq 256;
BA_ "U_CDX706_MY2023_Tx" SG_ 393 Afl4RightLghtRigh_An_Rq 1;
BA_ "GenSigSendType" SG_ 393 Afl4RightLghtLeft_An_Rq 3;
BA_ "GenSigStartValue" SG_ 393 Afl4RightLghtLeft_An_Rq 256;
BA_ "U_CDX706_MY2023_Tx" SG_ 393 Afl4RightLghtLeft_An_Rq 1;
BA_ "GenSigSendType" SG_ 393 Afl4Ramping_T_Rq 3;
BA_ "U_CDX706_MY2023_Tx" SG_ 393 Afl4Ramping_T_Rq 1;
BA_ "GenSigSendType" SG_ 393 Afl4LeftLghtRight_An_Rq 3;
BA_ "GenSigStartValue" SG_ 393 Afl4LeftLghtRight_An_Rq 256;
BA_ "U_CDX706_MY2023_Tx" SG_ 393 Afl4LeftLghtRight_An_Rq 1;
BA_ "GenSigSendType" SG_ 393 Afl4LeftLghtLeft_An_Rq 3;
BA_ "GenSigStartValue" SG_ 393 Afl4LeftLghtLeft_An_Rq 256;
BA_ "U_CDX706_MY2023_Tx" SG_ 393 Afl4LeftLghtLeft_An_Rq 1;
BA_ "GenSigSendType" SG_ 393 Afl4BrdrTop_An_Rq 3;
BA_ "GenSigStartValue" SG_ 393 Afl4BrdrTop_An_Rq 50;
BA_ "U_CDX706_MY2023_Tx" SG_ 393 Afl4BrdrTop_An_Rq 1;
BA_ "GenSigSendType" SG_ 393 Afl4BrdrBottom_An_Rq 3;
BA_ "GenSigStartValue" SG_ 393 Afl4BrdrBottom_An_Rq 50;
BA_ "U_CDX706_MY2023_Tx" SG_ 393 Afl4BrdrBottom_An_Rq 1;
BA_ "GenSigSendType" SG_ 393 Afl3TrnstnRight_An_Rq 3;
BA_ "U_CDX706_MY2023_Tx" SG_ 393 Afl3TrnstnRight_An_Rq 1;
BA_ "GenSigSendType" SG_ 393 Afl3TrnstnLeft_An_Rq 3;
BA_ "U_CDX706_MY2023_Tx" SG_ 393 Afl3TrnstnLeft_An_Rq 1;
BA_ "GenSigSendType" SG_ 393 Afl3RightLghtRigh_An_Rq 3;
BA_ "GenSigStartValue" SG_ 393 Afl3RightLghtRigh_An_Rq 256;
BA_ "U_CDX706_MY2023_Tx" SG_ 393 Afl3RightLghtRigh_An_Rq 1;
BA_ "GenSigSendType" SG_ 393 Afl3RightLghtLeft_An_Rq 3;
BA_ "GenSigStartValue" SG_ 393 Afl3RightLghtLeft_An_Rq 256;
BA_ "U_CDX706_MY2023_Tx" SG_ 393 Afl3RightLghtLeft_An_Rq 1;
BA_ "GenSigSendType" SG_ 393 Afl3Ramping_T_Rq 3;
BA_ "U_CDX706_MY2023_Tx" SG_ 393 Afl3Ramping_T_Rq 1;
BA_ "GenSigSendType" SG_ 393 Afl3LeftLghtRight_An_Rq 3;
BA_ "GenSigStartValue" SG_ 393 Afl3LeftLghtRight_An_Rq 256;
BA_ "U_CDX706_MY2023_Tx" SG_ 393 Afl3LeftLghtRight_An_Rq 1;
BA_ "GenSigSendType" SG_ 393 Afl3BrdrTop_An_Rq 3;
BA_ "GenSigStartValue" SG_ 393 Afl3BrdrTop_An_Rq 50;
BA_ "U_CDX706_MY2023_Tx" SG_ 393 Afl3BrdrTop_An_Rq 1;
BA_ "GenSigSendType" SG_ 393 Afl3BrdrBottom_An_Rq 3;
BA_ "GenSigStartValue" SG_ 393 Afl3BrdrBottom_An_Rq 50;
BA_ "U_CDX706_MY2023_Tx" SG_ 393 Afl3BrdrBottom_An_Rq 1;
BA_ "GenSigSendType" SG_ 393 Afl2BrdrBottom_An_Rq 3;
BA_ "GenSigStartValue" SG_ 393 Afl2BrdrBottom_An_Rq 50;
BA_ "U_CDX706_MY2023_Tx" SG_ 393 Afl2BrdrBottom_An_Rq 1;
BA_ "GenSigSendType" SG_ 393 Afl1BrdrBottom_An_Rq 3;
BA_ "GenSigStartValue" SG_ 393 Afl1BrdrBottom_An_Rq 50;
BA_ "U_CDX706_MY2023_Tx" SG_ 393 Afl1BrdrBottom_An_Rq 1;
BA_ "GenSigSendType" SG_ 393 Afl2BrdrTop_An_Rq 3;
BA_ "GenSigStartValue" SG_ 393 Afl2BrdrTop_An_Rq 50;
BA_ "U_CDX706_MY2023_Tx" SG_ 393 Afl2BrdrTop_An_Rq 1;
BA_ "GenSigSendType" SG_ 393 Afl1BrdrTop_An_Rq 3;
BA_ "GenSigStartValue" SG_ 393 Afl1BrdrTop_An_Rq 50;
BA_ "U_CDX706_MY2023_Tx" SG_ 393 Afl1BrdrTop_An_Rq 1;
BA_ "GenSigSendType" SG_ 393 Afl2TrnstnRight_An_Rq 3;
BA_ "U_CDX706_MY2023_Tx" SG_ 393 Afl2TrnstnRight_An_Rq 1;
BA_ "GenSigSendType" SG_ 393 Afl1TrnstnRight_An_Rq 3;
BA_ "U_CDX706_MY2023_Tx" SG_ 393 Afl1TrnstnRight_An_Rq 1;
BA_ "GenSigSendType" SG_ 393 Afl2RightLghtRigh_An_Rq 3;
BA_ "GenSigStartValue" SG_ 393 Afl2RightLghtRigh_An_Rq 256;
BA_ "U_CDX706_MY2023_Tx" SG_ 393 Afl2RightLghtRigh_An_Rq 1;
BA_ "GenSigSendType" SG_ 393 Afl1RightLghtRigh_An_Rq 3;
BA_ "GenSigStartValue" SG_ 393 Afl1RightLghtRigh_An_Rq 256;
BA_ "U_CDX706_MY2023_Tx" SG_ 393 Afl1RightLghtRigh_An_Rq 1;
BA_ "GenSigSendType" SG_ 393 Afl2LeftLghtRight_An_Rq 3;
BA_ "GenSigStartValue" SG_ 393 Afl2LeftLghtRight_An_Rq 256;
BA_ "U_CDX706_MY2023_Tx" SG_ 393 Afl2LeftLghtRight_An_Rq 1;
BA_ "GenSigSendType" SG_ 393 Afl1LeftLghtRight_An_Rq 3;
BA_ "GenSigStartValue" SG_ 393 Afl1LeftLghtRight_An_Rq 256;
BA_ "U_CDX706_MY2023_Tx" SG_ 393 Afl1LeftLghtRight_An_Rq 1;
BA_ "GenSigSendType" SG_ 393 Afl2TrnstnLeft_An_Rq 3;
BA_ "U_CDX706_MY2023_Tx" SG_ 393 Afl2TrnstnLeft_An_Rq 1;
BA_ "GenSigSendType" SG_ 393 Afl1TrnstnLeft_An_Rq 3;
BA_ "U_CDX706_MY2023_Tx" SG_ 393 Afl1TrnstnLeft_An_Rq 1;
BA_ "GenSigSendType" SG_ 393 Afl2RightLghtLeft_An_Rq 3;
BA_ "GenSigStartValue" SG_ 393 Afl2RightLghtLeft_An_Rq 256;
BA_ "U_CDX706_MY2023_Tx" SG_ 393 Afl2RightLghtLeft_An_Rq 1;
BA_ "GenSigSendType" SG_ 393 Afl1RightLghtLeft_An_Rq 3;
BA_ "GenSigStartValue" SG_ 393 Afl1RightLghtLeft_An_Rq 256;
BA_ "U_CDX706_MY2023_Tx" SG_ 393 Afl1RightLghtLeft_An_Rq 1;
BA_ "GenSigSendType" SG_ 393 Afl3LeftLghtLeft_An_Rq 3;
BA_ "GenSigStartValue" SG_ 393 Afl3LeftLghtLeft_An_Rq 256;
BA_ "U_CDX706_MY2023_Tx" SG_ 393 Afl3LeftLghtLeft_An_Rq 1;
BA_ "GenSigSendType" SG_ 393 Afl2LeftLghtLeft_An_Rq 3;
BA_ "GenSigStartValue" SG_ 393 Afl2LeftLghtLeft_An_Rq 256;
BA_ "U_CDX706_MY2023_Tx" SG_ 393 Afl2LeftLghtLeft_An_Rq 1;
BA_ "GenSigSendType" SG_ 393 Afl1LeftLghtLeft_An_Rq 3;
BA_ "GenSigStartValue" SG_ 393 Afl1LeftLghtLeft_An_Rq 256;
BA_ "U_CDX706_MY2023_Tx" SG_ 393 Afl1LeftLghtLeft_An_Rq 1;
BA_ "GenSigSendType" SG_ 393 Afl2Ramping_T_Rq 3;
BA_ "U_CDX706_MY2023_Tx" SG_ 393 Afl2Ramping_T_Rq 1;
BA_ "GenSigSendType" SG_ 393 Afl1Ramping_T_Rq 3;
BA_ "U_CDX706_MY2023_Tx" SG_ 393 Afl1Ramping_T_Rq 1;
BA_ "GenSigSendType" SG_ 393 Afl6Mde_D_Rq 3;
BA_ "U_CDX706_MY2023_Tx" SG_ 393 Afl6Mde_D_Rq 1;
BA_ "GenSigSendType" SG_ 393 Afl5Mde_D_Rq 3;
BA_ "U_CDX706_MY2023_Tx" SG_ 393 Afl5Mde_D_Rq 1;
BA_ "GenSigSendType" SG_ 393 Afl4Mde_D_Rq 3;
BA_ "U_CDX706_MY2023_Tx" SG_ 393 Afl4Mde_D_Rq 1;
BA_ "GenSigSendType" SG_ 393 Afl3Mde_D_Rq 3;
BA_ "U_CDX706_MY2023_Tx" SG_ 393 Afl3Mde_D_Rq 1;
BA_ "GenSigSendType" SG_ 393 Afl2Mde_D_Rq 3;
BA_ "U_CDX706_MY2023_Tx" SG_ 393 Afl2Mde_D_Rq 1;
BA_ "GenSigSendType" SG_ 393 Afl1Mde_D_Rq 3;
BA_ "U_CDX706_MY2023_Tx" SG_ 393 Afl1Mde_D_Rq 1;
BA_ "GenSigSendType" SG_ 393 HeadLghtHi_T_Rq 3;
BA_ "U_CDX706_MY2023_Tx" SG_ 393 HeadLghtHi_T_Rq 1;
BA_ "GenSigSendType" SG_ 393 HeadLghtHi_D_Rq 3;
BA_ "U_CDX706_MY2023_Tx" SG_ 393 HeadLghtHi_D_Rq 1;
BA_ "WakeupSignal" SG_ 1216 SldrlMsgTxt_D2_Rq 1;
BA_ "WakeupSignal" SG_ 1216 SldrlChime_D_Rq 1;
BA_ "WakeupSignal" SG_ 1216 SldrlUnlck_No_Cnt 1;
BA_ "WakeupSignal" SG_ 1216 SldrlChildLck_No_Cnt 1;
BA_ "WakeupSignal" SG_ 1216 Sldrl_D_Stat 1;
BA_ "U_CDX706_MY2023_Rx" SG_ 1216 Sldrl_D_Stat 1;
BA_ "WakeupSignal" SG_ 1217 SldrrUnlck_No_Cnt 1;
BA_ "WakeupSignal" SG_ 1217 SldrrChildLck_No_Cnt 1;
BA_ "WakeupSignal" SG_ 1217 Sldrr_D_Stat 1;
BA_ "U_CDX706_MY2023_Rx" SG_ 1217 Sldrr_D_Stat 1;
BA_ "WakeupSignal" SG_ 1217 SldrrMsgTxt_D2_Rq 1;
BA_ "WakeupSignal" SG_ 1217 SldrrChime_D_Rq 1;
BA_ "GenSigSendType" SG_ 1204 DcacElPwScnd_D_Stat 3;
BA_ "ECGUsedRxSignal" SG_ 1204 DcacElPwScnd_D_Stat 1;
BA_ "U_CDX706_MY2023_Rx" SG_ 1204 DcacElPwScnd_D_Stat 1;
BA_ "GenSigSendType" SG_ 1204 DcacEngOnMsgTxt_D2_Rq 3;
BA_ "ECGUsedRxSignal" SG_ 1204 DcacEngOnMsgTxt_D2_Rq 1;
BA_ "U_CDX706_MY2023_Rx" SG_ 1204 DcacEngOnMsgTxt_D2_Rq 1;
BA_ "GenSigSendType" SG_ 1204 DcacOutScnd_Pw_DsplyMx 3;
BA_ "ECGUsedRxSignal" SG_ 1204 DcacOutScnd_Pw_DsplyMx 1;
BA_ "U_CDX706_MY2023_Rx" SG_ 1204 DcacOutScnd_Pw_DsplyMx 1;
BA_ "GenSigSendType" SG_ 1204 DcacOutScnd_Pw2_Dsply 3;
BA_ "ECGUsedRxSignal" SG_ 1204 DcacOutScnd_Pw2_Dsply 1;
BA_ "U_CDX706_MY2023_Rx" SG_ 1204 DcacOutScnd_Pw2_Dsply 1;
BA_ "GenSigSendType" SG_ 1204 DcacZone3Pw_B_Stat 3;
BA_ "ECGUsedRxSignal" SG_ 1204 DcacZone3Pw_B_Stat 1;
BA_ "U_CDX706_MY2023_Rx" SG_ 1204 DcacZone3Pw_B_Stat 1;
BA_ "GenSigSendType" SG_ 1204 DcacZone2Pw_B_Stat 3;
BA_ "ECGUsedRxSignal" SG_ 1204 DcacZone2Pw_B_Stat 1;
BA_ "U_CDX706_MY2023_Rx" SG_ 1204 DcacZone2Pw_B_Stat 1;
BA_ "GenSigSendType" SG_ 1204 EngIdlShutDwnT_B_Dsply 3;
BA_ "GenSigStartValue" SG_ 816 Dimming_Lvl_RqMnu 1;
BA_ "GenSigStartValue" SG_ 816 DcacLoFuelLim_L_RqMnu 510;
BA_ "WakeupSignal" SG_ 816 KeyPadCodeDgt7_D_Stat 1;
BA_ "WakeupSignal" SG_ 816 KeyPadCodeDgt6_D_Stat 1;
BA_ "WakeupSignal" SG_ 816 KeyPadCodeDgt5_D_Stat 1;
BA_ "WakeupSignal" SG_ 816 KeyPadCodeDgt4_D_Stat 1;
BA_ "WakeupSignal" SG_ 816 KeyPadCodeDgt3_D_Stat 1;
BA_ "WakeupSignal" SG_ 816 KeyPadCodeDgt2_D_Stat 1;
BA_ "WakeupSignal" SG_ 816 KeyPadCodeDgt1_D_Stat 1;
BA_ "WakeupSignal" SG_ 816 CntrStk2_D_RqAssoc 1;
BA_ "GenSigStartValueInteger" SG_ 816 CntrStk2_D_RqAssoc 3;
BA_ "GenSigStartValue" SG_ 816 CntrStk2_D_RqAssoc 3;
BA_ "U_CDX706_MY2023_Rx" SG_ 646 BattTrac3_Pw_LimDchrg 1;
BA_ "U_CDX706_MY2023_Rx" SG_ 646 BattTrac3_Pw_LimChrg 1;
BA_ "U_CDX706_MY2023_Rx" SG_ 646 BattTrac3_Pw_DchrgInst 1;
BA_ "U_CDX706_MY2023_Rx" SG_ 646 BattTrac3_Pw_ChrgInst 1;
BA_ "GenSigStartValueInteger" SG_ 591 BattTrac_U_Nom 1022;
BA_ "GenSigStartValue" SG_ 591 BattTrac_U_Nom 1022;
BA_ "GenSigStartValueInteger" SG_ 591 BattTrac_E_Nom 4094;
BA_ "GenSigStartValue" SG_ 591 BattTrac_E_Nom 4094;
BA_ "GenSigStartValueInteger" SG_ 591 BattTrac_Ah_Nom 4095;
BA_ "GenSigStartValue" SG_ 591 BattTrac_Ah_Nom 4093;
BA_ "GenSigStartValueInteger" SG_ 591 BattTracType_D_Actl 8;
BA_ "GenSigStartValue" SG_ 591 BattTracType_D_Actl 8;
BA_ "GenSigStartValue" SG_ 591 BattChrgRqd_E_Actl 4094;
BA_ "GenSigStartValue" SG_ 627 VehToInfrstrctr_D_Stat 6;
BA_ "GenSigStartValue" SG_ 627 RoadStopLine_L_Est 65534;
BA_ "GenSigStartValue" SG_ 627 TrfcLghtDecel_A_Dsply 126;
BA_ "GenSigStartValue" SG_ 627 TrfcLght_V_Mx 254;
BA_ "GenSigStartValue" SG_ 627 TrfcLght_V_Mn 254;
BA_ "GenSigStartValue" SG_ 630 TrfcLghtRight_T_Actl 254;
BA_ "U_CD764_MY2022_Rx" SG_ 630 TrfcLghtRight_T_Actl 1;
BA_ "U_CD764_MY2022_Rx" SG_ 630 TrfcLghtLeftType_D_Stat 1;
BA_ "U_CD764_MY2022_Rx" SG_ 630 TrfcLghtLeftOn_D_Stat 1;
BA_ "U_CD764_MY2022_Rx" SG_ 630 TrfcLghtLeftColr_D_Stat 1;
BA_ "GenSigStartValue" SG_ 630 TrfcLghtLeft_T_Actl 254;
BA_ "U_CD764_MY2022_Rx" SG_ 630 TrfcLghtLeft_T_Actl 1;
BA_ "U_CD764_MY2022_Rx" SG_ 630 TrfcLghtStrghtType_D_St 1;
BA_ "U_CD764_MY2022_Rx" SG_ 630 TrfcLghtStrghtOn_D_Stat 1;
BA_ "U_CD764_MY2022_Rx" SG_ 630 TrfcLghtStrghtColr_D_St 1;
BA_ "GenSigStartValue" SG_ 630 TrfcLghtStrght_T_Actl 254;
BA_ "U_CD764_MY2022_Rx" SG_ 630 TrfcLghtStrght_T_Actl 1;
BA_ "U_CD764_MY2022_Rx" SG_ 630 TrfcLghtUturnType_D_St 1;
BA_ "U_CD764_MY2022_Rx" SG_ 630 TrfcLghtUturnOn_D_Stat 1;
BA_ "U_CD764_MY2022_Rx" SG_ 630 TrfcLghtUturnColr_D_St 1;
BA_ "GenSigStartValue" SG_ 630 TrfcLghtUturn_T_Actl 254;
BA_ "U_CD764_MY2022_Rx" SG_ 630 TrfcLghtUturn_T_Actl 1;
BA_ "U_CD764_MY2022_Rx" SG_ 630 TrfcLghtRightType_D_St 1;
BA_ "U_CD764_MY2022_Rx" SG_ 630 TrfcLghtRightOn_D_Stat 1;
BA_ "U_CD764_MY2022_Rx" SG_ 630 TrfcLghtRightColr_D_St 1;
BA_ "GenSigSendType" SG_ 650 GridSrvcSbscrb01_D_Stat 3;
BA_ "ECGUsedTxSignal" SG_ 650 GridSrvcSbscrb01_D_Stat 1;
BA_ "GenSigSendType" SG_ 650 GridSrvc01_D_Rq 3;
BA_ "GenSigStartValue" SG_ 650 GridSrvc01_D_Rq 2;
BA_ "ECGUsedTxSignal" SG_ 650 GridSrvc01_D_Rq 1;
BA_ "GenSigSendType" SG_ 650 BptTglCnt_No_Rq 3;
BA_ "GenSigStartValue" SG_ 650 BptTglCnt_No_Rq 14;
BA_ "ECGUsedTxSignal" SG_ 650 BptTglCnt_No_Rq 1;
BA_ "GenSigSendType" SG_ 650 BptTgl_D_Rq 3;
BA_ "GenSigStartValue" SG_ 650 BptTgl_D_Rq 2;
BA_ "ECGUsedTxSignal" SG_ 650 BptTgl_D_Rq 1;
BA_ "GenSigSendType" SG_ 650 BptStrtStop_D_RqCld 3;
BA_ "ECGUsedTxSignal" SG_ 650 BptStrtStop_D_RqCld 1;
BA_ "GenSigSendType" SG_ 650 BptMnSoc_L_RqCld 3;
BA_ "GenSigStartValue" SG_ 650 BptMnSoc_L_RqCld 8190;
BA_ "ECGUsedTxSignal" SG_ 650 BptMnSoc_L_RqCld 1;
BA_ "GenSigSendType" SG_ 650 BptMde_D_RqCld 3;
BA_ "ECGUsedTxSignal" SG_ 650 BptMde_D_RqCld 1;
BA_ "GenSigSendType" SG_ 650 BptIsol_D_Stat 3;
BA_ "GenSigStartValueInteger" SG_ 650 BptIsol_D_Stat 6;
BA_ "GenSigStartValue" SG_ 650 BptIsol_D_Stat 6;
BA_ "ECGUsedTxSignal" SG_ 650 BptIsol_D_Stat 1;
BA_ "GenSigSendType" SG_ 650 BptDly_T_RqCld 3;
BA_ "GenSigStartValue" SG_ 650 BptDly_T_RqCld 62;
BA_ "ECGUsedTxSignal" SG_ 650 BptDly_T_RqCld 1;
BA_ "GenSigSendType" SG_ 650 BptComm_D_Stat 3;
BA_ "ECGUsedTxSignal" SG_ 650 BptComm_D_Stat 1;
BA_ "GenSigSendType" SG_ 650 Bpt_D_StatEvse 3;
BA_ "ECGUsedTxSignal" SG_ 650 Bpt_D_StatEvse 1;
BA_ "GenSigStartValue" SG_ 663 BptDchrg_Pw_Dsply 1022;
BA_ "ECGUsedRxSignal" SG_ 663 BptDchrg_Pw_Dsply 1;
BA_ "GenSigStartValue" SG_ 663 Bpt_I_Est 1022;
BA_ "ECGUsedRxSignal" SG_ 663 Bpt_I_Est 1;
BA_ "GenSigStartValue" SG_ 663 Bpt_Pw_Allw 65534;
BA_ "ECGUsedRxSignal" SG_ 663 Bpt_Pw_Allw 1;
BA_ "GenSigStartValue" SG_ 663 BptDchrg_T_Rmng 32766;
BA_ "ECGUsedRxSignal" SG_ 663 BptDchrg_T_Rmng 1;
BA_ "GenSigStartValue" SG_ 663 BptMnSoc_L_Actl 8190;
BA_ "ECGUsedRxSignal" SG_ 663 BptMnSoc_L_Actl 1;
BA_ "GenSigStartValue" SG_ 655 EvseChrgOutHi_U_ActlBpt 1022;
BA_ "ECGUsedTxSignal" SG_ 655 EvseChrgOutHi_U_ActlBpt 1;
BA_ "GenSigStartValue" SG_ 655 EvseChrgOutHi_I_ActlBpt 32766;
BA_ "ECGUsedTxSignal" SG_ 655 EvseChrgOutHi_I_ActlBpt 1;
BA_ "GenSigStartValue" SG_ 655 EvseDchrg_Pw_Mx 32766;
BA_ "ECGUsedTxSignal" SG_ 655 EvseDchrg_Pw_Mx 1;
BA_ "GenSigStartValue" SG_ 655 EvseDchrg_I_Mx 32766;
BA_ "ECGUsedTxSignal" SG_ 655 EvseDchrg_I_Mx 1;
BA_ "GenSigStartValue" SG_ 1227 DcacCabinScnd_I_Actl 65534;
BA_ "GenSigStartValue" SG_ 1227 DcacOutlet8Scnd_I_Actl 65534;
BA_ "GenSigStartValue" SG_ 1227 DcacOutlet7Scnd_I_Actl 65534;
BA_ "GenSigStartValue" SG_ 1227 DcacOutlet6Scnd_I_Actl 65534;
BA_ "GenSigStartValue" SG_ 1222 DcacOutlet8_I_Actl 65534;
BA_ "GenSigStartValue" SG_ 1222 DcacOutlet7_I_Actl 65534;
BA_ "GenSigStartValue" SG_ 1222 DcacOutlet6_I_Actl 65534;
BA_ "GenSigStartValue" SG_ 1222 DcacCabin_I_Actl 65534;
BA_ "U_CDX706_MY2023_Rx" SG_ 595 DrvIdMde_D_Rq 1;
BA_ "U_CDX706_MY2023_Rx" SG_ 595 DrvIdDelete_No_Rq 1;
BA_ "GenSigSendType" SG_ 596 DrvIdMde_D_Stat 3;
BA_ "U_CDX706_MY2023_Tx" SG_ 596 DrvIdMde_D_Stat 1;
BA_ "GenSigSendType" SG_ 596 DrvIdMatch_No_Actl 3;
BA_ "U_CDX706_MY2023_Tx" SG_ 596 DrvIdMatch_No_Actl 1;
BA_ "GenSigSendType" SG_ 596 DrvIdActn_D_Stat 3;
BA_ "U_CDX706_MY2023_Tx" SG_ 596 DrvIdActn_D_Stat 1;
BA_ "MetaData" SG_ 596 DrvId_No_Cs 1;
BA_ "U_CDX706_MY2023_Tx" SG_ 596 DrvId_No_Cs 1;
BA_ "GenSigSendType" SG_ 596 DrvId_D_Stat 3;
BA_ "U_CDX706_MY2023_Tx" SG_ 596 DrvId_D_Stat 1;
BA_ "GenSigSendType" SG_ 596 DrvExpression_D_Stat 3;
BA_ "U_CDX706_MY2023_Tx" SG_ 596 DrvExpression_D_Stat 1;
BA_ "ContentDependant" SG_ 612 SelDrvMdeSwtch_D_Stat6 1;
BA_ "GenSigSendType" SG_ 2611034328 PARSEDPhysGWM_ECGtoLDCMB 3;
BA_ "ECGUsedTxSignal" SG_ 2611034328 PARSEDPhysGWM_ECGtoLDCMB 1;
BA_ "U_CDX706_MY2023_Tx" SG_ 2611034328 PARSEDPhysGWM_ECGtoLDCMB 1;
BA_ "GenSigSendType" SG_ 2611035352 PARSEDPhysGWM_ECGtoLDCMA 3;
BA_ "ECGUsedTxSignal" SG_ 2611035352 PARSEDPhysGWM_ECGtoLDCMA 1;
BA_ "U_CDX706_MY2023_Tx" SG_ 2611035352 PARSEDPhysGWM_ECGtoLDCMA 1;
BA_ "GenSigSendType" SG_ 2611175502 PARSEDPhysLDCMBtoGWM_ECG 3;
BA_ "ECGUsedRxSignal" SG_ 2611175502 PARSEDPhysLDCMBtoGWM_ECG 1;
BA_ "U_CDX706_MY2023_Rx" SG_ 2611175502 PARSEDPhysLDCMBtoGWM_ECG 1;
BA_ "GenSigSendType" SG_ 2611175503 PARSEDPhysLDCMAtoGWM_ECG 3;
BA_ "ECGUsedRxSignal" SG_ 2611175503 PARSEDPhysLDCMAtoGWM_ECG 1;
BA_ "U_CDX706_MY2023_Rx" SG_ 2611175503 PARSEDPhysLDCMAtoGWM_ECG 1;
BA_ "ECGUsedRxSignal" SG_ 2612224078 PARSEDPushLDCMBtoGWM_ECG 1;
BA_ "U_CDX706_MY2023_Rx" SG_ 2612224078 PARSEDPushLDCMBtoGWM_ECG 1;
BA_ "GenSigSendType" SG_ 2612224079 PARSEDPushLDCMAtoGWM_ECG 3;
BA_ "ECGUsedRxSignal" SG_ 2612224079 PARSEDPushLDCMAtoGWM_ECG 1;
BA_ "U_CDX706_MY2023_Rx" SG_ 2612224079 PARSEDPushLDCMAtoGWM_ECG 1;
BA_ "GenSigSendType" SG_ 2612082904 PARSEDPushFcGWM_ECGtoLDCMB 3;
BA_ "ECGUsedTxSignal" SG_ 2612082904 PARSEDPushFcGWM_ECGtoLDCMB 1;
BA_ "U_CDX706_MY2023_Tx" SG_ 2612082904 PARSEDPushFcGWM_ECGtoLDCMB 1;
BA_ "GenSigSendType" SG_ 2612083928 PARSEDPushFcGWM_ECGtoLDCMA 3;
BA_ "ECGUsedTxSignal" SG_ 2612083928 PARSEDPushFcGWM_ECGtoLDCMA 1;
BA_ "U_CDX706_MY2023_Tx" SG_ 2612083928 PARSEDPushFcGWM_ECGtoLDCMA 1;
BA_ "GenSigSendType" SG_ 2610126926 OTAPhysLDCMBtoGWM_ECG 3;
BA_ "ECGUsedRxSignal" SG_ 2610126926 OTAPhysLDCMBtoGWM_ECG 1;
BA_ "U_CDX706_MY2023_Rx" SG_ 2610126926 OTAPhysLDCMBtoGWM_ECG 1;
BA_ "GenSigSendType" SG_ 2610126927 OTAPhysLDCMAtoGWM_ECG 3;
BA_ "ECGUsedRxSignal" SG_ 2610126927 OTAPhysLDCMAtoGWM_ECG 1;
BA_ "U_CDX706_MY2023_Rx" SG_ 2610126927 OTAPhysLDCMAtoGWM_ECG 1;
BA_ "GenSigSendType" SG_ 2609985752 OTAPhysGWM_ECGtoLDCMB 3;
BA_ "ECGUsedTxSignal" SG_ 2609985752 OTAPhysGWM_ECGtoLDCMB 1;
BA_ "U_CDX706_MY2023_Tx" SG_ 2609985752 OTAPhysGWM_ECGtoLDCMB 1;
BA_ "GenSigSendType" SG_ 2609986776 OTAPhysGWM_ECGtoLDCMA 3;
BA_ "ECGUsedTxSignal" SG_ 2609986776 OTAPhysGWM_ECGtoLDCMA 1;
BA_ "U_CDX706_MY2023_Tx" SG_ 2609986776 OTAPhysGWM_ECGtoLDCMA 1;
BA_ "GenSigStartValue" SG_ 986 PsngrLoad_M_Rq 1022;
BA_ "GenSigStartValue" SG_ 986 Trlr_M_Rq 2046;
BA_ "GenSigStartValue" SG_ 571 VehFalr_Pc_Est 126;
BA_ "GenSigStartValue" SG_ 571 TrlrTngLoad_Pc_Est 126;
BA_ "GenSigStartValue" SG_ 571 TrlrTngLoad_M_Est 2046;
BA_ "GenSigStartValue" SG_ 571 VehPayloadAdd_M_Est 2046;
BA_ "GenSigStartValue" SG_ 571 VehPayload_Pc_Est 126;
BA_ "GenSigStartValue" SG_ 571 VehPayload_M_Est 1022;
BA_ "U_CDX706_MY2023_Rx" SG_ 571 VehPayload_M_Est 1;
BA_ "GenSigSendType" SG_ 2612224024 PARSEDPushTCMtoGWM_ECG 3;
BA_ "ECGUsedRxSignal" SG_ 2612224024 PARSEDPushTCMtoGWM_ECG 1;
BA_ "U_CDX706_MY2023_Rx" SG_ 2612224024 PARSEDPushTCMtoGWM_ECG 1;
BA_ "GenSigSendType" SG_ 2612027608 PARSEDPushFcGWM_ECGtoTCM 3;
BA_ "ECGUsedTxSignal" SG_ 2612027608 PARSEDPushFcGWM_ECGtoTCM 1;
BA_ "U_CDX706_MY2023_Tx" SG_ 2612027608 PARSEDPushFcGWM_ECGtoTCM 1;
BA_ "GenSigSendType" SG_ 2610126872 OTAPhysTCMtoGWM_ECG 3;
BA_ "ECGUsedRxSignal" SG_ 2610126872 OTAPhysTCMtoGWM_ECG 1;
BA_ "U_CDX706_MY2023_Rx" SG_ 2610126872 OTAPhysTCMtoGWM_ECG 1;
BA_ "GenSigSendType" SG_ 2609930456 OTAPhysGWM_ECGtoTCM 3;
BA_ "ECGUsedTxSignal" SG_ 2609930456 OTAPhysGWM_ECGtoTCM 1;
BA_ "U_CDX706_MY2023_Tx" SG_ 2609930456 OTAPhysGWM_ECGtoTCM 1;
BA_ "GenSigSendType" SG_ 2610979032 PARSEDPhysGWM_ECGtoTCM 3;
BA_ "ECGUsedTxSignal" SG_ 2610979032 PARSEDPhysGWM_ECGtoTCM 1;
BA_ "U_CDX706_MY2023_Tx" SG_ 2610979032 PARSEDPhysGWM_ECGtoTCM 1;
BA_ "GenSigSendType" SG_ 2611175448 PARSEDPhysTCMCtoGWM_ECG 3;
BA_ "ECGUsedRxSignal" SG_ 2611175448 PARSEDPhysTCMCtoGWM_ECG 1;
BA_ "U_CDX706_MY2023_Rx" SG_ 2611175448 PARSEDPhysTCMCtoGWM_ECG 1;
BA_ "GenSigStartValue" SG_ 537 BrkVacPmpDmd_D_Stat 2;
BA_ "MetaData" SG_ 537 BrkBstrStat_No_Cs 1;
BA_ "MetaData" SG_ 537 BrkBstrStat_No_Cnt 1;
BA_ "GenSigStartValueInteger" SG_ 1176 BattTracCell45_U_Actl 4094;
BA_ "GenSigStartValue" SG_ 1176 BattTracCell45_U_Actl 4094;
BA_ "U_CDX706_MY2023_Rx" SG_ 1176 BattTracCell45_U_Actl 1;
BA_ "GenSigStartValueInteger" SG_ 1176 BattTracCell44_U_Actl 4094;
BA_ "GenSigStartValue" SG_ 1176 BattTracCell44_U_Actl 4094;
BA_ "U_CDX706_MY2023_Rx" SG_ 1176 BattTracCell44_U_Actl 1;
BA_ "GenSigStartValueInteger" SG_ 1176 BattTracCell43_U_Actl 4094;
BA_ "GenSigStartValue" SG_ 1176 BattTracCell43_U_Actl 4094;
BA_ "U_CDX706_MY2023_Rx" SG_ 1176 BattTracCell43_U_Actl 1;
BA_ "GenSigStartValueInteger" SG_ 1176 BattTracCell42_U_Actl 4094;
BA_ "GenSigStartValue" SG_ 1176 BattTracCell42_U_Actl 4094;
BA_ "U_CDX706_MY2023_Rx" SG_ 1176 BattTracCell42_U_Actl 1;
BA_ "GenSigStartValueInteger" SG_ 1176 BattTracCell41_U_Actl 4094;
BA_ "GenSigStartValue" SG_ 1176 BattTracCell41_U_Actl 4094;
BA_ "U_CDX706_MY2023_Rx" SG_ 1176 BattTracCell41_U_Actl 1;
BA_ "GenSigStartValueInteger" SG_ 1175 BattTracCell40_U_Actl 4094;
BA_ "GenSigStartValue" SG_ 1175 BattTracCell40_U_Actl 4094;
BA_ "U_CDX706_MY2023_Rx" SG_ 1175 BattTracCell40_U_Actl 1;
BA_ "GenSigStartValueInteger" SG_ 1175 BattTracCell39_U_Actl 4094;
BA_ "GenSigStartValue" SG_ 1175 BattTracCell39_U_Actl 4094;
BA_ "U_CDX706_MY2023_Rx" SG_ 1175 BattTracCell39_U_Actl 1;
BA_ "GenSigStartValueInteger" SG_ 1175 BattTracCell38_U_Actl 4094;
BA_ "GenSigStartValue" SG_ 1175 BattTracCell38_U_Actl 4094;
BA_ "U_CDX706_MY2023_Rx" SG_ 1175 BattTracCell38_U_Actl 1;
BA_ "GenSigStartValueInteger" SG_ 1175 BattTracCell37_U_Actl 4094;
BA_ "GenSigStartValue" SG_ 1175 BattTracCell37_U_Actl 4094;
BA_ "U_CDX706_MY2023_Rx" SG_ 1175 BattTracCell37_U_Actl 1;
BA_ "GenSigStartValueInteger" SG_ 1175 BattTracCell36_U_Actl 4094;
BA_ "GenSigStartValue" SG_ 1175 BattTracCell36_U_Actl 4094;
BA_ "U_CDX706_MY2023_Rx" SG_ 1175 BattTracCell36_U_Actl 1;
BA_ "GenSigStartValueInteger" SG_ 1174 BattTracCell35_U_Actl 4094;
BA_ "GenSigStartValue" SG_ 1174 BattTracCell35_U_Actl 4094;
BA_ "U_CDX706_MY2023_Rx" SG_ 1174 BattTracCell35_U_Actl 1;
BA_ "GenSigStartValueInteger" SG_ 1174 BattTracCell34_U_Actl 4094;
BA_ "GenSigStartValue" SG_ 1174 BattTracCell34_U_Actl 4094;
BA_ "U_CDX706_MY2023_Rx" SG_ 1174 BattTracCell34_U_Actl 1;
BA_ "GenSigStartValueInteger" SG_ 1174 BattTracCell33_U_Actl 4094;
BA_ "GenSigStartValue" SG_ 1174 BattTracCell33_U_Actl 4094;
BA_ "U_CDX706_MY2023_Rx" SG_ 1174 BattTracCell33_U_Actl 1;
BA_ "GenSigStartValueInteger" SG_ 1174 BattTracCell32_U_Actl 4094;
BA_ "GenSigStartValue" SG_ 1174 BattTracCell32_U_Actl 4094;
BA_ "U_CDX706_MY2023_Rx" SG_ 1174 BattTracCell32_U_Actl 1;
BA_ "GenSigStartValueInteger" SG_ 1174 BattTracCell31_U_Actl 4094;
BA_ "GenSigStartValue" SG_ 1174 BattTracCell31_U_Actl 4094;
BA_ "U_CDX706_MY2023_Rx" SG_ 1174 BattTracCell31_U_Actl 1;
BA_ "GenSigStartValueInteger" SG_ 1173 BattTracCell30_U_Actl 4094;
BA_ "GenSigStartValue" SG_ 1173 BattTracCell30_U_Actl 4094;
BA_ "U_CDX706_MY2023_Rx" SG_ 1173 BattTracCell30_U_Actl 1;
BA_ "GenSigStartValueInteger" SG_ 1173 BattTracCell29_U_Actl 4094;
BA_ "GenSigStartValue" SG_ 1173 BattTracCell29_U_Actl 4094;
BA_ "U_CDX706_MY2023_Rx" SG_ 1173 BattTracCell29_U_Actl 1;
BA_ "GenSigStartValueInteger" SG_ 1173 BattTracCell28_U_Actl 4094;
BA_ "GenSigStartValue" SG_ 1173 BattTracCell28_U_Actl 4094;
BA_ "U_CDX706_MY2023_Rx" SG_ 1173 BattTracCell28_U_Actl 1;
BA_ "GenSigStartValueInteger" SG_ 1173 BattTracCell27_U_Actl 4094;
BA_ "GenSigStartValue" SG_ 1173 BattTracCell27_U_Actl 4094;
BA_ "U_CDX706_MY2023_Rx" SG_ 1173 BattTracCell27_U_Actl 1;
BA_ "GenSigStartValueInteger" SG_ 1173 BattTracCell26_U_Actl 4094;
BA_ "GenSigStartValue" SG_ 1173 BattTracCell26_U_Actl 4094;
BA_ "U_CDX706_MY2023_Rx" SG_ 1173 BattTracCell26_U_Actl 1;
BA_ "GenSigStartValueInteger" SG_ 1172 BattTracCell25_U_Actl 4094;
BA_ "GenSigStartValue" SG_ 1172 BattTracCell25_U_Actl 4094;
BA_ "U_CDX706_MY2023_Rx" SG_ 1172 BattTracCell25_U_Actl 1;
BA_ "GenSigStartValueInteger" SG_ 1172 BattTracCell24_U_Actl 4094;
BA_ "GenSigStartValue" SG_ 1172 BattTracCell24_U_Actl 4094;
BA_ "U_CDX706_MY2023_Rx" SG_ 1172 BattTracCell24_U_Actl 1;
BA_ "GenSigStartValueInteger" SG_ 1172 BattTracCell23_U_Actl 4094;
BA_ "GenSigStartValue" SG_ 1172 BattTracCell23_U_Actl 4094;
BA_ "U_CDX706_MY2023_Rx" SG_ 1172 BattTracCell23_U_Actl 1;
BA_ "GenSigStartValueInteger" SG_ 1172 BattTracCell22_U_Actl 4094;
BA_ "GenSigStartValue" SG_ 1172 BattTracCell22_U_Actl 4094;
BA_ "U_CDX706_MY2023_Rx" SG_ 1172 BattTracCell22_U_Actl 1;
BA_ "GenSigStartValueInteger" SG_ 1172 BattTracCell21_U_Actl 4094;
BA_ "GenSigStartValue" SG_ 1172 BattTracCell21_U_Actl 4094;
BA_ "U_CDX706_MY2023_Rx" SG_ 1172 BattTracCell21_U_Actl 1;
BA_ "GenSigStartValueInteger" SG_ 1171 BattTracCell20_U_Actl 4094;
BA_ "GenSigStartValue" SG_ 1171 BattTracCell20_U_Actl 4094;
BA_ "U_CDX706_MY2023_Rx" SG_ 1171 BattTracCell20_U_Actl 1;
BA_ "GenSigStartValueInteger" SG_ 1171 BattTracCell19_U_Actl 4094;
BA_ "GenSigStartValue" SG_ 1171 BattTracCell19_U_Actl 4094;
BA_ "U_CDX706_MY2023_Rx" SG_ 1171 BattTracCell19_U_Actl 1;
BA_ "GenSigStartValueInteger" SG_ 1171 BattTracCell18_U_Actl 4094;
BA_ "GenSigStartValue" SG_ 1171 BattTracCell18_U_Actl 4094;
BA_ "U_CDX706_MY2023_Rx" SG_ 1171 BattTracCell18_U_Actl 1;
BA_ "GenSigStartValueInteger" SG_ 1171 BattTracCell17_U_Actl 4094;
BA_ "GenSigStartValue" SG_ 1171 BattTracCell17_U_Actl 4094;
BA_ "U_CDX706_MY2023_Rx" SG_ 1171 BattTracCell17_U_Actl 1;
BA_ "GenSigStartValueInteger" SG_ 1171 BattTracCell16_U_Actl 4094;
BA_ "GenSigStartValue" SG_ 1171 BattTracCell16_U_Actl 4094;
BA_ "U_CDX706_MY2023_Rx" SG_ 1171 BattTracCell16_U_Actl 1;
BA_ "GenSigSendType" SG_ 1822 TesterPhysicalResGWM_F1 3;
BA_ "U_T6_MCA_MY2020_Tx" SG_ 1822 TesterPhysicalResGWM_F1 1;
BA_ "ECGUsedTxSignal" SG_ 1822 TesterPhysicalResGWM_F1 1;
BA_ "U_CD542_MY2021_Tx" SG_ 1822 TesterPhysicalResGWM_F1 1;
BA_ "U_U55X_MY2022_Tx" SG_ 1822 TesterPhysicalResGWM_F1 1;
BA_ "U_CD764_MY2022_Tx" SG_ 1822 TesterPhysicalResGWM_F1 1;
BA_ "U_CDX706_MY2023_Tx" SG_ 1822 TesterPhysicalResGWM_F1 1;
BA_ "GenSigStartValueInteger" SG_ 1438 GWM_GWOnBoardTester 255;
BA_ "ContentDependant" SG_ 1438 GWM_GWOnBoardTester 1;
BA_ "GenSigStartValue" SG_ 1438 GWM_GWOnBoardTester 255;
BA_ "U_P702_MY2021_Rx" SG_ 1438 GWM_GWOnBoardTester 1;
BA_ "U_T6_MCA_MY2020_Rx" SG_ 1438 GWM_GWOnBoardTester 1;
BA_ "U_CD542_MY2021_Rx" SG_ 1438 GWM_GWOnBoardTester 1;
BA_ "U_U55X_MY2022_Rx" SG_ 1438 GWM_GWOnBoardTester 1;
BA_ "U_CD764_MY2022_Rx" SG_ 1438 GWM_GWOnBoardTester 1;
BA_ "U_CDX706_MY2023_Rx" SG_ 1438 GWM_GWOnBoardTester 1;
BA_ "U_T6_MCA_MY2020_Tx" SG_ 1438 GWM_GWOnBoardTester 1;
BA_ "ECGUsedTxSignal" SG_ 1438 GWM_GWOnBoardTester 1;
BA_ "U_CD542_MY2021_Tx" SG_ 1438 GWM_GWOnBoardTester 1;
BA_ "U_U55X_MY2022_Tx" SG_ 1438 GWM_GWOnBoardTester 1;
BA_ "U_CD764_MY2022_Tx" SG_ 1438 GWM_GWOnBoardTester 1;
BA_ "U_CDX706_MY2023_Tx" SG_ 1438 GWM_GWOnBoardTester 1;
BA_ "GenSigStartValueInteger" SG_ 1438 GWM_GWNMProxy 255;
BA_ "ContentDependant" SG_ 1438 GWM_GWNMProxy 1;
BA_ "GenSigStartValue" SG_ 1438 GWM_GWNMProxy 255;
BA_ "U_P702_MY2021_Rx" SG_ 1438 GWM_GWNMProxy 1;
BA_ "U_T6_MCA_MY2020_Rx" SG_ 1438 GWM_GWNMProxy 1;
BA_ "U_CD542_MY2021_Rx" SG_ 1438 GWM_GWNMProxy 1;
BA_ "U_U55X_MY2022_Rx" SG_ 1438 GWM_GWNMProxy 1;
BA_ "U_CD764_MY2022_Rx" SG_ 1438 GWM_GWNMProxy 1;
BA_ "U_CDX706_MY2023_Rx" SG_ 1438 GWM_GWNMProxy 1;
BA_ "U_T6_MCA_MY2020_Tx" SG_ 1438 GWM_GWNMProxy 1;
BA_ "ECGUsedTxSignal" SG_ 1438 GWM_GWNMProxy 1;
BA_ "U_CD542_MY2021_Tx" SG_ 1438 GWM_GWNMProxy 1;
BA_ "U_U55X_MY2022_Tx" SG_ 1438 GWM_GWNMProxy 1;
BA_ "U_CD764_MY2022_Tx" SG_ 1438 GWM_GWNMProxy 1;
BA_ "U_CDX706_MY2023_Tx" SG_ 1438 GWM_GWNMProxy 1;
BA_ "GenSigStartValueInteger" SG_ 1438 GWM_AutoSarNMReserved4 255;
BA_ "ContentDependant" SG_ 1438 GWM_AutoSarNMReserved4 1;
BA_ "GenSigStartValue" SG_ 1438 GWM_AutoSarNMReserved4 255;
BA_ "U_P702_MY2021_Rx" SG_ 1438 GWM_AutoSarNMReserved4 1;
BA_ "U_T6_MCA_MY2020_Rx" SG_ 1438 GWM_AutoSarNMReserved4 1;
BA_ "U_CD542_MY2021_Rx" SG_ 1438 GWM_AutoSarNMReserved4 1;
BA_ "U_U55X_MY2022_Rx" SG_ 1438 GWM_AutoSarNMReserved4 1;
BA_ "U_CD764_MY2022_Rx" SG_ 1438 GWM_AutoSarNMReserved4 1;
BA_ "U_CDX706_MY2023_Rx" SG_ 1438 GWM_AutoSarNMReserved4 1;
BA_ "U_T6_MCA_MY2020_Tx" SG_ 1438 GWM_AutoSarNMReserved4 1;
BA_ "ECGUsedTxSignal" SG_ 1438 GWM_AutoSarNMReserved4 1;
BA_ "U_CD542_MY2021_Tx" SG_ 1438 GWM_AutoSarNMReserved4 1;
BA_ "U_U55X_MY2022_Tx" SG_ 1438 GWM_AutoSarNMReserved4 1;
BA_ "U_CD764_MY2022_Tx" SG_ 1438 GWM_AutoSarNMReserved4 1;
BA_ "U_CDX706_MY2023_Tx" SG_ 1438 GWM_AutoSarNMReserved4 1;
BA_ "GenSigStartValueInteger" SG_ 1438 GWM_AutoSarNMReserved3 255;
BA_ "ContentDependant" SG_ 1438 GWM_AutoSarNMReserved3 1;
BA_ "GenSigStartValue" SG_ 1438 GWM_AutoSarNMReserved3 255;
BA_ "U_P702_MY2021_Rx" SG_ 1438 GWM_AutoSarNMReserved3 1;
BA_ "U_T6_MCA_MY2020_Rx" SG_ 1438 GWM_AutoSarNMReserved3 1;
BA_ "U_CD542_MY2021_Rx" SG_ 1438 GWM_AutoSarNMReserved3 1;
BA_ "U_U55X_MY2022_Rx" SG_ 1438 GWM_AutoSarNMReserved3 1;
BA_ "U_CD764_MY2022_Rx" SG_ 1438 GWM_AutoSarNMReserved3 1;
BA_ "U_CDX706_MY2023_Rx" SG_ 1438 GWM_AutoSarNMReserved3 1;
BA_ "U_T6_MCA_MY2020_Tx" SG_ 1438 GWM_AutoSarNMReserved3 1;
BA_ "ECGUsedTxSignal" SG_ 1438 GWM_AutoSarNMReserved3 1;
BA_ "U_CD542_MY2021_Tx" SG_ 1438 GWM_AutoSarNMReserved3 1;
BA_ "U_U55X_MY2022_Tx" SG_ 1438 GWM_AutoSarNMReserved3 1;
BA_ "U_CD764_MY2022_Tx" SG_ 1438 GWM_AutoSarNMReserved3 1;
BA_ "U_CDX706_MY2023_Tx" SG_ 1438 GWM_AutoSarNMReserved3 1;
BA_ "GenSigStartValueInteger" SG_ 1438 GWM_AutoSarNMReserved2 255;
BA_ "ContentDependant" SG_ 1438 GWM_AutoSarNMReserved2 1;
BA_ "GenSigStartValue" SG_ 1438 GWM_AutoSarNMReserved2 255;
BA_ "U_P702_MY2021_Rx" SG_ 1438 GWM_AutoSarNMReserved2 1;
BA_ "U_T6_MCA_MY2020_Rx" SG_ 1438 GWM_AutoSarNMReserved2 1;
BA_ "U_CD542_MY2021_Rx" SG_ 1438 GWM_AutoSarNMReserved2 1;
BA_ "U_U55X_MY2022_Rx" SG_ 1438 GWM_AutoSarNMReserved2 1;
BA_ "U_CD764_MY2022_Rx" SG_ 1438 GWM_AutoSarNMReserved2 1;
BA_ "U_CDX706_MY2023_Rx" SG_ 1438 GWM_AutoSarNMReserved2 1;
BA_ "U_T6_MCA_MY2020_Tx" SG_ 1438 GWM_AutoSarNMReserved2 1;
BA_ "ECGUsedTxSignal" SG_ 1438 GWM_AutoSarNMReserved2 1;
BA_ "U_CD542_MY2021_Tx" SG_ 1438 GWM_AutoSarNMReserved2 1;
BA_ "U_U55X_MY2022_Tx" SG_ 1438 GWM_AutoSarNMReserved2 1;
BA_ "U_CD764_MY2022_Tx" SG_ 1438 GWM_AutoSarNMReserved2 1;
BA_ "U_CDX706_MY2023_Tx" SG_ 1438 GWM_AutoSarNMReserved2 1;
BA_ "GenSigStartValueInteger" SG_ 1438 GWM_AutoSarNMReserved1 255;
BA_ "ContentDependant" SG_ 1438 GWM_AutoSarNMReserved1 1;
BA_ "GenSigStartValue" SG_ 1438 GWM_AutoSarNMReserved1 255;
BA_ "U_P702_MY2021_Rx" SG_ 1438 GWM_AutoSarNMReserved1 1;
BA_ "U_T6_MCA_MY2020_Rx" SG_ 1438 GWM_AutoSarNMReserved1 1;
BA_ "U_CD542_MY2021_Rx" SG_ 1438 GWM_AutoSarNMReserved1 1;
BA_ "U_U55X_MY2022_Rx" SG_ 1438 GWM_AutoSarNMReserved1 1;
BA_ "U_CD764_MY2022_Rx" SG_ 1438 GWM_AutoSarNMReserved1 1;
BA_ "U_CDX706_MY2023_Rx" SG_ 1438 GWM_AutoSarNMReserved1 1;
BA_ "U_T6_MCA_MY2020_Tx" SG_ 1438 GWM_AutoSarNMReserved1 1;
BA_ "ECGUsedTxSignal" SG_ 1438 GWM_AutoSarNMReserved1 1;
BA_ "U_CD542_MY2021_Tx" SG_ 1438 GWM_AutoSarNMReserved1 1;
BA_ "U_U55X_MY2022_Tx" SG_ 1438 GWM_AutoSarNMReserved1 1;
BA_ "U_CD764_MY2022_Tx" SG_ 1438 GWM_AutoSarNMReserved1 1;
BA_ "U_CDX706_MY2023_Tx" SG_ 1438 GWM_AutoSarNMReserved1 1;
BA_ "GenSigStartValueInteger" SG_ 1438 GWM_AutoSarNMNodeId 158;
BA_ "ContentDependant" SG_ 1438 GWM_AutoSarNMNodeId 1;
BA_ "GenSigStartValue" SG_ 1438 GWM_AutoSarNMNodeId 158;
BA_ "U_P702_MY2021_Rx" SG_ 1438 GWM_AutoSarNMNodeId 1;
BA_ "U_T6_MCA_MY2020_Rx" SG_ 1438 GWM_AutoSarNMNodeId 1;
BA_ "U_CD542_MY2021_Rx" SG_ 1438 GWM_AutoSarNMNodeId 1;
BA_ "U_U55X_MY2022_Rx" SG_ 1438 GWM_AutoSarNMNodeId 1;
BA_ "U_CD764_MY2022_Rx" SG_ 1438 GWM_AutoSarNMNodeId 1;
BA_ "U_CDX706_MY2023_Rx" SG_ 1438 GWM_AutoSarNMNodeId 1;
BA_ "U_T6_MCA_MY2020_Tx" SG_ 1438 GWM_AutoSarNMNodeId 1;
BA_ "ECGUsedTxSignal" SG_ 1438 GWM_AutoSarNMNodeId 1;
BA_ "U_CD542_MY2021_Tx" SG_ 1438 GWM_AutoSarNMNodeId 1;
BA_ "U_U55X_MY2022_Tx" SG_ 1438 GWM_AutoSarNMNodeId 1;
BA_ "U_CD764_MY2022_Tx" SG_ 1438 GWM_AutoSarNMNodeId 1;
BA_ "U_CDX706_MY2023_Tx" SG_ 1438 GWM_AutoSarNMNodeId 1;
BA_ "ContentDependant" SG_ 1438 GWM_AutoSarNMControl 1;
BA_ "U_P702_MY2021_Rx" SG_ 1438 GWM_AutoSarNMControl 1;
BA_ "U_T6_MCA_MY2020_Rx" SG_ 1438 GWM_AutoSarNMControl 1;
BA_ "U_CD542_MY2021_Rx" SG_ 1438 GWM_AutoSarNMControl 1;
BA_ "U_U55X_MY2022_Rx" SG_ 1438 GWM_AutoSarNMControl 1;
BA_ "U_CD764_MY2022_Rx" SG_ 1438 GWM_AutoSarNMControl 1;
BA_ "U_CDX706_MY2023_Rx" SG_ 1438 GWM_AutoSarNMControl 1;
BA_ "U_T6_MCA_MY2020_Tx" SG_ 1438 GWM_AutoSarNMControl 1;
BA_ "ECGUsedTxSignal" SG_ 1438 GWM_AutoSarNMControl 1;
BA_ "U_CD542_MY2021_Tx" SG_ 1438 GWM_AutoSarNMControl 1;
BA_ "U_U55X_MY2022_Tx" SG_ 1438 GWM_AutoSarNMControl 1;
BA_ "U_CD764_MY2022_Tx" SG_ 1438 GWM_AutoSarNMControl 1;
BA_ "U_CDX706_MY2023_Tx" SG_ 1438 GWM_AutoSarNMControl 1;
BA_ "GenSigStartValueInteger" SG_ 1170 BattTracCell15_U_Actl 4094;
BA_ "GenSigStartValue" SG_ 1170 BattTracCell15_U_Actl 4094;
BA_ "U_CDX706_MY2023_Rx" SG_ 1170 BattTracCell15_U_Actl 1;
BA_ "GenSigStartValueInteger" SG_ 1170 BattTracCell14_U_Actl 4094;
BA_ "GenSigStartValue" SG_ 1170 BattTracCell14_U_Actl 4094;
BA_ "U_CDX706_MY2023_Rx" SG_ 1170 BattTracCell14_U_Actl 1;
BA_ "GenSigStartValueInteger" SG_ 1170 BattTracCell13_U_Actl 4094;
BA_ "GenSigStartValue" SG_ 1170 BattTracCell13_U_Actl 4094;
BA_ "U_CDX706_MY2023_Rx" SG_ 1170 BattTracCell13_U_Actl 1;
BA_ "GenSigStartValueInteger" SG_ 1170 BattTracCell12_U_Actl 4094;
BA_ "GenSigStartValue" SG_ 1170 BattTracCell12_U_Actl 4094;
BA_ "U_CDX706_MY2023_Rx" SG_ 1170 BattTracCell12_U_Actl 1;
BA_ "GenSigStartValueInteger" SG_ 1170 BattTracCell11_U_Actl 4094;
BA_ "GenSigStartValue" SG_ 1170 BattTracCell11_U_Actl 4094;
BA_ "U_CDX706_MY2023_Rx" SG_ 1170 BattTracCell11_U_Actl 1;
BA_ "GenSigStartValueInteger" SG_ 1191 BattTracTe14_Te_Actl 254;
BA_ "GenSigStartValue" SG_ 1191 BattTracTe14_Te_Actl 254;
BA_ "U_CDX706_MY2023_Rx" SG_ 1191 BattTracTe14_Te_Actl 1;
BA_ "GenSigStartValueInteger" SG_ 1191 BattTracTe19_Te_Actl 254;
BA_ "GenSigStartValue" SG_ 1191 BattTracTe19_Te_Actl 254;
BA_ "U_CDX706_MY2023_Rx" SG_ 1191 BattTracTe19_Te_Actl 1;
BA_ "GenSigStartValueInteger" SG_ 1191 BattTracTe18_Te_Actl 254;
BA_ "GenSigStartValue" SG_ 1191 BattTracTe18_Te_Actl 254;
BA_ "U_CDX706_MY2023_Rx" SG_ 1191 BattTracTe18_Te_Actl 1;
BA_ "GenSigStartValueInteger" SG_ 1191 BattTracTe17_Te_Actl 254;
BA_ "GenSigStartValue" SG_ 1191 BattTracTe17_Te_Actl 254;
BA_ "U_CDX706_MY2023_Rx" SG_ 1191 BattTracTe17_Te_Actl 1;
BA_ "GenSigStartValueInteger" SG_ 1191 BattTracTe16_Te_Actl 254;
BA_ "GenSigStartValue" SG_ 1191 BattTracTe16_Te_Actl 254;
BA_ "U_CDX706_MY2023_Rx" SG_ 1191 BattTracTe16_Te_Actl 1;
BA_ "GenSigStartValueInteger" SG_ 1191 BattTracTe15_Te_Actl 254;
BA_ "GenSigStartValue" SG_ 1191 BattTracTe15_Te_Actl 254;
BA_ "U_CDX706_MY2023_Rx" SG_ 1191 BattTracTe15_Te_Actl 1;
BA_ "GenSigStartValueInteger" SG_ 1190 BattTracUMxArry_No_Actl 31;
BA_ "GenSigStartValue" SG_ 1190 BattTracUMxArry_No_Actl 31;
BA_ "U_CDX706_MY2023_Rx" SG_ 1190 BattTracUMxArry_No_Actl 1;
BA_ "GenSigStartValueInteger" SG_ 1190 BattTracCellUMx_No_Actl 254;
BA_ "GenSigStartValue" SG_ 1190 BattTracCellUMx_No_Actl 254;
BA_ "U_CDX706_MY2023_Rx" SG_ 1190 BattTracCellUMx_No_Actl 1;
BA_ "U_CDX706_MY2023_Rx" SG_ 1190 BattChrgUMx_B_Falt 1;
BA_ "GenSigStartValueInteger" SG_ 1190 BattTracCellUMn_No_Actl 254;
BA_ "GenSigStartValue" SG_ 1190 BattTracCellUMn_No_Actl 254;
BA_ "U_CDX706_MY2023_Rx" SG_ 1190 BattTracCellUMn_No_Actl 1;
BA_ "GenSigStartValueInteger" SG_ 1190 BattTracCellCnt_No_Actl 254;
BA_ "GenSigStartValue" SG_ 1190 BattTracCellCnt_No_Actl 254;
BA_ "U_CDX706_MY2023_Rx" SG_ 1190 BattTracCellCnt_No_Actl 1;
BA_ "U_CDX706_MY2023_Rx" SG_ 1190 BattChrgIsltn_B_Falt 1;
BA_ "U_CDX706_MY2023_Rx" SG_ 1190 BattTracCellDiff_B_Falt 1;
BA_ "U_CDX706_MY2023_Rx" SG_ 1190 BattChrgSocMx_B_Falt 1;
BA_ "U_CDX706_MY2023_Rx" SG_ 1190 BattChrgSocMn_B_Falt 1;
BA_ "U_CDX706_MY2023_Rx" SG_ 1190 BattChrgSocErrtc_B_Falt 1;
BA_ "U_CDX706_MY2023_Rx" SG_ 1190 BattTracUMx_B_Falt 1;
BA_ "U_CDX706_MY2023_Rx" SG_ 1190 BattTracUMn_B_Falt 1;
BA_ "GenSigStartValueInteger" SG_ 1190 BattTracTeMx_No_Actl 254;
BA_ "GenSigStartValue" SG_ 1190 BattTracTeMx_No_Actl 254;
BA_ "U_CDX706_MY2023_Rx" SG_ 1190 BattTracTeMx_No_Actl 1;
BA_ "U_CDX706_MY2023_Rx" SG_ 1190 BattTracTeMx_B_Falt 1;
BA_ "GenSigStartValueInteger" SG_ 1190 BattTracTeMn_No_Actl 254;
BA_ "GenSigStartValue" SG_ 1190 BattTracTeMn_No_Actl 254;
BA_ "U_CDX706_MY2023_Rx" SG_ 1190 BattTracTeMn_No_Actl 1;
BA_ "U_CDX706_MY2023_Rx" SG_ 1190 BattTracTeDelta_B_Falt 1;
BA_ "GenSigStartValueInteger" SG_ 1190 BattTracTeCnt_No_Actl 254;
BA_ "GenSigStartValue" SG_ 1190 BattTracTeCnt_No_Actl 254;
BA_ "U_CDX706_MY2023_Rx" SG_ 1190 BattTracTeCnt_No_Actl 1;
BA_ "U_CDX706_MY2023_Rx" SG_ 1190 BattTracSoftware_B_Falt 1;
BA_ "GenSigStartValueInteger" SG_ 1188 BattTracTe13_Te_Actl 254;
BA_ "GenSigStartValue" SG_ 1188 BattTracTe13_Te_Actl 254;
BA_ "U_CDX706_MY2023_Rx" SG_ 1188 BattTracTe13_Te_Actl 1;
BA_ "GenSigStartValueInteger" SG_ 1188 BattTracTe12_Te_Actl 254;
BA_ "GenSigStartValue" SG_ 1188 BattTracTe12_Te_Actl 254;
BA_ "U_CDX706_MY2023_Rx" SG_ 1188 BattTracTe12_Te_Actl 1;
BA_ "GenSigStartValueInteger" SG_ 1188 BattTracTe11_Te_Actl 254;
BA_ "GenSigStartValue" SG_ 1188 BattTracTe11_Te_Actl 254;
BA_ "U_CDX706_MY2023_Rx" SG_ 1188 BattTracTe11_Te_Actl 1;
BA_ "GenSigStartValueInteger" SG_ 1188 BattTracTe10_Te_Actl 254;
BA_ "GenSigStartValue" SG_ 1188 BattTracTe10_Te_Actl 254;
BA_ "U_CDX706_MY2023_Rx" SG_ 1188 BattTracTe10_Te_Actl 1;
BA_ "GenSigStartValueInteger" SG_ 1188 BattTracTe09_Te_Actl 254;
BA_ "GenSigStartValue" SG_ 1188 BattTracTe09_Te_Actl 254;
BA_ "U_CDX706_MY2023_Rx" SG_ 1188 BattTracTe09_Te_Actl 1;
BA_ "GenSigStartValueInteger" SG_ 1188 BattTracTe08_Te_Actl 254;
BA_ "GenSigStartValue" SG_ 1188 BattTracTe08_Te_Actl 254;
BA_ "U_CDX706_MY2023_Rx" SG_ 1188 BattTracTe08_Te_Actl 1;
BA_ "GenSigStartValueInteger" SG_ 1188 BattTracTe07_Te_Actl 254;
BA_ "GenSigStartValue" SG_ 1188 BattTracTe07_Te_Actl 254;
BA_ "U_CDX706_MY2023_Rx" SG_ 1188 BattTracTe07_Te_Actl 1;
BA_ "GenSigStartValueInteger" SG_ 1187 BattTracTe06_Te_Actl 254;
BA_ "GenSigStartValue" SG_ 1187 BattTracTe06_Te_Actl 254;
BA_ "U_CDX706_MY2023_Rx" SG_ 1187 BattTracTe06_Te_Actl 1;
BA_ "GenSigStartValueInteger" SG_ 1187 BattTracTe05_Te_Actl 254;
BA_ "GenSigStartValue" SG_ 1187 BattTracTe05_Te_Actl 254;
BA_ "U_CDX706_MY2023_Rx" SG_ 1187 BattTracTe05_Te_Actl 1;
BA_ "GenSigStartValueInteger" SG_ 1187 BattTracTe04_Te_Actl 254;
BA_ "GenSigStartValue" SG_ 1187 BattTracTe04_Te_Actl 254;
BA_ "U_CDX706_MY2023_Rx" SG_ 1187 BattTracTe04_Te_Actl 1;
BA_ "GenSigStartValueInteger" SG_ 1187 BattTracTe03_Te_Actl 254;
BA_ "GenSigStartValue" SG_ 1187 BattTracTe03_Te_Actl 254;
BA_ "U_CDX706_MY2023_Rx" SG_ 1187 BattTracTe03_Te_Actl 1;
BA_ "GenSigStartValueInteger" SG_ 1187 BattTracTe02_Te_Actl 254;
BA_ "GenSigStartValue" SG_ 1187 BattTracTe02_Te_Actl 254;
BA_ "U_CDX706_MY2023_Rx" SG_ 1187 BattTracTe02_Te_Actl 1;
BA_ "GenSigStartValueInteger" SG_ 1187 BattTracTe01_Te_Actl 254;
BA_ "GenSigStartValue" SG_ 1187 BattTracTe01_Te_Actl 254;
BA_ "U_CDX706_MY2023_Rx" SG_ 1187 BattTracTe01_Te_Actl 1;
BA_ "GenSigStartValueInteger" SG_ 1187 BattTracCell96_U_Actl 4094;
BA_ "GenSigStartValue" SG_ 1187 BattTracCell96_U_Actl 4094;
BA_ "U_CDX706_MY2023_Rx" SG_ 1187 BattTracCell96_U_Actl 1;
BA_ "GenSigStartValueInteger" SG_ 1169 BattTracCell10_U_Actl 4094;
BA_ "GenSigStartValue" SG_ 1169 BattTracCell10_U_Actl 4094;
BA_ "U_CDX706_MY2023_Rx" SG_ 1169 BattTracCell10_U_Actl 1;
BA_ "GenSigStartValueInteger" SG_ 1169 BattTracCell09_U_Actl 4094;
BA_ "GenSigStartValue" SG_ 1169 BattTracCell09_U_Actl 4094;
BA_ "U_CDX706_MY2023_Rx" SG_ 1169 BattTracCell09_U_Actl 1;
BA_ "GenSigStartValueInteger" SG_ 1169 BattTracCell08_U_Actl 4094;
BA_ "GenSigStartValue" SG_ 1169 BattTracCell08_U_Actl 4094;
BA_ "U_CDX706_MY2023_Rx" SG_ 1169 BattTracCell08_U_Actl 1;
BA_ "GenSigStartValueInteger" SG_ 1169 BattTracCell07_U_Actl 4094;
BA_ "GenSigStartValue" SG_ 1169 BattTracCell07_U_Actl 4094;
BA_ "U_CDX706_MY2023_Rx" SG_ 1169 BattTracCell07_U_Actl 1;
BA_ "GenSigStartValueInteger" SG_ 1169 BattTracCell06_U_Actl 4094;
BA_ "GenSigStartValue" SG_ 1169 BattTracCell06_U_Actl 4094;
BA_ "U_CDX706_MY2023_Rx" SG_ 1169 BattTracCell06_U_Actl 1;
BA_ "GenSigStartValueInteger" SG_ 1192 BattTracCell95_U_Actl 4094;
BA_ "GenSigStartValue" SG_ 1192 BattTracCell95_U_Actl 4094;
BA_ "U_CDX706_MY2023_Rx" SG_ 1192 BattTracCell95_U_Actl 1;
BA_ "GenSigStartValueInteger" SG_ 1192 BattTracCell94_U_Actl 4094;
BA_ "GenSigStartValue" SG_ 1192 BattTracCell94_U_Actl 4094;
BA_ "U_CDX706_MY2023_Rx" SG_ 1192 BattTracCell94_U_Actl 1;
BA_ "GenSigStartValueInteger" SG_ 1192 BattTracCell93_U_Actl 4094;
BA_ "GenSigStartValue" SG_ 1192 BattTracCell93_U_Actl 4094;
BA_ "U_CDX706_MY2023_Rx" SG_ 1192 BattTracCell93_U_Actl 1;
BA_ "GenSigStartValueInteger" SG_ 1192 BattTracCell92_U_Actl 4094;
BA_ "GenSigStartValue" SG_ 1192 BattTracCell92_U_Actl 4094;
BA_ "U_CDX706_MY2023_Rx" SG_ 1192 BattTracCell92_U_Actl 1;
BA_ "GenSigStartValueInteger" SG_ 1192 BattTracCell91_U_Actl 4094;
BA_ "GenSigStartValue" SG_ 1192 BattTracCell91_U_Actl 4094;
BA_ "U_CDX706_MY2023_Rx" SG_ 1192 BattTracCell91_U_Actl 1;
BA_ "GenSigStartValueInteger" SG_ 1185 BattTracCell90_U_Actl 4094;
BA_ "GenSigStartValue" SG_ 1185 BattTracCell90_U_Actl 4094;
BA_ "U_CDX706_MY2023_Rx" SG_ 1185 BattTracCell90_U_Actl 1;
BA_ "GenSigStartValueInteger" SG_ 1185 BattTracCell89_U_Actl 4094;
BA_ "GenSigStartValue" SG_ 1185 BattTracCell89_U_Actl 4094;
BA_ "U_CDX706_MY2023_Rx" SG_ 1185 BattTracCell89_U_Actl 1;
BA_ "GenSigStartValueInteger" SG_ 1185 BattTracCell88_U_Actl 4094;
BA_ "GenSigStartValue" SG_ 1185 BattTracCell88_U_Actl 4094;
BA_ "U_CDX706_MY2023_Rx" SG_ 1185 BattTracCell88_U_Actl 1;
BA_ "GenSigStartValueInteger" SG_ 1185 BattTracCell87_U_Actl 4094;
BA_ "GenSigStartValue" SG_ 1185 BattTracCell87_U_Actl 4094;
BA_ "U_CDX706_MY2023_Rx" SG_ 1185 BattTracCell87_U_Actl 1;
BA_ "GenSigStartValueInteger" SG_ 1185 BattTracCell86_U_Actl 4094;
BA_ "GenSigStartValue" SG_ 1185 BattTracCell86_U_Actl 4094;
BA_ "U_CDX706_MY2023_Rx" SG_ 1185 BattTracCell86_U_Actl 1;
BA_ "GenSigStartValueInteger" SG_ 1184 BattTracCell85_U_Actl 4094;
BA_ "GenSigStartValue" SG_ 1184 BattTracCell85_U_Actl 4094;
BA_ "U_CDX706_MY2023_Rx" SG_ 1184 BattTracCell85_U_Actl 1;
BA_ "GenSigStartValueInteger" SG_ 1184 BattTracCell84_U_Actl 4094;
BA_ "GenSigStartValue" SG_ 1184 BattTracCell84_U_Actl 4094;
BA_ "U_CDX706_MY2023_Rx" SG_ 1184 BattTracCell84_U_Actl 1;
BA_ "GenSigStartValueInteger" SG_ 1184 BattTracCell83_U_Actl 4094;
BA_ "GenSigStartValue" SG_ 1184 BattTracCell83_U_Actl 4094;
BA_ "U_CDX706_MY2023_Rx" SG_ 1184 BattTracCell83_U_Actl 1;
BA_ "GenSigStartValueInteger" SG_ 1184 BattTracCell82_U_Actl 4094;
BA_ "GenSigStartValue" SG_ 1184 BattTracCell82_U_Actl 4094;
BA_ "U_CDX706_MY2023_Rx" SG_ 1184 BattTracCell82_U_Actl 1;
BA_ "GenSigStartValueInteger" SG_ 1184 BattTracCell81_U_Actl 4094;
BA_ "GenSigStartValue" SG_ 1184 BattTracCell81_U_Actl 4094;
BA_ "U_CDX706_MY2023_Rx" SG_ 1184 BattTracCell81_U_Actl 1;
BA_ "GenSigStartValueInteger" SG_ 1183 BattTracCell80_U_Actl 4094;
BA_ "GenSigStartValue" SG_ 1183 BattTracCell80_U_Actl 4094;
BA_ "U_CDX706_MY2023_Rx" SG_ 1183 BattTracCell80_U_Actl 1;
BA_ "GenSigStartValueInteger" SG_ 1183 BattTracCell79_U_Actl 4094;
BA_ "GenSigStartValue" SG_ 1183 BattTracCell79_U_Actl 4094;
BA_ "U_CDX706_MY2023_Rx" SG_ 1183 BattTracCell79_U_Actl 1;
BA_ "GenSigStartValueInteger" SG_ 1183 BattTracCell78_U_Actl 4094;
BA_ "GenSigStartValue" SG_ 1183 BattTracCell78_U_Actl 4094;
BA_ "U_CDX706_MY2023_Rx" SG_ 1183 BattTracCell78_U_Actl 1;
BA_ "GenSigStartValueInteger" SG_ 1183 BattTracCell77_U_Actl 4094;
BA_ "GenSigStartValue" SG_ 1183 BattTracCell77_U_Actl 4094;
BA_ "U_CDX706_MY2023_Rx" SG_ 1183 BattTracCell77_U_Actl 1;
BA_ "GenSigStartValueInteger" SG_ 1183 BattTracCell76_U_Actl 4094;
BA_ "GenSigStartValue" SG_ 1183 BattTracCell76_U_Actl 4094;
BA_ "U_CDX706_MY2023_Rx" SG_ 1183 BattTracCell76_U_Actl 1;
BA_ "GenSigStartValueInteger" SG_ 1182 BattTracCell75_U_Actl 4094;
BA_ "GenSigStartValue" SG_ 1182 BattTracCell75_U_Actl 4094;
BA_ "U_CDX706_MY2023_Rx" SG_ 1182 BattTracCell75_U_Actl 1;
BA_ "GenSigStartValueInteger" SG_ 1182 BattTracCell74_U_Actl 4094;
BA_ "GenSigStartValue" SG_ 1182 BattTracCell74_U_Actl 4094;
BA_ "U_CDX706_MY2023_Rx" SG_ 1182 BattTracCell74_U_Actl 1;
BA_ "GenSigStartValueInteger" SG_ 1182 BattTracCell73_U_Actl 4094;
BA_ "GenSigStartValue" SG_ 1182 BattTracCell73_U_Actl 4094;
BA_ "U_CDX706_MY2023_Rx" SG_ 1182 BattTracCell73_U_Actl 1;
BA_ "GenSigStartValueInteger" SG_ 1182 BattTracCell72_U_Actl 4094;
BA_ "GenSigStartValue" SG_ 1182 BattTracCell72_U_Actl 4094;
BA_ "U_CDX706_MY2023_Rx" SG_ 1182 BattTracCell72_U_Actl 1;
BA_ "GenSigStartValueInteger" SG_ 1182 BattTracCell71_U_Actl 4094;
BA_ "GenSigStartValue" SG_ 1182 BattTracCell71_U_Actl 4094;
BA_ "U_CDX706_MY2023_Rx" SG_ 1182 BattTracCell71_U_Actl 1;
BA_ "GenSigStartValueInteger" SG_ 1181 BattTracCell70_U_Actl 4094;
BA_ "GenSigStartValue" SG_ 1181 BattTracCell70_U_Actl 4094;
BA_ "U_CDX706_MY2023_Rx" SG_ 1181 BattTracCell70_U_Actl 1;
BA_ "GenSigStartValueInteger" SG_ 1181 BattTracCell69_U_Actl 4094;
BA_ "GenSigStartValue" SG_ 1181 BattTracCell69_U_Actl 4094;
BA_ "U_CDX706_MY2023_Rx" SG_ 1181 BattTracCell69_U_Actl 1;
BA_ "GenSigStartValueInteger" SG_ 1181 BattTracCell68_U_Actl 4094;
BA_ "GenSigStartValue" SG_ 1181 BattTracCell68_U_Actl 4094;
BA_ "U_CDX706_MY2023_Rx" SG_ 1181 BattTracCell68_U_Actl 1;
BA_ "GenSigStartValueInteger" SG_ 1181 BattTracCell67_U_Actl 4094;
BA_ "GenSigStartValue" SG_ 1181 BattTracCell67_U_Actl 4094;
BA_ "U_CDX706_MY2023_Rx" SG_ 1181 BattTracCell67_U_Actl 1;
BA_ "GenSigStartValueInteger" SG_ 1181 BattTracCell66_U_Actl 4094;
BA_ "GenSigStartValue" SG_ 1181 BattTracCell66_U_Actl 4094;
BA_ "U_CDX706_MY2023_Rx" SG_ 1181 BattTracCell66_U_Actl 1;
BA_ "GenSigStartValueInteger" SG_ 1180 BattTracCell65_U_Actl 4094;
BA_ "GenSigStartValue" SG_ 1180 BattTracCell65_U_Actl 4094;
BA_ "U_CDX706_MY2023_Rx" SG_ 1180 BattTracCell65_U_Actl 1;
BA_ "GenSigStartValueInteger" SG_ 1180 BattTracCell64_U_Actl 4094;
BA_ "GenSigStartValue" SG_ 1180 BattTracCell64_U_Actl 4094;
BA_ "U_CDX706_MY2023_Rx" SG_ 1180 BattTracCell64_U_Actl 1;
BA_ "GenSigStartValueInteger" SG_ 1180 BattTracCell63_U_Actl 4094;
BA_ "GenSigStartValue" SG_ 1180 BattTracCell63_U_Actl 4094;
BA_ "U_CDX706_MY2023_Rx" SG_ 1180 BattTracCell63_U_Actl 1;
BA_ "GenSigStartValueInteger" SG_ 1180 BattTracCell62_U_Actl 4094;
BA_ "GenSigStartValue" SG_ 1180 BattTracCell62_U_Actl 4094;
BA_ "U_CDX706_MY2023_Rx" SG_ 1180 BattTracCell62_U_Actl 1;
BA_ "GenSigStartValueInteger" SG_ 1180 BattTracCell61_U_Actl 4094;
BA_ "GenSigStartValue" SG_ 1180 BattTracCell61_U_Actl 4094;
BA_ "U_CDX706_MY2023_Rx" SG_ 1180 BattTracCell61_U_Actl 1;
BA_ "GenSigStartValueInteger" SG_ 1179 BattTracCell60_U_Actl 4094;
BA_ "GenSigStartValue" SG_ 1179 BattTracCell60_U_Actl 4094;
BA_ "U_CDX706_MY2023_Rx" SG_ 1179 BattTracCell60_U_Actl 1;
BA_ "GenSigStartValueInteger" SG_ 1179 BattTracCell59_U_Actl 4094;
BA_ "GenSigStartValue" SG_ 1179 BattTracCell59_U_Actl 4094;
BA_ "U_CDX706_MY2023_Rx" SG_ 1179 BattTracCell59_U_Actl 1;
BA_ "GenSigStartValueInteger" SG_ 1179 BattTracCell58_U_Actl 4094;
BA_ "GenSigStartValue" SG_ 1179 BattTracCell58_U_Actl 4094;
BA_ "U_CDX706_MY2023_Rx" SG_ 1179 BattTracCell58_U_Actl 1;
BA_ "GenSigStartValueInteger" SG_ 1179 BattTracCell57_U_Actl 4094;
BA_ "GenSigStartValue" SG_ 1179 BattTracCell57_U_Actl 4094;
BA_ "U_CDX706_MY2023_Rx" SG_ 1179 BattTracCell57_U_Actl 1;
BA_ "GenSigStartValueInteger" SG_ 1179 BattTracCell56_U_Actl 4094;
BA_ "GenSigStartValue" SG_ 1179 BattTracCell56_U_Actl 4094;
BA_ "U_CDX706_MY2023_Rx" SG_ 1179 BattTracCell56_U_Actl 1;
BA_ "GenSigStartValueInteger" SG_ 1178 BattTracCell55_U_Actl 4094;
BA_ "GenSigStartValue" SG_ 1178 BattTracCell55_U_Actl 4094;
BA_ "U_CDX706_MY2023_Rx" SG_ 1178 BattTracCell55_U_Actl 1;
BA_ "GenSigStartValueInteger" SG_ 1178 BattTracCell54_U_Actl 4094;
BA_ "GenSigStartValue" SG_ 1178 BattTracCell54_U_Actl 4094;
BA_ "U_CDX706_MY2023_Rx" SG_ 1178 BattTracCell54_U_Actl 1;
BA_ "GenSigStartValueInteger" SG_ 1178 BattTracCell53_U_Actl 4094;
BA_ "GenSigStartValue" SG_ 1178 BattTracCell53_U_Actl 4094;
BA_ "U_CDX706_MY2023_Rx" SG_ 1178 BattTracCell53_U_Actl 1;
BA_ "GenSigStartValueInteger" SG_ 1178 BattTracCell52_U_Actl 4094;
BA_ "GenSigStartValue" SG_ 1178 BattTracCell52_U_Actl 4094;
BA_ "U_CDX706_MY2023_Rx" SG_ 1178 BattTracCell52_U_Actl 1;
BA_ "GenSigStartValueInteger" SG_ 1178 BattTracCell51_U_Actl 4094;
BA_ "GenSigStartValue" SG_ 1178 BattTracCell51_U_Actl 4094;
BA_ "U_CDX706_MY2023_Rx" SG_ 1178 BattTracCell51_U_Actl 1;
BA_ "GenSigStartValueInteger" SG_ 1177 BattTracCell50_U_Actl 4094;
BA_ "GenSigStartValue" SG_ 1177 BattTracCell50_U_Actl 4094;
BA_ "U_CDX706_MY2023_Rx" SG_ 1177 BattTracCell50_U_Actl 1;
BA_ "GenSigStartValueInteger" SG_ 1177 BattTracCell49_U_Actl 4094;
BA_ "GenSigStartValue" SG_ 1177 BattTracCell49_U_Actl 4094;
BA_ "U_CDX706_MY2023_Rx" SG_ 1177 BattTracCell49_U_Actl 1;
BA_ "GenSigStartValueInteger" SG_ 1177 BattTracCell48_U_Actl 4094;
BA_ "GenSigStartValue" SG_ 1177 BattTracCell48_U_Actl 4094;
BA_ "U_CDX706_MY2023_Rx" SG_ 1177 BattTracCell48_U_Actl 1;
BA_ "GenSigStartValueInteger" SG_ 1177 BattTracCell47_U_Actl 4094;
BA_ "GenSigStartValue" SG_ 1177 BattTracCell47_U_Actl 4094;
BA_ "U_CDX706_MY2023_Rx" SG_ 1177 BattTracCell47_U_Actl 1;
BA_ "GenSigStartValueInteger" SG_ 1177 BattTracCell46_U_Actl 4094;
BA_ "GenSigStartValue" SG_ 1177 BattTracCell46_U_Actl 4094;
BA_ "U_CDX706_MY2023_Rx" SG_ 1177 BattTracCell46_U_Actl 1;
BA_ "GenSigStartValueInteger" SG_ 1168 BattTracCell05_U_Actl 4094;
BA_ "GenSigStartValue" SG_ 1168 BattTracCell05_U_Actl 4094;
BA_ "U_CDX706_MY2023_Rx" SG_ 1168 BattTracCell05_U_Actl 1;
BA_ "GenSigStartValueInteger" SG_ 1168 BattTracCell04_U_Actl 4094;
BA_ "GenSigStartValue" SG_ 1168 BattTracCell04_U_Actl 4094;
BA_ "U_CDX706_MY2023_Rx" SG_ 1168 BattTracCell04_U_Actl 1;
BA_ "GenSigStartValueInteger" SG_ 1168 BattTracCell03_U_Actl 4094;
BA_ "GenSigStartValue" SG_ 1168 BattTracCell03_U_Actl 4094;
BA_ "U_CDX706_MY2023_Rx" SG_ 1168 BattTracCell03_U_Actl 1;
BA_ "GenSigStartValueInteger" SG_ 1168 BattTracCell02_U_Actl 4094;
BA_ "GenSigStartValue" SG_ 1168 BattTracCell02_U_Actl 4094;
BA_ "U_CDX706_MY2023_Rx" SG_ 1168 BattTracCell02_U_Actl 1;
BA_ "GenSigStartValueInteger" SG_ 1168 BattTracCell01_U_Actl 4094;
BA_ "GenSigStartValue" SG_ 1168 BattTracCell01_U_Actl 4094;
BA_ "U_CDX706_MY2023_Rx" SG_ 1168 BattTracCell01_U_Actl 1;
BA_ "GenSigSendType" SG_ 1245 RearDiffLckLamp_D_Cstm 3;
BA_ "ECGUsedTxSignal" SG_ 1245 RearDiffLckLamp_D_Cstm 1;
BA_ "U_CD764_MY2022_Tx" SG_ 1245 RearDiffLckLamp_D_Cstm 1;
BA_ "U_CDX706_MY2023_Tx" SG_ 1245 RearDiffLckLamp_D_Cstm 1;
BA_ "GenSigSendType" SG_ 1245 FrontDiffLckLamp_D_Cstm 3;
BA_ "ECGUsedTxSignal" SG_ 1245 FrontDiffLckLamp_D_Cstm 1;
BA_ "U_CD764_MY2022_Tx" SG_ 1245 FrontDiffLckLamp_D_Cstm 1;
BA_ "U_CDX706_MY2023_Tx" SG_ 1245 FrontDiffLckLamp_D_Cstm 1;
BA_ "GenSigSendType" SG_ 1245 AwdMdeCstm_D_RqDrv 3;
BA_ "GenSigStartValueInteger" SG_ 1245 AwdMdeCstm_D_RqDrv 5;
BA_ "ECGUsedTxSignal" SG_ 1245 AwdMdeCstm_D_RqDrv 1;
BA_ "U_CD764_MY2022_Tx" SG_ 1245 AwdMdeCstm_D_RqDrv 1;
BA_ "U_CDX706_MY2023_Tx" SG_ 1245 AwdMdeCstm_D_RqDrv 1;
BA_ "GenSigSendType" SG_ 1245 SelDrvMdeAwd2_D_Cstm 3;
BA_ "GenSigStartValueInteger" SG_ 1245 SelDrvMdeAwd2_D_Cstm 31;
BA_ "GenSigStartValue" SG_ 1245 SelDrvMdeAwd2_D_Cstm 31;
BA_ "ECGUsedTxSignal" SG_ 1245 SelDrvMdeAwd2_D_Cstm 1;
BA_ "U_CD764_MY2022_Tx" SG_ 1245 SelDrvMdeAwd2_D_Cstm 1;
BA_ "U_CDX706_MY2023_Tx" SG_ 1245 SelDrvMdeAwd2_D_Cstm 1;
BA_ "GenSigSendType" SG_ 1242 SelDrvMdeCstmPt_D_Rq 3;
BA_ "ECGUsedTxSignal" SG_ 1242 SelDrvMdeCstmPt_D_Rq 1;
BA_ "U_CD764_MY2022_Tx" SG_ 1242 SelDrvMdeCstmPt_D_Rq 1;
BA_ "U_CDX706_MY2023_Tx" SG_ 1242 SelDrvMdeCstmPt_D_Rq 1;
BA_ "GenSigSendType" SG_ 1242 EngExhMdeQuietCstm_D_Rq 3;
BA_ "ECGUsedTxSignal" SG_ 1242 EngExhMdeQuietCstm_D_Rq 1;
BA_ "U_CD764_MY2022_Tx" SG_ 1242 EngExhMdeQuietCstm_D_Rq 1;
BA_ "U_CDX706_MY2023_Tx" SG_ 1242 EngExhMdeQuietCstm_D_Rq 1;
BA_ "GenSigSendType" SG_ 1242 StopStrtCstm_D_Rq 3;
BA_ "ECGUsedTxSignal" SG_ 1242 StopStrtCstm_D_Rq 1;
BA_ "U_CD764_MY2022_Tx" SG_ 1242 StopStrtCstm_D_Rq 1;
BA_ "U_CDX706_MY2023_Tx" SG_ 1242 StopStrtCstm_D_Rq 1;
BA_ "U_P702_MY2021_Rx" SG_ 1116 TrlrAidSetup_D2_Rq 1;
BA_ "U_T6_MCA_MY2020_Rx" SG_ 1116 TrlrAidSetup_D2_Rq 1;
BA_ "U_CD542_MY2021_Rx" SG_ 1116 TrlrAidSetup_D2_Rq 1;
BA_ "U_U55X_MY2022_Rx" SG_ 1116 TrlrAidSetup_D2_Rq 1;
BA_ "U_CD764_MY2022_Rx" SG_ 1116 TrlrAidSetup_D2_Rq 1;
BA_ "U_CDX706_MY2023_Rx" SG_ 1116 TrlrAidSetup_D2_Rq 1;
BA_ "U_P702_MY2021_Rx" SG_ 1116 TrlrAidEnbl_D2_Rq 1;
BA_ "U_T6_MCA_MY2020_Rx" SG_ 1116 TrlrAidEnbl_D2_Rq 1;
BA_ "U_CD542_MY2021_Rx" SG_ 1116 TrlrAidEnbl_D2_Rq 1;
BA_ "U_U55X_MY2022_Rx" SG_ 1116 TrlrAidEnbl_D2_Rq 1;
BA_ "U_CD764_MY2022_Rx" SG_ 1116 TrlrAidEnbl_D2_Rq 1;
BA_ "U_CDX706_MY2023_Rx" SG_ 1116 TrlrAidEnbl_D2_Rq 1;
BA_ "U_T6_MCA_MY2020_Rx" SG_ 1116 TrlrTrgtToBmpr_L_Actl 1;
BA_ "U_CD542_MY2021_Rx" SG_ 1116 TrlrTrgtToBmpr_L_Actl 1;
BA_ "U_U55X_MY2022_Rx" SG_ 1116 TrlrTrgtToBmpr_L_Actl 1;
BA_ "U_CD764_MY2022_Rx" SG_ 1116 TrlrTrgtToBmpr_L_Actl 1;
BA_ "U_CDX706_MY2023_Rx" SG_ 1116 TrlrTrgtToBmpr_L_Actl 1;
BA_ "U_T6_MCA_MY2020_Rx" SG_ 1116 TrlrTrgtPtrnId_No_Mem 1;
BA_ "U_CD542_MY2021_Rx" SG_ 1116 TrlrTrgtPtrnId_No_Mem 1;
BA_ "U_U55X_MY2022_Rx" SG_ 1116 TrlrTrgtPtrnId_No_Mem 1;
BA_ "U_CD764_MY2022_Rx" SG_ 1116 TrlrTrgtPtrnId_No_Mem 1;
BA_ "U_CDX706_MY2023_Rx" SG_ 1116 TrlrTrgtPtrnId_No_Mem 1;
BA_ "U_T6_MCA_MY2020_Rx" SG_ 1116 TrlrRvrseCancl_B_Rq 1;
BA_ "U_CD542_MY2021_Rx" SG_ 1116 TrlrRvrseCancl_B_Rq 1;
BA_ "U_U55X_MY2022_Rx" SG_ 1116 TrlrRvrseCancl_B_Rq 1;
BA_ "U_CD764_MY2022_Rx" SG_ 1116 TrlrRvrseCancl_B_Rq 1;
BA_ "U_CDX706_MY2023_Rx" SG_ 1116 TrlrRvrseCancl_B_Rq 1;
BA_ "U_T6_MCA_MY2020_Rx" SG_ 1116 TrlrIdType_D_Stat 1;
BA_ "U_CD542_MY2021_Rx" SG_ 1116 TrlrIdType_D_Stat 1;
BA_ "U_U55X_MY2022_Rx" SG_ 1116 TrlrIdType_D_Stat 1;
BA_ "U_CD764_MY2022_Rx" SG_ 1116 TrlrIdType_D_Stat 1;
BA_ "U_CDX706_MY2023_Rx" SG_ 1116 TrlrIdType_D_Stat 1;
BA_ "U_T6_MCA_MY2020_Rx" SG_ 1116 TrlrId_No_Actl 1;
BA_ "U_CD542_MY2021_Rx" SG_ 1116 TrlrId_No_Actl 1;
BA_ "U_U55X_MY2022_Rx" SG_ 1116 TrlrId_No_Actl 1;
BA_ "U_CD764_MY2022_Rx" SG_ 1116 TrlrId_No_Actl 1;
BA_ "U_CDX706_MY2023_Rx" SG_ 1116 TrlrId_No_Actl 1;
BA_ "U_T6_MCA_MY2020_Rx" SG_ 1116 TrlrBallToBmpr_L_Actl 1;
BA_ "U_CD542_MY2021_Rx" SG_ 1116 TrlrBallToBmpr_L_Actl 1;
BA_ "U_U55X_MY2022_Rx" SG_ 1116 TrlrBallToBmpr_L_Actl 1;
BA_ "U_CD764_MY2022_Rx" SG_ 1116 TrlrBallToBmpr_L_Actl 1;
BA_ "U_CDX706_MY2023_Rx" SG_ 1116 TrlrBallToBmpr_L_Actl 1;
BA_ "U_T6_MCA_MY2020_Rx" SG_ 1116 TrlrAxleToBmpr_L_Actl 1;
BA_ "U_CD542_MY2021_Rx" SG_ 1116 TrlrAxleToBmpr_L_Actl 1;
BA_ "U_U55X_MY2022_Rx" SG_ 1116 TrlrAxleToBmpr_L_Actl 1;
BA_ "U_CD764_MY2022_Rx" SG_ 1116 TrlrAxleToBmpr_L_Actl 1;
BA_ "U_CDX706_MY2023_Rx" SG_ 1116 TrlrAxleToBmpr_L_Actl 1;
BA_ "U_T6_MCA_MY2020_Rx" SG_ 1116 TrlrAnOffstDir_D_Mem 1;
BA_ "U_CD542_MY2021_Rx" SG_ 1116 TrlrAnOffstDir_D_Mem 1;
BA_ "U_U55X_MY2022_Rx" SG_ 1116 TrlrAnOffstDir_D_Mem 1;
BA_ "U_CD764_MY2022_Rx" SG_ 1116 TrlrAnOffstDir_D_Mem 1;
BA_ "U_CDX706_MY2023_Rx" SG_ 1116 TrlrAnOffstDir_D_Mem 1;
BA_ "U_T6_MCA_MY2020_Rx" SG_ 1116 TrlrAnOffst_An_Mem 1;
BA_ "U_CD542_MY2021_Rx" SG_ 1116 TrlrAnOffst_An_Mem 1;
BA_ "U_U55X_MY2022_Rx" SG_ 1116 TrlrAnOffst_An_Mem 1;
BA_ "U_CD764_MY2022_Rx" SG_ 1116 TrlrAnOffst_An_Mem 1;
BA_ "U_CDX706_MY2023_Rx" SG_ 1116 TrlrAnOffst_An_Mem 1;
BA_ "U_T6_MCA_MY2020_Rx" SG_ 1116 TrlrTrgtOffst_L_Actl 1;
BA_ "U_CD542_MY2021_Rx" SG_ 1116 TrlrTrgtOffst_L_Actl 1;
BA_ "U_U55X_MY2022_Rx" SG_ 1116 TrlrTrgtOffst_L_Actl 1;
BA_ "U_CD764_MY2022_Rx" SG_ 1116 TrlrTrgtOffst_L_Actl 1;
BA_ "U_CDX706_MY2023_Rx" SG_ 1116 TrlrTrgtOffst_L_Actl 1;
BA_ "GenSigSendType" SG_ 1844 TesterPhysicalReqHCM 3;
BA_ "U_CX727_MY2021_Rx" SG_ 1844 TesterPhysicalReqHCM 1;
BA_ "U_P702_MY2021_Rx" SG_ 1844 TesterPhysicalReqHCM 1;
BA_ "U_U55X_MY2022_Rx" SG_ 1844 TesterPhysicalReqHCM 1;
BA_ "U_CD764_MY2022_Rx" SG_ 1844 TesterPhysicalReqHCM 1;
BA_ "WakeupSignal" SG_ 954 ExtLghtFront_D_RqBody 1;
BA_ "GenSigStartValue" SG_ 954 ExtLghtFront_D_RqBody 1;
BA_ "WakeupSignal" SG_ 954 VehWlcmFrwlMde_D_Stat 1;
BA_ "U_T6_MCA_MY2020_Rx" SG_ 954 VehWlcmFrwlMde_D_Stat 1;
BA_ "U_U55X_MY2022_Rx" SG_ 954 VehWlcmFrwlMde_D_Stat 1;
BA_ "U_CD764_MY2022_Rx" SG_ 954 VehWlcmFrwlMde_D_Stat 1;
BA_ "U_CDX706_MY2023_Rx" SG_ 954 ChildLckMaint_D_Stat 1;
BA_ "U_CX727_MY2021_Rx" SG_ 954 GenericSwtch3_No_Actl 1;
BA_ "U_P702_MY2021_Rx" SG_ 954 GenericSwtch3_No_Actl 1;
BA_ "U_U55X_MY2022_Rx" SG_ 954 GenericSwtch3_No_Actl 1;
BA_ "U_CD764_MY2022_Rx" SG_ 954 GenericSwtch3_No_Actl 1;
BA_ "U_CDX706_MY2023_Rx" SG_ 954 GenericSwtch3_No_Actl 1;
BA_ "ContentDependant" SG_ 954 GenericSwtch2_No_Actl 1;
BA_ "U_CX727_MY2021_Rx" SG_ 954 GenericSwtch2_No_Actl 1;
BA_ "U_P702_MY2021_Rx" SG_ 954 GenericSwtch2_No_Actl 1;
BA_ "U_U55X_MY2022_Rx" SG_ 954 GenericSwtch2_No_Actl 1;
BA_ "U_CD764_MY2022_Rx" SG_ 954 GenericSwtch2_No_Actl 1;
BA_ "U_CX727_MY2021_Rx" SG_ 954 GenericSwtch1_No_Actl 1;
BA_ "U_P702_MY2021_Rx" SG_ 954 GenericSwtch1_No_Actl 1;
BA_ "U_U55X_MY2022_Rx" SG_ 954 GenericSwtch1_No_Actl 1;
BA_ "U_CD764_MY2022_Rx" SG_ 954 GenericSwtch1_No_Actl 1;
BA_ "U_CD764_MY2022_Rx" SG_ 954 PosLghtFl_D_Stat 1;
BA_ "U_CD764_MY2022_Rx" SG_ 954 PosLghtFr_D_Stat 1;
BA_ "WakeupSignal" SG_ 954 PudSptLghtRight_D_Rq 1;
BA_ "WakeupSignal" SG_ 954 PudSptLghtLeft_D_Rq 1;
BA_ "WakeupSignal" SG_ 954 ExtLghtRight_D_Stat 1;
BA_ "WakeupSignal" SG_ 954 ExtLghtRear_D_Stat 1;
BA_ "WakeupSignal" SG_ 954 ExtLghtLeft_D_Stat 1;
BA_ "WakeupSignal" SG_ 954 ExtLghtFront_D_Stat 1;
BA_ "WakeupSignal" SG_ 954 LghtAmbDrvMde_B_Stat 1;
BA_ "WakeupSignal" SG_ 954 PwRnngBoardPoll_D_Stat 1;
BA_ "WakeupSignal" SG_ 954 TrlrHitchLamp_D_Stat 1;
BA_ "WakeupSignal" SG_ 954 TrukBedLght_B_Stat 1;
BA_ "WakeupSignal" SG_ 954 VehWlcmFrwl_D_Stat 1;
BA_ "U_T6_MCA_MY2020_Rx" SG_ 954 VehWlcmFrwl_D_Stat 1;
BA_ "U_U55X_MY2022_Rx" SG_ 954 VehWlcmFrwl_D_Stat 1;
BA_ "U_CD764_MY2022_Rx" SG_ 954 VehWlcmFrwl_D_Stat 1;
BA_ "WakeupSignal" SG_ 954 ExtLghtAlrt_B_Rq 1;
BA_ "WakeupSignal" SG_ 954 ExtLght_D_Falt 1;
BA_ "GenSigSendType" SG_ 1852 TesterPhysicalResHCM 3;
BA_ "U_CX727_MY2021_Tx" SG_ 1852 TesterPhysicalResHCM 1;
BA_ "U_P702_MY2021_Tx" SG_ 1852 TesterPhysicalResHCM 1;
BA_ "U_U55X_MY2022_Tx" SG_ 1852 TesterPhysicalResHCM 1;
BA_ "U_CD764_MY2022_Tx" SG_ 1852 TesterPhysicalResHCM 1;
BA_ "GenSigSendType" SG_ 989 FeatNoHcm_No_Actl 3;
BA_ "U_CX727_MY2021_Tx" SG_ 989 FeatNoHcm_No_Actl 1;
BA_ "U_P702_MY2021_Tx" SG_ 989 FeatNoHcm_No_Actl 1;
BA_ "U_U55X_MY2022_Tx" SG_ 989 FeatNoHcm_No_Actl 1;
BA_ "U_CD764_MY2022_Tx" SG_ 989 FeatNoHcm_No_Actl 1;
BA_ "GenSigSendType" SG_ 989 FeatConfigHcmActl 3;
BA_ "U_CX727_MY2021_Tx" SG_ 989 FeatConfigHcmActl 1;
BA_ "U_P702_MY2021_Tx" SG_ 989 FeatConfigHcmActl 1;
BA_ "U_U55X_MY2022_Tx" SG_ 989 FeatConfigHcmActl 1;
BA_ "U_CD764_MY2022_Tx" SG_ 989 FeatConfigHcmActl 1;
BA_ "U_T6_MCA_MY2020_Rx" SG_ 874 AirCondCluOpen_D_Falt 1;
BA_ "U_CD764_MY2022_Rx" SG_ 874 AirCondCluOpen_D_Falt 1;
BA_ "U_CDX706_MY2023_Rx" SG_ 874 AirCondCluOpen_D_Falt 1;
BA_ "U_T6_MCA_MY2020_Rx" SG_ 874 AirCondCluLife_D_Falt 1;
BA_ "U_CD764_MY2022_Rx" SG_ 874 AirCondCluLife_D_Falt 1;
BA_ "U_CDX706_MY2023_Rx" SG_ 874 AirCondCluLife_D_Falt 1;
BA_ "U_T6_MCA_MY2020_Rx" SG_ 874 AirCondCluGnd_D_Falt 1;
BA_ "U_CD764_MY2022_Rx" SG_ 874 AirCondCluGnd_D_Falt 1;
BA_ "U_CDX706_MY2023_Rx" SG_ 874 AirCondCluGnd_D_Falt 1;
BA_ "U_T6_MCA_MY2020_Rx" SG_ 874 AirCondClu_D_Stat 1;
BA_ "U_CD764_MY2022_Rx" SG_ 874 AirCondClu_D_Stat 1;
BA_ "U_CDX706_MY2023_Rx" SG_ 874 AirCondClu_D_Stat 1;
BA_ "U_T6_MCA_MY2020_Rx" SG_ 874 AirCondCluBatt_D_Falt 1;
BA_ "U_CD764_MY2022_Rx" SG_ 874 AirCondCluBatt_D_Falt 1;
BA_ "U_CDX706_MY2023_Rx" SG_ 874 AirCondCluBatt_D_Falt 1;
BA_ "U_CX727_MY2021_Rx" SG_ 874 BattTracShrtGrnd_D_Falt 1;
BA_ "U_P702_MY2021_Rx" SG_ 874 BattTracShrtGrnd_D_Falt 1;
BA_ "U_CD542_MY2021_Rx" SG_ 874 BattTracShrtGrnd_D_Falt 1;
BA_ "U_CX727_MY2021_Rx" SG_ 874 BattTracShrtBatt_D_Falt 1;
BA_ "U_P702_MY2021_Rx" SG_ 874 BattTracShrtBatt_D_Falt 1;
BA_ "U_CD542_MY2021_Rx" SG_ 874 BattTracShrtBatt_D_Falt 1;
BA_ "U_CX727_MY2021_Rx" SG_ 874 BattTracOpnCirct_D_Falt 1;
BA_ "U_P702_MY2021_Rx" SG_ 874 BattTracOpnCirct_D_Falt 1;
BA_ "U_CD542_MY2021_Rx" SG_ 874 BattTracOpnCirct_D_Falt 1;
BA_ "U_CX727_MY2021_Rx" SG_ 874 BattTracLifeLim_D_Falt 1;
BA_ "U_CD542_MY2021_Rx" SG_ 874 BattTracLifeLim_D_Falt 1;
BA_ "U_CX727_MY2021_Rx" SG_ 874 BattChlrShrtGrnd_D_Falt 1;
BA_ "U_P702_MY2021_Rx" SG_ 874 BattChlrShrtGrnd_D_Falt 1;
BA_ "U_CD542_MY2021_Rx" SG_ 874 BattChlrShrtGrnd_D_Falt 1;
BA_ "U_CX727_MY2021_Rx" SG_ 874 BattChlrShrtBatt_D_Falt 1;
BA_ "U_P702_MY2021_Rx" SG_ 874 BattChlrShrtBatt_D_Falt 1;
BA_ "U_CD542_MY2021_Rx" SG_ 874 BattChlrShrtBatt_D_Falt 1;
BA_ "U_CX727_MY2021_Rx" SG_ 874 BattChlrOpnCirct_D_Falt 1;
BA_ "U_P702_MY2021_Rx" SG_ 874 BattChlrOpnCirct_D_Falt 1;
BA_ "U_CD542_MY2021_Rx" SG_ 874 BattChlrOpnCirct_D_Falt 1;
BA_ "U_CD542_MY2021_Rx" SG_ 874 BattChlrLifeLim_D_Falt 1;
BA_ "U_CX727_MY2021_Rx" SG_ 874 BattTracLow_D_Falt 1;
BA_ "U_CD764_MY2022_Rx" SG_ 551 TjaLaneBiasEnbl_D_RqMnu 1;
BA_ "U_CDX706_MY2023_Rx" SG_ 551 TjaLaneBiasEnbl_D_RqMnu 1;
BA_ "U_T6_MCA_MY2020_Rx" SG_ 551 Rba_D_Rq 1;
BA_ "U_CD542_MY2021_Rx" SG_ 551 Rba_D_Rq 1;
BA_ "U_U55X_MY2022_Rx" SG_ 551 Rba_D_Rq 1;
BA_ "U_CD764_MY2022_Rx" SG_ 551 Rba_D_Rq 1;
BA_ "U_CDX706_MY2023_Rx" SG_ 551 Rba_D_Rq 1;
BA_ "WakeupSignal" SG_ 551 Em_D_Stat 1;
BA_ "GenSigStartValue" SG_ 551 ChrgToPcEdit_Pc_RqMnu 126;
BA_ "U_CDX706_MY2023_Rx" SG_ 551 EcoIdl_D_Rq 1;
BA_ "WakeupSignal" SG_ 551 Cntr_Plg_Mode_Cmd 1;
BA_ "U_CDX706_MY2023_Rx" SG_ 551 BattTracLoThres_D_Rq 1;
BA_ "GenSigStartValueInteger" SG_ 551 Btt_L_Actl2 126;
BA_ "GenSigStartValue" SG_ 551 Btt_L_Actl2 126;
BA_ "U_T6_MCA_MY2020_Rx" SG_ 551 Btt_L_Actl2 1;
BA_ "U_U55X_MY2022_Rx" SG_ 551 Btt_L_Actl2 1;
BA_ "U_CX727_MY2021_Rx" SG_ 132 GlblClkYr_No_Actl 1;
BA_ "U_P702_MY2021_Rx" SG_ 132 GlblClkYr_No_Actl 1;
BA_ "U_T6_MCA_MY2020_Rx" SG_ 132 GlblClkYr_No_Actl 1;
BA_ "U_CD542_MY2021_Rx" SG_ 132 GlblClkYr_No_Actl 1;
BA_ "U_U55X_MY2022_Rx" SG_ 132 GlblClkYr_No_Actl 1;
BA_ "U_CD764_MY2022_Rx" SG_ 132 GlblClkYr_No_Actl 1;
BA_ "U_CDX706_MY2023_Rx" SG_ 132 GlblClkYr_No_Actl 1;
BA_ "U_CX727_MY2021_Rx" SG_ 132 GlblClkScnd_No_Actl 1;
BA_ "U_P702_MY2021_Rx" SG_ 132 GlblClkScnd_No_Actl 1;
BA_ "U_T6_MCA_MY2020_Rx" SG_ 132 GlblClkScnd_No_Actl 1;
BA_ "U_CD542_MY2021_Rx" SG_ 132 GlblClkScnd_No_Actl 1;
BA_ "U_U55X_MY2022_Rx" SG_ 132 GlblClkScnd_No_Actl 1;
BA_ "U_CD764_MY2022_Rx" SG_ 132 GlblClkScnd_No_Actl 1;
BA_ "U_CDX706_MY2023_Rx" SG_ 132 GlblClkScnd_No_Actl 1;
BA_ "U_CX727_MY2021_Rx" SG_ 132 GlblClkMnte_No_Actl 1;
BA_ "U_P702_MY2021_Rx" SG_ 132 GlblClkMnte_No_Actl 1;
BA_ "U_T6_MCA_MY2020_Rx" SG_ 132 GlblClkMnte_No_Actl 1;
BA_ "U_CD542_MY2021_Rx" SG_ 132 GlblClkMnte_No_Actl 1;
BA_ "U_U55X_MY2022_Rx" SG_ 132 GlblClkMnte_No_Actl 1;
BA_ "U_CD764_MY2022_Rx" SG_ 132 GlblClkMnte_No_Actl 1;
BA_ "U_CDX706_MY2023_Rx" SG_ 132 GlblClkMnte_No_Actl 1;
BA_ "U_CX727_MY2021_Rx" SG_ 132 GlblClkHr_No_Actl 1;
BA_ "U_P702_MY2021_Rx" SG_ 132 GlblClkHr_No_Actl 1;
BA_ "U_T6_MCA_MY2020_Rx" SG_ 132 GlblClkHr_No_Actl 1;
BA_ "U_CD542_MY2021_Rx" SG_ 132 GlblClkHr_No_Actl 1;
BA_ "U_U55X_MY2022_Rx" SG_ 132 GlblClkHr_No_Actl 1;
BA_ "U_CD764_MY2022_Rx" SG_ 132 GlblClkHr_No_Actl 1;
BA_ "U_CDX706_MY2023_Rx" SG_ 132 GlblClkHr_No_Actl 1;
BA_ "U_CX727_MY2021_Rx" SG_ 132 GlblClkDay_No_Actl 1;
BA_ "U_P702_MY2021_Rx" SG_ 132 GlblClkDay_No_Actl 1;
BA_ "U_T6_MCA_MY2020_Rx" SG_ 132 GlblClkDay_No_Actl 1;
BA_ "U_CD542_MY2021_Rx" SG_ 132 GlblClkDay_No_Actl 1;
BA_ "U_U55X_MY2022_Rx" SG_ 132 GlblClkDay_No_Actl 1;
BA_ "U_CD764_MY2022_Rx" SG_ 132 GlblClkDay_No_Actl 1;
BA_ "U_CDX706_MY2023_Rx" SG_ 132 GlblClkDay_No_Actl 1;
BA_ "GenSigSendType" SG_ 1006 PersIndexIpmb_D_Actl 3;
BA_ "GenSigStartValueInteger" SG_ 1006 PersIndexIpmb_D_Actl 4;
BA_ "GenSigStartValue" SG_ 1006 PersIndexIpmb_D_Actl 4;
BA_ "U_T6_MCA_MY2020_Tx" SG_ 1006 PersIndexIpmb_D_Actl 1;
BA_ "U_CD542_MY2021_Tx" SG_ 1006 PersIndexIpmb_D_Actl 1;
BA_ "U_U55X_MY2022_Tx" SG_ 1006 PersIndexIpmb_D_Actl 1;
BA_ "U_CD764_MY2022_Tx" SG_ 1006 PersIndexIpmb_D_Actl 1;
BA_ "U_CDX706_MY2023_Tx" SG_ 1006 PersIndexIpmb_D_Actl 1;
BA_ "GenSigSendType" SG_ 1006 FeatNoIpmbActl 3;
BA_ "U_T6_MCA_MY2020_Tx" SG_ 1006 FeatNoIpmbActl 1;
BA_ "U_CD542_MY2021_Tx" SG_ 1006 FeatNoIpmbActl 1;
BA_ "U_U55X_MY2022_Tx" SG_ 1006 FeatNoIpmbActl 1;
BA_ "U_CD764_MY2022_Tx" SG_ 1006 FeatNoIpmbActl 1;
BA_ "U_CDX706_MY2023_Tx" SG_ 1006 FeatNoIpmbActl 1;
BA_ "GenSigSendType" SG_ 1006 FeatConfigIpmbActl 3;
BA_ "U_T6_MCA_MY2020_Tx" SG_ 1006 FeatConfigIpmbActl 1;
BA_ "U_CD542_MY2021_Tx" SG_ 1006 FeatConfigIpmbActl 1;
BA_ "U_U55X_MY2022_Tx" SG_ 1006 FeatConfigIpmbActl 1;
BA_ "U_CD764_MY2022_Tx" SG_ 1006 FeatConfigIpmbActl 1;
BA_ "U_CDX706_MY2023_Tx" SG_ 1006 FeatConfigIpmbActl 1;
BA_ "U_T6_MCA_MY2020_Rx" SG_ 1123 GpsUtcYr_No_Actl 1;
BA_ "U_CD542_MY2021_Rx" SG_ 1123 GpsUtcYr_No_Actl 1;
BA_ "U_CD764_MY2022_Rx" SG_ 1123 GpsUtcYr_No_Actl 1;
BA_ "U_CDX706_MY2023_Rx" SG_ 1123 GpsUtcYr_No_Actl 1;
BA_ "GenSigStartValueInteger" SG_ 1123 GpsUtcMnth_No_Actl 1;
BA_ "GenSigStartValue" SG_ 1123 GpsUtcMnth_No_Actl 1;
BA_ "U_T6_MCA_MY2020_Rx" SG_ 1123 GpsUtcMnth_No_Actl 1;
BA_ "U_CD542_MY2021_Rx" SG_ 1123 GpsUtcMnth_No_Actl 1;
BA_ "U_CD764_MY2022_Rx" SG_ 1123 GpsUtcMnth_No_Actl 1;
BA_ "U_CDX706_MY2023_Rx" SG_ 1123 GpsUtcMnth_No_Actl 1;
BA_ "GenSigStartValueInteger" SG_ 1123 GpsUtcDay_No_Actl 1;
BA_ "GenSigStartValue" SG_ 1123 GpsUtcDay_No_Actl 1;
BA_ "U_T6_MCA_MY2020_Rx" SG_ 1123 GpsUtcDay_No_Actl 1;
BA_ "U_CD542_MY2021_Rx" SG_ 1123 GpsUtcDay_No_Actl 1;
BA_ "U_CD764_MY2022_Rx" SG_ 1123 GpsUtcDay_No_Actl 1;
BA_ "U_CDX706_MY2023_Rx" SG_ 1123 GpsUtcDay_No_Actl 1;
BA_ "U_CX727_MY2021_Rx" SG_ 1123 GPS_UTC_seconds 1;
BA_ "U_P702_MY2021_Rx" SG_ 1123 GPS_UTC_seconds 1;
BA_ "U_T6_MCA_MY2020_Rx" SG_ 1123 GPS_UTC_seconds 1;
BA_ "U_CD542_MY2021_Rx" SG_ 1123 GPS_UTC_seconds 1;
BA_ "U_CD764_MY2022_Rx" SG_ 1123 GPS_UTC_seconds 1;
BA_ "U_CDX706_MY2023_Rx" SG_ 1123 GPS_UTC_seconds 1;
BA_ "U_T6_MCA_MY2020_Rx" SG_ 1123 GPS_UTC_minutes 1;
BA_ "U_CD542_MY2021_Rx" SG_ 1123 GPS_UTC_minutes 1;
BA_ "U_CD764_MY2022_Rx" SG_ 1123 GPS_UTC_minutes 1;
BA_ "U_CDX706_MY2023_Rx" SG_ 1123 GPS_UTC_minutes 1;
BA_ "U_T6_MCA_MY2020_Rx" SG_ 1123 GPS_UTC_hours 1;
BA_ "U_CD542_MY2021_Rx" SG_ 1123 GPS_UTC_hours 1;
BA_ "U_CD764_MY2022_Rx" SG_ 1123 GPS_UTC_hours 1;
BA_ "U_CDX706_MY2023_Rx" SG_ 1123 GPS_UTC_hours 1;
BA_ "U_T6_MCA_MY2020_Rx" SG_ 1123 GPS_Compass_direction 1;
BA_ "U_CD542_MY2021_Rx" SG_ 1123 GPS_Compass_direction 1;
BA_ "U_CD764_MY2022_Rx" SG_ 1123 GPS_Compass_direction 1;
BA_ "U_CDX706_MY2023_Rx" SG_ 1123 GPS_Compass_direction 1;
BA_ "U_CX727_MY2021_Rx" SG_ 1123 GPS_Actual_vs_Infer_pos 1;
BA_ "U_P702_MY2021_Rx" SG_ 1123 GPS_Actual_vs_Infer_pos 1;
BA_ "U_T6_MCA_MY2020_Rx" SG_ 1123 GPS_Actual_vs_Infer_pos 1;
BA_ "U_CD542_MY2021_Rx" SG_ 1123 GPS_Actual_vs_Infer_pos 1;
BA_ "U_CD764_MY2022_Rx" SG_ 1123 GPS_Actual_vs_Infer_pos 1;
BA_ "U_CDX706_MY2023_Rx" SG_ 1123 GPS_Actual_vs_Infer_pos 1;
BA_ "U_CX727_MY2021_Rx" SG_ 1123 Gps_B_Falt 1;
BA_ "U_P702_MY2021_Rx" SG_ 1123 Gps_B_Falt 1;
BA_ "U_T6_MCA_MY2020_Rx" SG_ 1123 Gps_B_Falt 1;
BA_ "U_CD542_MY2021_Rx" SG_ 1123 Gps_B_Falt 1;
BA_ "U_CD764_MY2022_Rx" SG_ 1123 Gps_B_Falt 1;
BA_ "U_CDX706_MY2023_Rx" SG_ 1123 Gps_B_Falt 1;
BA_ "U_T6_MCA_MY2020_Rx" SG_ 1123 GPS_Pdop 1;
BA_ "U_CDX706_MY2023_Rx" SG_ 1123 GPS_Pdop 1;
BA_ "U_CX727_MY2021_Rx" SG_ 1122 GPS_Longitude_Minutes 1;
BA_ "U_P702_MY2021_Rx" SG_ 1122 GPS_Longitude_Minutes 1;
BA_ "U_T6_MCA_MY2020_Rx" SG_ 1122 GPS_Longitude_Minutes 1;
BA_ "U_CD542_MY2021_Rx" SG_ 1122 GPS_Longitude_Minutes 1;
BA_ "U_CD764_MY2022_Rx" SG_ 1122 GPS_Longitude_Minutes 1;
BA_ "U_CDX706_MY2023_Rx" SG_ 1122 GPS_Longitude_Minutes 1;
BA_ "U_CX727_MY2021_Rx" SG_ 1122 GPS_Longitude_Min_dec 1;
BA_ "U_P702_MY2021_Rx" SG_ 1122 GPS_Longitude_Min_dec 1;
BA_ "U_T6_MCA_MY2020_Rx" SG_ 1122 GPS_Longitude_Min_dec 1;
BA_ "U_CD542_MY2021_Rx" SG_ 1122 GPS_Longitude_Min_dec 1;
BA_ "U_CD764_MY2022_Rx" SG_ 1122 GPS_Longitude_Min_dec 1;
BA_ "U_CDX706_MY2023_Rx" SG_ 1122 GPS_Longitude_Min_dec 1;
BA_ "GenSigStartValueInteger" SG_ 1122 GPS_Longitude_Degrees 179;
BA_ "U_CX727_MY2021_Rx" SG_ 1122 GPS_Longitude_Degrees 1;
BA_ "U_P702_MY2021_Rx" SG_ 1122 GPS_Longitude_Degrees 1;
BA_ "U_T6_MCA_MY2020_Rx" SG_ 1122 GPS_Longitude_Degrees 1;
BA_ "U_CD542_MY2021_Rx" SG_ 1122 GPS_Longitude_Degrees 1;
BA_ "U_CD764_MY2022_Rx" SG_ 1122 GPS_Longitude_Degrees 1;
BA_ "U_CDX706_MY2023_Rx" SG_ 1122 GPS_Longitude_Degrees 1;
BA_ "U_CX727_MY2021_Rx" SG_ 1122 GPS_Latitude_Minutes 1;
BA_ "U_P702_MY2021_Rx" SG_ 1122 GPS_Latitude_Minutes 1;
BA_ "U_T6_MCA_MY2020_Rx" SG_ 1122 GPS_Latitude_Minutes 1;
BA_ "U_CD542_MY2021_Rx" SG_ 1122 GPS_Latitude_Minutes 1;
BA_ "U_CD764_MY2022_Rx" SG_ 1122 GPS_Latitude_Minutes 1;
BA_ "U_CDX706_MY2023_Rx" SG_ 1122 GPS_Latitude_Minutes 1;
BA_ "U_CX727_MY2021_Rx" SG_ 1122 GPS_Latitude_Min_dec 1;
BA_ "U_P702_MY2021_Rx" SG_ 1122 GPS_Latitude_Min_dec 1;
BA_ "U_T6_MCA_MY2020_Rx" SG_ 1122 GPS_Latitude_Min_dec 1;
BA_ "U_CD542_MY2021_Rx" SG_ 1122 GPS_Latitude_Min_dec 1;
BA_ "U_CD764_MY2022_Rx" SG_ 1122 GPS_Latitude_Min_dec 1;
BA_ "U_CDX706_MY2023_Rx" SG_ 1122 GPS_Latitude_Min_dec 1;
BA_ "U_CX727_MY2021_Rx" SG_ 1122 GPS_Latitude_Degrees 1;
BA_ "U_P702_MY2021_Rx" SG_ 1122 GPS_Latitude_Degrees 1;
BA_ "U_T6_MCA_MY2020_Rx" SG_ 1122 GPS_Latitude_Degrees 1;
BA_ "U_CD542_MY2021_Rx" SG_ 1122 GPS_Latitude_Degrees 1;
BA_ "U_CD764_MY2022_Rx" SG_ 1122 GPS_Latitude_Degrees 1;
BA_ "U_CDX706_MY2023_Rx" SG_ 1122 GPS_Latitude_Degrees 1;
BA_ "U_CX727_MY2021_Rx" SG_ 1122 GpsHsphLongEast_D_Actl 1;
BA_ "U_P702_MY2021_Rx" SG_ 1122 GpsHsphLongEast_D_Actl 1;
BA_ "U_T6_MCA_MY2020_Rx" SG_ 1122 GpsHsphLongEast_D_Actl 1;
BA_ "U_CD542_MY2021_Rx" SG_ 1122 GpsHsphLongEast_D_Actl 1;
BA_ "U_CD764_MY2022_Rx" SG_ 1122 GpsHsphLongEast_D_Actl 1;
BA_ "U_CDX706_MY2023_Rx" SG_ 1122 GpsHsphLongEast_D_Actl 1;
BA_ "U_CX727_MY2021_Rx" SG_ 1122 GpsHsphLattSth_D_Actl 1;
BA_ "U_P702_MY2021_Rx" SG_ 1122 GpsHsphLattSth_D_Actl 1;
BA_ "U_T6_MCA_MY2020_Rx" SG_ 1122 GpsHsphLattSth_D_Actl 1;
BA_ "U_CD542_MY2021_Rx" SG_ 1122 GpsHsphLattSth_D_Actl 1;
BA_ "U_CD764_MY2022_Rx" SG_ 1122 GpsHsphLattSth_D_Actl 1;
BA_ "U_CDX706_MY2023_Rx" SG_ 1122 GpsHsphLattSth_D_Actl 1;
BA_ "U_CX727_MY2021_Rx" SG_ 1003 VehKeyActv_D_Stat 1;
BA_ "U_CD542_MY2021_Rx" SG_ 1003 VehKeyActv_D_Stat 1;
BA_ "U_CDX706_MY2023_Rx" SG_ 1003 VehKeyActv_D_Stat 1;
BA_ "GenSigStartValueInteger" SG_ 1003 PersNoPos_D_Actl 4;
BA_ "GenSigStartValue" SG_ 1003 PersNoPos_D_Actl 4;
BA_ "U_CX727_MY2021_Rx" SG_ 1003 PersSetupRestr_D_Actl 1;
BA_ "U_CD542_MY2021_Rx" SG_ 1003 PersSetupRestr_D_Actl 1;
BA_ "U_CDX706_MY2023_Rx" SG_ 1003 PersSetupRestr_D_Actl 1;
BA_ "U_CX727_MY2021_Rx" SG_ 1003 PersSetupAccessCtrl 1;
BA_ "U_CD542_MY2021_Rx" SG_ 1003 PersSetupAccessCtrl 1;
BA_ "U_CDX706_MY2023_Rx" SG_ 1003 PersSetupAccessCtrl 1;
BA_ "U_CX727_MY2021_Rx" SG_ 1003 PersSetup_No_Actl 1;
BA_ "U_CD542_MY2021_Rx" SG_ 1003 PersSetup_No_Actl 1;
BA_ "U_CDX706_MY2023_Rx" SG_ 1003 PersSetup_No_Actl 1;
BA_ "GenSigStartValueInteger" SG_ 1003 PersConflict_D_Actl 1;
BA_ "GenSigStartValue" SG_ 1003 PersConflict_D_Actl 1;
BA_ "MetaData" SG_ 1003 RecallEvent_No_Cnt 1;
BA_ "U_T6_MCA_MY2020_Rx" SG_ 1003 RecallEvent_No_Cnt 1;
BA_ "U_CD542_MY2021_Rx" SG_ 1003 RecallEvent_No_Cnt 1;
BA_ "U_U55X_MY2022_Rx" SG_ 1003 RecallEvent_No_Cnt 1;
BA_ "U_CD764_MY2022_Rx" SG_ 1003 RecallEvent_No_Cnt 1;
BA_ "U_CDX706_MY2023_Rx" SG_ 1003 RecallEvent_No_Cnt 1;
BA_ "GenSigStartValueInteger" SG_ 1003 PersNo_D_Actl 4;
BA_ "GenSigStartValue" SG_ 1003 PersNo_D_Actl 4;
BA_ "U_CX727_MY2021_Rx" SG_ 1003 PersNo_D_Actl 1;
BA_ "U_T6_MCA_MY2020_Rx" SG_ 1003 PersNo_D_Actl 1;
BA_ "U_CD542_MY2021_Rx" SG_ 1003 PersNo_D_Actl 1;
BA_ "U_U55X_MY2022_Rx" SG_ 1003 PersNo_D_Actl 1;
BA_ "U_CD764_MY2022_Rx" SG_ 1003 PersNo_D_Actl 1;
BA_ "U_CDX706_MY2023_Rx" SG_ 1003 PersNo_D_Actl 1;
BA_ "U_CDX706_MY2023_Rx" SG_ 994 PersCtaSplitView_D_Rq 1;
BA_ "WakeupSignal" SG_ 994 Pers4OptIn_B_Stats 1;
BA_ "WakeupSignal" SG_ 994 Pers3OptIn_B_Stats 1;
BA_ "WakeupSignal" SG_ 994 Pers2OptIn_B_Stats 1;
BA_ "WakeupSignal" SG_ 994 Pers1OptIn_B_Stats 1;
BA_ "GenSigStartValueInteger" SG_ 994 CtrStkPersIndex_D_Actl 4;
BA_ "GenSigStartValue" SG_ 994 CtrStkPersIndex_D_Actl 4;
BA_ "U_CX727_MY2021_Rx" SG_ 994 CtrStkPersIndex_D_Actl 1;
BA_ "U_T6_MCA_MY2020_Rx" SG_ 994 CtrStkPersIndex_D_Actl 1;
BA_ "U_CD542_MY2021_Rx" SG_ 994 CtrStkPersIndex_D_Actl 1;
BA_ "U_U55X_MY2022_Rx" SG_ 994 CtrStkPersIndex_D_Actl 1;
BA_ "U_CD764_MY2022_Rx" SG_ 994 CtrStkPersIndex_D_Actl 1;
BA_ "U_CDX706_MY2023_Rx" SG_ 994 CtrStkPersIndex_D_Actl 1;
BA_ "U_CX727_MY2021_Rx" SG_ 994 CtrStkFeatNoActl 1;
BA_ "U_T6_MCA_MY2020_Rx" SG_ 994 CtrStkFeatNoActl 1;
BA_ "U_CD542_MY2021_Rx" SG_ 994 CtrStkFeatNoActl 1;
BA_ "U_U55X_MY2022_Rx" SG_ 994 CtrStkFeatNoActl 1;
BA_ "U_CD764_MY2022_Rx" SG_ 994 CtrStkFeatNoActl 1;
BA_ "U_CDX706_MY2023_Rx" SG_ 994 CtrStkFeatNoActl 1;
BA_ "U_CX727_MY2021_Rx" SG_ 994 CtrStkFeatConfigActl 1;
BA_ "U_T6_MCA_MY2020_Rx" SG_ 994 CtrStkFeatConfigActl 1;
BA_ "U_CD542_MY2021_Rx" SG_ 994 CtrStkFeatConfigActl 1;
BA_ "U_U55X_MY2022_Rx" SG_ 994 CtrStkFeatConfigActl 1;
BA_ "U_CD764_MY2022_Rx" SG_ 994 CtrStkFeatConfigActl 1;
BA_ "U_CDX706_MY2023_Rx" SG_ 994 CtrStkFeatConfigActl 1;
BA_ "U_CX727_MY2021_Rx" SG_ 994 CtrStkDsplyOp_D_Rq 1;
BA_ "U_T6_MCA_MY2020_Rx" SG_ 994 CtrStkDsplyOp_D_Rq 1;
BA_ "U_CD542_MY2021_Rx" SG_ 994 CtrStkDsplyOp_D_Rq 1;
BA_ "U_U55X_MY2022_Rx" SG_ 994 CtrStkDsplyOp_D_Rq 1;
BA_ "U_CD764_MY2022_Rx" SG_ 994 CtrStkDsplyOp_D_Rq 1;
BA_ "U_CDX706_MY2023_Rx" SG_ 994 CtrStkDsplyOp_D_Rq 1;
VAL_ 495 AlchlLck_D_RqLimActvtn 0 "Cx0_NoRequest" 1 "Cx1_Group1" 2 "Cx2_Group2" 3 "Cx3_Both" ;
VAL_ 495 AlchlLck2_D_RqLim 0 "Cx0_Initializing" 1 "Cx1_NoLimitRequested" 2 "Cx2_Custom1" 3 "Cx3_Custom2" 4 "Cx4_PowerPackBlock_Inhibit" 5 "Cx5_SecureMode" 6 "Cx6_NonMotiveMode" 7 "Cx7_LimitedPropulsion" 8 "Cx8_VslLow_ParkingLowSpeed" 9 "Cx9_VslMed_UrbanSpeeds" 10 "CxA_VslHigh_HighwaySpeeds" 11 "CxB_VslCustom" 12 "CxC_TqLimitHigh_Truncation" 13 "CxD_TqLimitMed_ReducedPower" 14 "CxE_EvOnly" 15 "CxF_SaveEv" 16 "Cx10_ForwardPropulsionOnly" 17 "Cx11_ReversePropulsionOnly" 18 "Cx12_NotUsed_1" 19 "Cx13_NotUsed_2" 20 "Cx14_NotUsed_3" 21 "Cx15_NotUsed_4" 22 "Cx16_NotUsed_5" 23 "Cx17_NotUsed_6" 24 "Cx18_NotUsed_7" 25 "Cx19_NotUsed_8" 26 "Cx1A_NotUsed_9" 27 "Cx1B_NotUsed_10" 28 "Cx1C_NotUsed_11" 29 "Cx1D_NotUsed_12" 30 "Cx1E_NotUsed_13" 31 "Cx1F_NotUsed_14" ;
VAL_ 495 AlchlLck1_D_RqLim 0 "Cx0_Initializing" 1 "Cx1_NoLimitRequested" 2 "Cx2_Custom1" 3 "Cx3_Custom2" 4 "Cx4_PowerPackBlock_Inhibit" 5 "Cx5_SecureMode" 6 "Cx6_NonMotiveMode" 7 "Cx7_LimitedPropulsion" 8 "Cx8_VslLow_ParkingLowSpeed" 9 "Cx9_VslMed_UrbanSpeeds" 10 "CxA_VslHigh_HighwaySpeeds" 11 "CxB_VslCustom" 12 "CxC_TqLimitHigh_Truncation" 13 "CxD_TqLimitMed_ReducedPower" 14 "CxE_EvOnly" 15 "CxF_SaveEv" 16 "Cx10_ForwardPropulsionOnly" 17 "Cx11_ReversePropulsionOnly" 18 "Cx12_NotUsed_1" 19 "Cx13_NotUsed_2" 20 "Cx14_NotUsed_3" 21 "Cx15_NotUsed_4" 22 "Cx16_NotUsed_5" 23 "Cx17_NotUsed_6" 24 "Cx18_NotUsed_7" 25 "Cx19_NotUsed_8" 26 "Cx1A_NotUsed_9" 27 "Cx1B_NotUsed_10" 28 "Cx1C_NotUsed_11" 29 "Cx1D_NotUsed_12" 30 "Cx1E_NotUsed_13" 31 "Cx1F_NotUsed_14" ;
VAL_ 466 AlchlLck1_D_ResLim 0 "Cx0_Initializing" 1 "Cx1_NoLimitRequested" 2 "Cx2_Custom1" 3 "Cx3_Custom2" 4 "Cx4_PowerPackBlock_Inhibit" 5 "Cx5_SecureMode" 6 "Cx6_NonMotiveMode" 7 "Cx7_LimitedPropulsion" 8 "Cx8_VslLow_ParkingLowSpeed" 9 "Cx9_VslMed_UrbanSpeeds" 10 "CxA_VslHigh_HighwaySpeeds" 11 "CxB_VslCustom" 12 "CxC_TqLimitHigh_Truncation" 13 "CxD_TqLimitMed_ReducedPower" 14 "CxE_EvOnly" 15 "CxF_SaveEv" 16 "Cx10_ForwardPropulsionOnly" 17 "Cx11_ReversePropulsionOnly" 18 "Cx12_NotUsed_1" 19 "Cx13_NotUsed_2" 20 "Cx14_NotUsed_3" 21 "Cx15_NotUsed_4" 22 "Cx16_NotUsed_5" 23 "Cx17_NotUsed_6" 24 "Cx18_NotUsed_7" 25 "Cx19_NotUsed_8" 26 "Cx1A_NotUsed_9" 27 "Cx1B_NotUsed_10" 28 "Cx1C_NotUsed_11" 29 "Cx1D_NotUsed_12" 30 "Cx1E_NotUsed_13" 31 "Cx1F_NotUsed_14" ;
VAL_ 466 AlchlLck2_D_ResLim 0 "Cx0_Initializing" 1 "Cx1_NoLimitRequested" 2 "Cx2_Custom1" 3 "Cx3_Custom2" 4 "Cx4_PowerPackBlock_Inhibit" 5 "Cx5_SecureMode" 6 "Cx6_NonMotiveMode" 7 "Cx7_LimitedPropulsion" 8 "Cx8_VslLow_ParmingLowSpeed" 9 "Cx9_VslMed_UrbanSpeeds" 10 "CxA_VslHigh_Highwayspeeds" 11 "CxB_VslCustom" 12 "CxC_TqLimitHigh_Truncation" 13 "CxD_TqLimitMed_ReducedPower" 14 "CxE_EvOnly" 15 "CxF_SaveEv" 16 "Cx10_ForwardPropulsionOnly" 17 "Cx11_ReversePropulsionOnly" 18 "Cx12_NotUsed_1" 19 "Cx13_NotUsed_2" 20 "Cx14_NotUsed_3" 21 "Cx15_NotUsed_4" 22 "Cx16_NotUsed_5" 23 "Cx17_NotUsed_6" 24 "Cx18_NotUsed_7" 25 "Cx19_NotUsed_8" 26 "Cx1A_NotUsed_9" 27 "Cx1B_NotUsed_10" 28 "Cx1C_NotUsed_11" 29 "Cx1D_NotUsed_12" 30 "Cx1E_NotUsed_13" 31 "Cx1F_NotUsed_14" ;
VAL_ 466 AlchlLck1_D_StatLim 0 "Cx0_NotPossible" 1 "Cx1_Possible" 2 "Cx2_Denied" 3 "Cx3_Pending" 4 "Cx4_Accepted" 5 "Cx5_NotUsed_1" 6 "Cx6_NotUsed_2" 7 "Cx7_NotUsed_3" ;
VAL_ 466 AlchlLck2_D_StatLim 0 "Cx0_NotPossible" 1 "Cx1_Possible" 2 "Cx2_Denied" 3 "Cx3_Pending" 4 "Cx4_Accepted" 5 "Cx5_NotUsed_1" 6 "Cx6_NotUsed_2" 7 "Cx7_NotUsed_3" ;
VAL_ 283 AirCondClnt_Te_Actl 255 "Fault" ;
VAL_ 932 RmtCtlBattMntr_B_Falt 1 "Yes" 0 "No" ;
VAL_ 932 VehInhbtMde_D_Stat 7 "NotUsed_3" 6 "NotUsed_2" 5 "NotUsed_1" 4 "FullVehicleOta" 3 "Iviota" 2 "SyncOta" 1 "NoOtaSupport" 0 "Unconfigured" ;
VAL_ 932 VehStrtInhbt_D_Stat 1 "Inhibit" 0 "NoInhibit" ;
VAL_ 932 VehOnCtl_D_Stat 3 "NotUsed" 2 "On" 1 "Off" 0 "Null" ;
VAL_ 932 VehOnSrc2_D_Stat 15 "NotUsed_11" 14 "NotUsed_10" 13 "NotUsed_9" 12 "NotUsed_8" 11 "NotUsed_7" 10 "NotUsed_6" 9 "EsclRssd" 8 "AutonomousVehicle" 7 "SecureIdle" 6 "FleetVehicleInhibit" 5 "StolenVehicleInhibit" 4 "OverTheAir" 3 "RemoteParkAssist" 2 "RemoteStart" 1 "Manual" 0 "Off" ;
VAL_ 781 TrlrTireDual_D_Stat 15 "NotUsed_11" 14 "NotUsed_10" 13 "NotUsed_9" 12 "NotUsed_8" 11 "NotUsed_7" 10 "NotUsed_6" 9 "NotUsed_5" 8 "NotUsed_4" 7 "NotUsed_3" 6 "NotUsed_2" 5 "NotUsed_1" 4 "NotSupported" 3 "Invalid" 2 "InnerTire" 1 "OuterTire" 0 "SystemUnknown" ;
VAL_ 781 TrlrTireSys_D_Stat 15 "NotUsed" 14 "TiresNotTrained" 13 "TrainingComplete" 12 "TrainLMTire" 11 "TrainLRTire" 10 "TrainRMTire" 9 "TrainRRTire" 8 "TrainRFTire" 7 "TrainLFTire" 6 "RequestPressureThresh" 5 "RequestTireCount" 4 "SystemActive" 3 "TireLow" 2 "SensorFault" 1 "System Fault" 0 "SystemUnknown" ;
VAL_ 781 TrlrTireCnt_D_Stat 7 "Faulty" 6 "TwelveTire" 5 "EightTire" 4 "FourTireOneAxle" 3 "SixTire" 2 "FourTire" 1 "TwoTire" 0 "Unconfigured" ;
VAL_ 781 Chirp_D_RqTrlr 3 "NotUsed" 2 "Chirp_2" 1 "Chirp_1" 0 "NoRequest" ;
VAL_ 368 PrplWhlTot_Tq_RqFilt 65535 "Faulty" 65534 "NoDataExists" ;
VAL_ 1267 BattTracLearn_R_Est 1048575 "Faulty" 1048574 "NoDataExists" ;
VAL_ 1267 BattTracLearnRC_C_Est 1048575 "Faulty" 1048574 "NoDataExists" ;
VAL_ 1267 BattTracLearnRC_R_Est 1048575 "Faulty" 1048574 "NoDataExists" ;
VAL_ 393 Afl6Mde_D_Rq 15 "NotUsed_13" 14 "NotUsed_12" 13 "NotUsed_11" 12 "NotUsed_10" 11 "NotUsed_9" 10 "NotUsed_8" 9 "NotUsed_7" 8 "NotUsed_6" 7 "NotUsed_5" 6 "NotUsed_4" 5 "NotUsed_3" 4 "NotUsed_2" 3 "NotUsed_1" 2 "TrafficSignDeGlare" 1 "DarkSpot" 0 "None" ;
VAL_ 393 Afl5Mde_D_Rq 15 "NotUsed_13" 14 "NotUsed_12" 13 "NotUsed_11" 12 "NotUsed_10" 11 "NotUsed_9" 10 "NotUsed_8" 9 "NotUsed_7" 8 "NotUsed_6" 7 "NotUsed_5" 6 "NotUsed_4" 5 "NotUsed_3" 4 "NotUsed_2" 3 "NotUsed_1" 2 "TrafficSignDeGlare" 1 "DarkSpot" 0 "None" ;
VAL_ 393 Afl4Mde_D_Rq 15 "NotUsed_13" 14 "NotUsed_12" 13 "NotUsed_11" 12 "NotUsed_10" 11 "NotUsed_9" 10 "NotUsed_8" 9 "NotUsed_7" 8 "NotUsed_6" 7 "NotUsed_5" 6 "NotUsed_4" 5 "NotUsed_3" 4 "NotUsed_2" 3 "NotUsed_1" 2 "TrafficSignDeGlare" 1 "DarkSpot" 0 "None" ;
VAL_ 393 Afl3Mde_D_Rq 15 "NotUsed_13" 14 "NotUsed_12" 13 "NotUsed_11" 12 "NotUsed_10" 11 "NotUsed_9" 10 "NotUsed_8" 9 "NotUsed_7" 8 "NotUsed_6" 7 "NotUsed_5" 6 "NotUsed_4" 5 "NotUsed_3" 4 "NotUsed_2" 3 "NotUsed_1" 2 "TrafficSignDeGlare" 1 "DarkSpot" 0 "None" ;
VAL_ 393 Afl2Mde_D_Rq 15 "NotUsed_13" 14 "NotUsed_12" 13 "NotUsed_11" 12 "NotUsed_10" 11 "NotUsed_9" 10 "NotUsed_8" 9 "NotUsed_7" 8 "NotUsed_6" 7 "NotUsed_5" 6 "NotUsed_4" 5 "NotUsed_3" 4 "NotUsed_2" 3 "NotUsed_1" 2 "TrafficSignDeGlare" 1 "DarkSpot" 0 "None" ;
VAL_ 393 Afl1Mde_D_Rq 15 "NotUsed_13" 14 "NotUsed_12" 13 "NotUsed_11" 12 "NotUsed_10" 11 "NotUsed_9" 10 "NotUsed_8" 9 "NotUsed_7" 8 "NotUsed_6" 7 "NotUsed_5" 6 "NotUsed_4" 5 "NotUsed_3" 4 "NotUsed_2" 3 "NotUsed_1" 2 "TrafficSignDeGlare" 1 "DarkSpot" 0 "None" ;
VAL_ 393 HeadLghtHi_D_Rq 7 "NotUsed_4" 6 "NotUsed_3" 5 "NotUsed_2" 4 "NotUsed_1" 3 "OnAutomatic" 2 "OnManual" 1 "Flash" 0 "Off" ;
VAL_ 1216 SldrlMsgTxt_D2_Rq 7 "NotUsed_3" 6 "NotUsed_2" 5 "NotUsed_1" 4 "SlidingDrCalibNeeded2" 3 "SlidingDrOpenCltchReleased" 2 "SlidingDrCalibNeeded" 1 "SlidingDrClutchReleased" 0 "Null" ;
VAL_ 1216 SldrlChime_D_Rq 7 "NotUsed3" 6 "NotUsed2" 5 "NotUsed1" 4 "Warning" 3 "WarningRepeated" 2 "Programming" 1 "Operation" 0 "Off" ;
VAL_ 1216 SldrlStat_B_Actl 1 "Ajar" 0 "Closed" ;
VAL_ 1216 PwStepLeft_D_Rq 1 "Deploy" 0 "Null" 3 "NotUsed" 2 "Stow" ;
VAL_ 1216 SldrlUnlckSwtch_D_Stat 3 "InnerHandle" 2 "RearInteriorSwitch" 1 "IpSwitch" 0 "Null" ;
VAL_ 1216 Sldrl_D_Stat 3 "NotCalibrated" 2 "Closing" 1 "Opening" 0 "NotMoving" ;
VAL_ 1217 SldrrUnlckSwtch_D_Stat 3 "InnerHandle" 2 "RearInteriorSwitch" 1 "IpSwitch" 0 "Null" ;
VAL_ 1217 Sldrr_D_Stat 3 "NotCalibrated" 2 "Closing" 1 "Opening" 0 "NotMoving" ;
VAL_ 1217 SldrrStat_B_Actl 1 "Ajar" 0 "Closed" ;
VAL_ 1217 SldrrMsgTxt_D2_Rq 7 "NotUsed_3" 6 "NotUsed_2" 5 "NotUsed_1" 4 "SlidingDrCalibNeeded2" 3 "SlidingDrOpenCltchReleased" 2 "SlidingDrCalibNeeded" 1 "SlidingDrClutchReleased" 0 "Null" ;
VAL_ 1217 SldrrChime_D_Rq 7 "NotUsed3" 6 "NotUsed2" 5 "NotUsed1" 4 "Warning" 3 "WarningRepeated" 2 "Programming" 1 "Operation" 0 "Off" ;
VAL_ 1217 PwStepRight_D_Rq 1 "Deploy" 0 "Null" 3 "NotUsed" 2 "Stow" ;
VAL_ 1204 DcacElPwScnd_D_Stat 3 "NotUsed" 2 "High" 1 "Low" 0 "Off" ;
VAL_ 1204 DcacEngOnMsgTxt_D2_Rq 15 "NotUsed_10" 14 "NotUsed_9" 13 "NotUsed_8" 12 "NotUsed_7" 11 "NotUsed_6" 10 "NotUsed_5" 9 "NotUsed_4" 8 "NotUsed_3" 7 "NotUsed_2" 6 "NotUsed_1" 5 "AeisFinalMinutesWarning" 4 "AeisDoorAjarWarning" 3 "AeisManualOverrideWarning" 2 "DisplayQuestion" 1 "DisplayWarning" 0 "Ok" ;
VAL_ 1204 DcacOutScnd_Pw_DsplyMx 1023 "Faulty" ;
VAL_ 1204 DcacOutScnd_Pw2_Dsply 8191 "Faulty" 8190 "NoDataExists" ;
VAL_ 1204 DcacZone3Pw_B_Stat 1 "On" 0 "Off" ;
VAL_ 1204 DcacZone2Pw_B_Stat 1 "On" 0 "Off" ;
VAL_ 1204 EngIdlShutDwnT_B_Dsply 1 "On" 0 "Off" ;
VAL_ 816 Dimming_Lvl_RqMnu 31 "NotUsed_11" 30 "NotUsed_10" 29 "NotUsed_9" 28 "NotUsed_8" 27 "NotUsed_7" 26 "NotUsed_6" 25 "NotUsed_5" 24 "NotUsed_4" 23 "NotUsed_3" 22 "NotUsed_2" 21 "NotUsed_1" 20 "Up" 19 "Down" 18 "Day_6" 17 "Day_5" 16 "Day_4" 15 "Day_3" 14 "Day_2" 13 "Day_1" 12 "Night_12" 11 "Night_11" 10 "Night_10" 9 "Night_9" 8 "Night_8" 7 "Night_7" 6 "Night_6" 5 "Night_5" 4 "Night_4" 3 "Night_3" 2 "Night_2" 1 "Night_1" 0 "NotPressed" ;
VAL_ 816 DcacPwResetScnd_B_Rq 1 "Reset" 0 "Null" ;
VAL_ 816 DcacPwScnd_D_Rq 3 "High" 2 "Low" 1 "Off" 0 "Null" ;
VAL_ 816 DcacZone3Pw_D_Rq 3 "NotUsed" 2 "On" 1 "Off" 0 "Null" ;
VAL_ 816 DcacZone2Pw_D_Rq 3 "NotUsed" 2 "On" 1 "Off" 0 "Null" ;
VAL_ 816 DcacAllZone_D_Rq 3 "NotUsed" 2 "On" 1 "Off" 0 "Null" ;
VAL_ 816 DcacLoFuelLim_L_RqMnu 511 "Faulty" 510 "NoDataExists" ;
VAL_ 816 KeylessIdl_D_Rq 3 "Cancel" 2 "IgnitionOff" 1 "Active" 0 "Inactive" ;
VAL_ 816 KeyPadCodeDgt7_D_Stat 15 "NotUsed_4" 14 "NotUsed_3" 13 "NotUsed_2" 12 "NotUsed_1" 11 "Button7_8and9_0" 10 "Button0" 9 "Button9_0or9" 8 "Button8" 7 "Button7_8or7" 6 "Button6" 5 "Button5_6or5" 4 "Button4" 3 "Button3_4or3" 2 "Button2" 1 "Button1_2or1" 0 "EndofString" ;
VAL_ 816 KeyPadCodeDgt6_D_Stat 15 "NotUsed_4" 14 "NotUsed_3" 13 "NotUsed_2" 12 "NotUsed_1" 11 "Button7_8and9_0" 10 "Button0" 9 "Button9_0or9" 8 "Button8" 7 "Button7_8or7" 6 "Button6" 5 "Button5_6or5" 4 "Button4" 3 "Button3_4or3" 2 "Button2" 1 "Button1_2or1" 0 "EndofString" ;
VAL_ 816 KeyPadCodeDgt5_D_Stat 15 "NotUsed_4" 14 "NotUsed_3" 13 "NotUsed_2" 12 "NotUsed_1" 11 "Button7_8and9_0" 10 "Button0" 9 "Button9_0or9" 8 "Button8" 7 "Button7_8or7" 6 "Button6" 5 "Button5_6or5" 4 "Button4" 3 "Button3_4or3" 2 "Button2" 1 "Button1_2or1" 0 "EndofString" ;
VAL_ 816 KeyPadCodeDgt4_D_Stat 15 "NotUsed_4" 14 "NotUsed_3" 13 "NotUsed_2" 12 "NotUsed_1" 11 "Button7_8and9_0" 10 "Button0" 9 "Button9_0or9" 8 "Button8" 7 "Button7_8or7" 6 "Button6" 5 "Button5_6or5" 4 "Button4" 3 "Button3_4or3" 2 "Button2" 1 "Button1_2or1" 0 "EndofString" ;
VAL_ 816 KeyPadCodeDgt3_D_Stat 15 "NotUsed_4" 14 "NotUsed_3" 13 "NotUsed_2" 12 "NotUsed_1" 11 "Button7_8and9_0" 10 "Button0" 9 "Button9_0or9" 8 "Button8" 7 "Button7_8or7" 6 "Button6" 5 "Button5_6or5" 4 "Button4" 3 "Button3_4or3" 2 "Button2" 1 "Button1_2or1" 0 "EndofString" ;
VAL_ 816 KeyPadCodeDgt2_D_Stat 15 "NotUsed_4" 14 "NotUsed_3" 13 "NotUsed_2" 12 "NotUsed_1" 11 "Button7_8and9_0" 10 "Button0" 9 "Button9_0or9" 8 "Button8" 7 "Button7_8or7" 6 "Button6" 5 "Button5_6or5" 4 "Button4" 3 "Button3_4or3" 2 "Button2" 1 "Button1_2or1" 0 "EndofString" ;
VAL_ 816 HybMdeSel_D_Rq 7 "NotUsed_2" 6 "NotUsed_1" 5 "EV_Override_Mode" 4 "EV_Charge_Mode" 3 "EV_Later_Mode" 2 "EV_Now_Mode" 1 "EV_Auto_Mode" 0 "Null" ;
VAL_ 816 KeyPadCodeDgt1_D_Stat 15 "NotUsed_4" 14 "NotUsed_3" 13 "NotUsed_2" 12 "NotUsed_1" 11 "Button7_8and9_0" 10 "Button0" 9 "Button9_0or9" 8 "Button8" 7 "Button7_8or7" 6 "Button6" 5 "Button5_6or5" 4 "Button4" 3 "Button3_4or3" 2 "Button2" 1 "Button1_2or1" 0 "EndofString" ;
VAL_ 816 CntrStk2_D_RqAssoc 7 "Unused_2" 6 "Cancel" 5 "Set_Keycode" 4 "RKE" 3 "Null" 2 "Key" 1 "Erase_KeyCode" 0 "Check_KeyCode" ;
VAL_ 805 InstFeTripUnit_D_Stat 15 "NotUsed_12" 14 "NotUsed_11" 13 "NotUsed_10" 12 "NotUsed_9" 11 "NotUsed_8" 10 "NotUsed_7" 9 "NotUsed_6" 8 "NotUsed_5" 7 "NotUsed_4" 6 "NotUsed_3" 5 "NotUsed_2" 4 "NotUsed_1" 3 "LiterPer100kilometer" 2 "KilometerPerLiter" 1 "MilePerGallon" 0 "Inactive" ;
VAL_ 591 BattTrac_U_Nom 1023 "Faulty" 1022 "NoDataExists" ;
VAL_ 591 BattTrac_E_Nom 4095 "Faulty" 4094 "NoDataExists" ;
VAL_ 591 BattTrac_Ah_Nom 4095 "Faulty" ;
VAL_ 591 BattTracType_D_Actl 15 "NotUsed_7" 14 "NotUsed_6" 13 "NotUsed_5" 12 "NotUsed_4" 11 "NotUsed_3" 10 "NotUsed_2" 9 "NotUsed_1" 8 "Other" 7 "LithiumTitanateOxide" 6 "LithiumIonPolymer" 5 "TernaryMaterial" 4 "LithiumCobaltOxide" 3 "LithiumManganese" 2 "LithiumIronPhosphate" 1 "NickelMetalHydride" 0 "LeadAcid" ;
VAL_ 591 BattChrgRqd_E_Actl 4095 "Faulty" 4094 "NoDataExists" ;
VAL_ 627 VehToInfrstrctr_D_Stat 3 "SubComponentUnknownError" 2 "LostConnection" 1 "InServiceWithoutV2IData" 0 "InServiceFunctionOK" 7 "Faulty" 6 "NoDataExists" 5 "NotUsed_2" 4 "NotUsed_1" ;
VAL_ 627 RoadStopLineL_B_Avail 1 "On" 0 "Off" ;
VAL_ 627 RoadStopLine_L_Est 65535 "Faulty" 65534 "NoDataExists" ;
VAL_ 627 RoadSignInfo1_D_Dsply 255 "Faulty" 254 "NoDataExists" 253 "NotUsed_219" 35 "NotUsed_1" 34 "DangerRoadAhead" 33 "WaterPipeBreak" 32 "WaterOnRoad" 31 "VehiclesInQue" 30 "VehicleBreak" 29 "TunnelInWaterAhead" 28 "TrafficControlAhead" 27 "TrafficAccidentAhead" 26 "Speedlimit_120" 25 "Speedlimit_110" 24 "Speedlimit_100" 23 "Speedlimit_90" 22 "Speedlimit_80" 21 "Speedlimit_70" 20 "Speedlimit_60" 19 "Speedlimit_50" 18 "Speedlimit_40" 17 "Speedlimit_30" 16 "Speedlimit_20" 15 "Speedlimit_10" 14 "SlipperyRoad" 13 "SandstormAhead" 12 "FrozenRoad" 11 "FireAlarmOnRoad" 10 "RoadCrack" 9 "RainOrSnowRoad" 8 "Pedestrian" 7 "GoodsDrop" 6 "GasPipeLeakWarning" 5 "FogAhead" 4 "DriveWrongWay" 3 "CrossWindAhead" 2 "RoadWorksAhead" 1 "SlowTrafficAhead" 0 "Inactive" ;
VAL_ 627 TrfcLghtWarnActv_B_Stat 1 "On" 0 "Off" ;
VAL_ 627 TrfcLghtVActv_B_Stat 1 "On" 0 "Off" ;
VAL_ 627 TrfcLghtDir_D_Stat 7 "Faulty" 6 "NoDataExists" 5 "NotUsed" 4 "UtrunActivated" 3 "RightActivated" 2 "LeftActivated" 1 "StraightActivated" 0 "Inactive" ;
VAL_ 627 TrfcLghtDecel_A_Dsply 127 "Faulty" 126 "NoDataExists" ;
VAL_ 627 TrfcLght_V_Mx 255 "Faulty" 254 "NoDataExists" ;
VAL_ 627 TrfcLght_V_Mn 255 "Faulty" 254 "NoDataExists" ;
VAL_ 627 TrfcLght_D_Stat 7 "Faulty" 6 "NoDataExists" 5 "NotUsed" 4 "Four" 3 "Three" 2 "Two" 1 "One" 0 "OffOrNoMatchedLight" ;
VAL_ 630 TrfcLghtRight_T_Actl 255 "Faulty" 254 "NoDataExists" ;
VAL_ 630 TrfcLghtLeftType_D_Stat 3 "Faulty" 2 "DirectionalArrow" 1 "RoundBall" 0 "Inactive" ;
VAL_ 630 TrfcLghtLeftOn_D_Stat 7 "Faulty" 6 "NoDataExists" 5 "NotUsed" 4 "FocusedBlink" 3 "FocusedOn" 2 "Blink" 1 "On" 0 "Inactive" ;
VAL_ 630 TrfcLghtLeftColr_D_Stat 7 "Faulty" 6 "NoDataExists" 5 "NotUsed_2" 4 "NotUsed_1" 3 "Green" 2 "Orange" 1 "Red" 0 "Inactive" ;
VAL_ 630 TrfcLghtLeft_T_Actl 255 "Faulty" 254 "NoDataExists" ;
VAL_ 630 TrfcLghtStrghtType_D_St 3 "Faulty" 2 "DirectionalArrow" 1 "RoundBall" 0 "Inactive" ;
VAL_ 630 TrfcLghtStrghtOn_D_Stat 7 "Faulty" 6 "NoDataExists" 5 "NotUsed" 4 "FocusedBlink" 3 "FocusedOn" 2 "Blink" 1 "On" 0 "Inactive" ;
VAL_ 630 TrfcLghtStrghtColr_D_St 7 "Faulty" 6 "NoDataExists" 5 "NotUsed_2" 4 "NotUsed_1" 3 "Green" 2 "Orange" 1 "Red" 0 "Inactive" ;
VAL_ 630 TrfcLghtStrght_T_Actl 255 "Faulty" 254 "NoDataExists" ;
VAL_ 630 TrfcLghtUturnType_D_St 3 "Faulty" 2 "DirectionalArrow" 1 "RoundBall" 0 "Inactive" ;
VAL_ 630 TrfcLghtUturnOn_D_Stat 7 "Faulty" 6 "NoDataExists" 5 "NotUsed" 4 "FocusedBlink" 3 "FocusedOn" 2 "Blink" 1 "On" 0 "Inactive" ;
VAL_ 630 TrfcLghtUturnColr_D_St 7 "Faulty" 6 "NoDataExists" 5 "NotUsed_2" 4 "NotUsed_1" 3 "Green" 2 "Orange" 1 "Red" 0 "Inactive" ;
VAL_ 630 TrfcLghtUturn_T_Actl 255 "Faulty" 254 "NoDataExists" ;
VAL_ 630 TrfcLghtRightType_D_St 3 "Faulty" 2 "DirectionalArrow" 1 "RoundBall" 0 "Inactive" ;
VAL_ 630 TrfcLghtRightOn_D_Stat 7 "Faulty" 6 "NoDataExists" 5 "NotUsed" 4 "FocusedBlink" 3 "FocusedOn" 2 "Blink" 1 "On" 0 "Inactive" ;
VAL_ 630 TrfcLghtRightColr_D_St 7 "Faulty" 6 "NoDataExists" 5 "NotUsed_2" 4 "NotUsed_1" 3 "Green" 2 "Orange" 1 "Red" 0 "Inactive" ;
VAL_ 650 GridSrvcSbscrb01_D_Stat 3 "NotUsed" 2 "Yes" 1 "No" 0 "Null" ;
VAL_ 650 GridSrvc01_D_Rq 3 "Faulty" 2 "No_Data_Exists" 1 "On" 0 "Off" ;
VAL_ 650 BptTglCnt_No_Rq 15 "Faulty" 14 "NoDataExists" ;
VAL_ 650 BptTgl_D_Rq 3 "Faulty" 2 "NoDataExists" 1 "Request" 0 "NoRequest" ;
VAL_ 650 BptStrtStop_D_RqCld 3 "NotUsed_1" 2 "Start" 1 "Stop" 0 "NoRequest" ;
VAL_ 650 BptMnSoc_L_RqCld 8191 "Faulty" 8190 "NoDataExists" ;
VAL_ 650 BptMde_D_RqCld 7 "NotUsed_4" 6 "NotUsed_3" 5 "NotUsed_2" 4 "NotUsed_1" 3 "Automatic" 2 "Manual" 1 "Off" 0 "Null" ;
VAL_ 650 BptIsol_D_Stat 7 "Faulty" 6 "NoDataExists" 5 "NotUsed_3" 4 "NotUsed_2" 3 "NotUsed_1" 2 "Valid" 1 "Warning" 0 "Invalid" ;
VAL_ 650 BptDly_T_RqCld 63 "Faulty" 62 "NoDataExists" ;
VAL_ 650 BptComm_D_Stat 7 "Faulty" 6 "NoDataExists" 5 "LostCommunicationWithTcu" 4 "LostCommunicationWithEvse" 3 "CommunicationEstablished" 2 "EstablishingCommunication" 1 "EvseNotDetected" 0 "Standby" ;
VAL_ 650 Bpt_D_StatEvse 15 "Faulty" 14 "NoDataExists" 13 "NotUsed_6" 12 "NotUsed_5" 11 "NotUsed_4" 10 "NotUsed_3" 9 "NotUsed_2" 8 "NotUsed_1" 7 "EvseFault" 6 "EvseEnergyTransferActive" 5 "EvsePreChargeReady" 4 "EvseBptReady" 3 "ConnectionTglNotConfirmed" 2 "ConnectionTglConfirmed" 1 "Initialization" 0 "NotReady" ;
VAL_ 663 BptDchrg_Pw_Dsply 1023 "Faulty" 1022 "NoDataExists" ;
VAL_ 663 Bpt_I_Est 1023 "Faulty" 1022 "NoDataExists" ;
VAL_ 663 Bpt_Pw_Allw 65535 "Faulty" 65534 "NoDataExists" ;
VAL_ 663 BptDchrg_T_Rmng 32767 "Faulty" 32766 "NoDataExists" ;
VAL_ 663 BptMnSoc_L_Actl 8191 "Faulty" 8190 "NoDataExists" ;
VAL_ 655 EvseChrgOutHi_U_ActlBpt 1023 "Faulty" 1022 "NoDataExists" ;
VAL_ 655 EvseChrgOutHi_I_ActlBpt 32767 "Faulty" 32766 "NoDataExists" ;
VAL_ 655 EvseDchrg_Pw_Mx 32767 "Faulty" 32766 "NoDataExists" ;
VAL_ 655 EvseDchrg_I_Mx 32767 "Faulty" 32766 "NoDataExists" ;
VAL_ 599 Bpt_D_StatBattTrac 7 "Faulty" 6 "NotUsed_3" 5 "NotUsed_2" 4 "NotUsed_1" 3 "Active" 2 "Ready" 1 "Wait" 0 "NotReady" ;
VAL_ 1227 DcacCabinScnd_I_Actl 65535 "Faulty" 65534 "NoDataExists" ;
VAL_ 1227 DcacOutlet8Scnd_I_Actl 65535 "Faulty" 65534 "NoDataExists" ;
VAL_ 1227 DcacOutlet7Scnd_I_Actl 65535 "Faulty" 65534 "NoDataExists" ;
VAL_ 1227 DcacOutlet6Scnd_I_Actl 65535 "Faulty" 65534 "NoDataExists" ;
VAL_ 1222 DcacOutlet8_I_Actl 65535 "Faulty" 65534 "NoDataExists" ;
VAL_ 1222 DcacOutlet7_I_Actl 65535 "Faulty" 65534 "NoDataExists" ;
VAL_ 1222 DcacOutlet6_I_Actl 65535 "Faulty" 65534 "NoDataExists" ;
VAL_ 1222 DcacCabin_I_Actl 65535 "Faulty" 65534 "NoDataExists" ;
VAL_ 595 DrvIdMde_D_Rq 7 "Faulty" 6 "NotUsed_2" 5 "KeepAwake" 4 "DeleteMid" 3 "ClearAll" 2 "Enroll" 1 "Recognize" 0 "Disable" ;
VAL_ 596 DrvIdMde_D_Stat 7 "Temp_unavailable" 6 "Idle" 5 "DBCorrupt" 4 "DeleteMid" 3 "ClearAll" 2 "Enroll" 1 "Recognize" 0 "Null" ;
VAL_ 596 DrvIdActn_D_Stat 3 "NotUsed" 2 "Success" 1 "Fail" 0 "Null" ;
VAL_ 596 DrvId_D_Stat 7 "NotUsed_3" 6 "NotUsed_2" 5 "NotUsed_1" 4 "FailTimeout" 3 "FailWeakMatch" 2 "OkNoMatch" 1 "OkMatched" 0 "Null" ;
VAL_ 596 DrvExpression_D_Stat 15 "NotUsed_5" 14 "NotUsed_4" 13 "NotUsed_3" 12 "FailMultipleMatches" 11 "FailNoSlot" 10 "HasRegister" 9 "ConstraintsOk" 8 "NotAFace" 7 "PoorTrackingQuality" 6 "EyesNotVisible" 5 "FaceBlockage" 4 "MouthOpen" 3 "OutsidePoseLimits" 2 "TooManyFaces" 1 "FaceNotInView" 0 "Null" ;
VAL_ 612 SelDrvMdeSwtch_D_Stat6 3 "Faulty" 2 "SwitchState2" 1 "SwitchState1" 0 "NotPressed" ;
VAL_ 1015 SelDrvMdeSwtch_D_Stat7 3 "Faulty" 2 "SwitchState2" 1 "SwitchState1" 0 "NotPressed" ;
VAL_ 1015 E_Frt_Btn_Status_2nd 63 "NotUsed_10" 62 "NotUsed_9" 61 "NotUsed_8" 60 "NotUsed_7" 59 "NotUsed_6" 58 "NotUsed_5" 57 "NotUsed_4" 56 "NotUsed_3" 55 "NotUsed_2" 54 "NotUsed_1" 53 "RHS_Cld_Seat3_Pressed" 52 "RHS_Cld_Seat2_Pressed" 51 "RHS_Cld_Seat1_Pressed" 50 "LHS_Cld_Seat3_Pressed" 49 "LHS_Cld_Seat2_Pressed" 48 "LHS_Cld_Seat1_Pressed" 47 "RHS_Auto_Seat_Pressed" 46 "RHS_Htd_Seat3_Pressed" 45 "RHS_Htd_Seat2_Pressed" 44 "RHS_Htd_Seat1_Pressed" 43 "RHS_Seat_Off_Pressed" 42 "LHS_Auto_Seat_Pressed" 41 "LHS_Htd_Seat3_Pressed" 40 "LHS_Htd_Seat2_Pressed" 39 "LHS_Htd_Seat1_Pressed" 38 "LHS_Seat_Off_Pressed" 37 "DrvrFcsdMde_Pressed" 36 "MdeMnu_Pressed" 35 "AAR_Pressed" 34 "Heat_Pressed" 33 "RearMnu_Pressed" 32 "FrontMnu_Pressed" 31 "Defrost_Pressed" 30 "Htg_Strg_Whl_Pressed" 29 "RHS_Cld_Seat_Pressed" 28 "LHS_Cld_Seat_Pressed" 27 "RHS_Htd_Seat_Pressed" 26 "LHS_Htd_Seat_Pressed" 25 "Max_Defrost_Pressed" 24 "My_Temp_Pressed" 23 "Front_Power_Pressed" 22 "Rear_Defrost_Pressed" 21 "Pnl_Flr_Ws_Pressed" 20 "Pnl_Ws_Pressed" 19 "Windscreen_Pressed" 18 "Htd_Frt_Wsh_Pressed" 17 "Auto_Recirc_Pressed" 16 "Outside_Pressed" 15 "Recirc_Pressed" 14 "Max_AC_Pressed" 13 "Auto_Pressed" 12 "Blwr_Dec_Pressed" 11 "Blwr_Inc_Pressed" 10 "RHS_Temp_Dec_Pressed" 9 "RHS_Temp_Inc_Pressed" 8 "LHS_Temp_Dec_Pressed" 7 "LHS_Temp_Inc_Pressed" 6 "Dual_Pressed" 5 "AC_Pressed" 4 "Floor_Ws_Pressed" 3 "Floor_Pressed" 2 "Panel_Floor_Pressed" 1 "Panel_Pressed" 0 "None_Pressed" ;
VAL_ 1015 E_Frt_Btn_Status_1st 63 "NotUsed_10" 62 "NotUsed_9" 61 "NotUsed_8" 60 "NotUsed_7" 59 "NotUsed_6" 58 "NotUsed_5" 57 "NotUsed_4" 56 "NotUsed_3" 55 "NotUsed_2" 54 "NotUsed_1" 53 "RHS_Cld_Seat3_Pressed" 52 "RHS_Cld_Seat2_Pressed" 51 "RHS_Cld_Seat1_Pressed" 50 "LHS_Cld_Seat3_Pressed" 49 "LHS_Cld_Seat2_Pressed" 48 "LHS_Cld_Seat1_Pressed" 47 "RHS_Auto_Seat_Pressed" 46 "RHS_Htd_Seat3_Pressed" 45 "RHS_Htd_Seat2_Pressed" 44 "RHS_Htd_Seat1_Pressed" 43 "RHS_Seat_Off_Pressed" 42 "LHS_Auto_Seat_Pressed" 41 "LHS_Htd_Seat3_Pressed" 40 "LHS_Htd_Seat2_Pressed" 39 "LHS_Htd_Seat1_Pressed" 38 "LHS_Seat_Off_Pressed" 37 "DrvrFcsdMde_Pressed" 36 "MdeMnu_Pressed" 35 "AAR_Pressed" 34 "Heat_Pressed" 33 "RearMnu_Pressed" 32 "FrontMnu_Pressed" 31 "Defrost_Pressed" 30 "Htg_Strg_Whl_Pressed" 29 "RHS_Cld_Seat_Pressed" 28 "LHS_Cld_Seat_Pressed" 27 "RHS_Htd_Seat_Pressed" 26 "LHS_Htd_Seat_Pressed" 25 "Max_Defrost_Pressed" 24 "My_Temp_Pressed" 23 "Front_Power_Pressed" 22 "Rear_Defrost_Pressed" 21 "Pnl_Flr_Ws_Pressed" 20 "Pnl_Ws_Pressed" 19 "Windscreen_Pressed" 18 "Htd_Frt_Wsh_Pressed" 17 "Auto_Recirc_Pressed" 16 "Outside_Pressed" 15 "Recirc_Pressed" 14 "Max_AC_Pressed" 13 "Auto_Pressed" 12 "Blwr_Dec_Pressed" 11 "Blwr_Inc_Pressed" 10 "RHS_Temp_Dec_Pressed" 9 "RHS_Temp_Inc_Pressed" 8 "LHS_Temp_Dec_Pressed" 7 "LHS_Temp_Inc_Pressed" 6 "Dual_Pressed" 5 "AC_Pressed" 4 "Floor_Ws_Pressed" 3 "Floor_Pressed" 2 "Panel_Floor_Pressed" 1 "Panel_Pressed" 0 "None_Pressed" ;
VAL_ 986 OnbSndActv_D_Rq 3 "NotUsed" 2 "Activate" 1 "Deactivate" 0 "Null" ;
VAL_ 986 PsngrLoad_M_Rq 1023 "Faulty" 1022 "NoDataExists" ;
VAL_ 986 Trlr_M_Rq 2047 "Faulty" 2046 "NoDataExists" ;
VAL_ 986 VehFalr_D_Rq 7 "NotUsed_3" 6 "NotUsed_2" 5 "NotUsed_1" 4 "NotComplete" 3 "Complete" 2 "RequestSecondMeasurement" 1 "RequestFirstMeasurement" 0 "NoRequest" ;
VAL_ 986 TailLghtLoadMde_D_Rq 7 "NotUsed_3" 6 "NotUsed_2" 5 "NotUsed_1" 4 "DeactivateAll" 3 "ActivateFalrMode" 2 "ActivateHitchLoadMode" 1 "ActivatePayloadMode" 0 "NoCommand" ;
VAL_ 986 VehPayloadTare_D_Rq 1 "Request" 0 "NoRequest" ;
VAL_ 986 VehPayloadScrn_D_Rq 7 "CheckLoadScreenActive" 6 "WeightCarryScreenActive" 5 "GooseneckScreenActive" 4 "FifthWheelScreenActive" 3 "WeightDistScreenActive" 2 "AddMassEstScreenActive" 1 "PayloadEstScreenActive" 0 "ScaleScreenNotActive" ;
VAL_ 986 LightAmbIntsty_No_Rq 0 "Off" ;
VAL_ 571 VehFalr_Pc_Est 127 "Faulty" 126 "NoDataExists" ;
VAL_ 571 TrlrTngLoad_Pc_Est 127 "Faulty" 126 "NoDataExists" ;
VAL_ 571 TrlrTngLoad_M_Est 2047 "Faulty" 2046 "NoDataExists" ;
VAL_ 571 VehPayloadAdd_M_Est 2047 "Faulty" 2046 "NoDataExists" ;
VAL_ 571 VehPayload_Pc_Est 127 "Faulty" 126 "NoDataExists" ;
VAL_ 571 VehPayload_M_Est 1023 "Faulty" 1022 "NoDataExists" ;
VAL_ 537 BrkVacPmpDmd_D_Stat 3 "EvpNotConfigured" 2 "EcmEvpDriverDemandOn" 1 "AbsEvpDriverOn" 0 "NoEvpDemand" ;
VAL_ 537 BrkBstrAvail_D_Stat 3 "Full" 2 "Partial" 1 "NotConfigured" 0 "Failed" ;
VAL_ 1176 BattTracCell45_U_Actl 4095 "Fault" 4094 "NoDataExists" ;
VAL_ 1176 BattTracCell44_U_Actl 4095 "Fault" 4094 "NoDataExists" ;
VAL_ 1176 BattTracCell43_U_Actl 4095 "Fault" 4094 "NoDataExists" ;
VAL_ 1176 BattTracCell42_U_Actl 4095 "Fault" 4094 "NoDataExists" ;
VAL_ 1176 BattTracCell41_U_Actl 4095 "Fault" 4094 "NoDataExists" ;
VAL_ 1175 BattTracCell40_U_Actl 4095 "Fault" 4094 "NoDataExists" ;
VAL_ 1175 BattTracCell39_U_Actl 4095 "Fault" 4094 "NoDataExists" ;
VAL_ 1175 BattTracCell38_U_Actl 4095 "Fault" 4094 "NoDataExists" ;
VAL_ 1175 BattTracCell37_U_Actl 4095 "Fault" 4094 "NoDataExists" ;
VAL_ 1175 BattTracCell36_U_Actl 4095 "Fault" 4094 "NoDataExists" ;
VAL_ 1174 BattTracCell35_U_Actl 4095 "Fault" 4094 "NoDataExists" ;
VAL_ 1174 BattTracCell34_U_Actl 4095 "Fault" 4094 "NoDataExists" ;
VAL_ 1174 BattTracCell33_U_Actl 4095 "Fault" 4094 "NoDataExists" ;
VAL_ 1174 BattTracCell32_U_Actl 4095 "Fault" 4094 "NoDataExists" ;
VAL_ 1174 BattTracCell31_U_Actl 4095 "Fault" 4094 "NoDataExists" ;
VAL_ 1173 BattTracCell30_U_Actl 4095 "Fault" 4094 "NoDataExists" ;
VAL_ 1173 BattTracCell29_U_Actl 4095 "Fault" 4094 "NoDataExists" ;
VAL_ 1173 BattTracCell28_U_Actl 4095 "Fault" 4094 "NoDataExists" ;
VAL_ 1173 BattTracCell27_U_Actl 4095 "Fault" 4094 "NoDataExists" ;
VAL_ 1173 BattTracCell26_U_Actl 4095 "Fault" 4094 "NoDataExists" ;
VAL_ 1172 BattTracCell25_U_Actl 4095 "Fault" 4094 "NoDataExists" ;
VAL_ 1172 BattTracCell24_U_Actl 4095 "Fault" 4094 "NoDataExists" ;
VAL_ 1172 BattTracCell23_U_Actl 4095 "Fault" 4094 "NoDataExists" ;
VAL_ 1172 BattTracCell22_U_Actl 4095 "Fault" 4094 "NoDataExists" ;
VAL_ 1172 BattTracCell21_U_Actl 4095 "Fault" 4094 "NoDataExists" ;
VAL_ 1171 BattTracCell20_U_Actl 4095 "Fault" 4094 "NoDataExists" ;
VAL_ 1171 BattTracCell19_U_Actl 4095 "Fault" 4094 "NoDataExists" ;
VAL_ 1171 BattTracCell18_U_Actl 4095 "Fault" 4094 "NoDataExists" ;
VAL_ 1171 BattTracCell17_U_Actl 4095 "Fault" 4094 "NoDataExists" ;
VAL_ 1171 BattTracCell16_U_Actl 4095 "Fault" 4094 "NoDataExists" ;
VAL_ 1170 BattTracCell15_U_Actl 4095 "Fault" 4094 "NoDataExists" ;
VAL_ 1170 BattTracCell14_U_Actl 4095 "Fault" 4094 "NoDataExists" ;
VAL_ 1170 BattTracCell13_U_Actl 4095 "Fault" 4094 "NoDataExists" ;
VAL_ 1170 BattTracCell12_U_Actl 4095 "Fault" 4094 "NoDataExists" ;
VAL_ 1170 BattTracCell11_U_Actl 4095 "Fault" 4094 "NoDataExists" ;
VAL_ 1191 BattTracTe14_Te_Actl 255 "Faulty" 254 "NoDataExists" ;
VAL_ 1191 BattTracTe19_Te_Actl 255 "Faulty" 254 "NoDataExists" ;
VAL_ 1191 BattTracTe18_Te_Actl 255 "Faulty" 254 "NoDataExists" ;
VAL_ 1191 BattTracTe17_Te_Actl 255 "Faulty" 254 "NoDataExists" ;
VAL_ 1191 BattTracTe16_Te_Actl 255 "Faulty" 254 "NoDataExists" ;
VAL_ 1191 BattTracTe15_Te_Actl 255 "Faulty" 254 "NoDataExists" ;
VAL_ 1190 BattTracUMxArry_No_Actl 31 "Faulty" ;
VAL_ 1190 BattTracCellUMx_No_Actl 255 "Faulty" 254 "NoDataExists" ;
VAL_ 1190 BattChrgUMx_B_Falt 1 "Yes" 0 "No" ;
VAL_ 1190 BattTracCellUMn_No_Actl 255 "Faulty" 254 "NoDataExists" ;
VAL_ 1190 BattTracCellCnt_No_Actl 255 "Faulty" 254 "NoDataExists" ;
VAL_ 1190 BattChrgIsltn_B_Falt 1 "Yes" 0 "No" ;
VAL_ 1190 BattTracCellDiff_B_Falt 1 "Yes" 0 "No" ;
VAL_ 1190 BattChrgSocMx_B_Falt 1 "Yes" 0 "No" ;
VAL_ 1190 BattChrgSocMn_B_Falt 1 "Yes" 0 "No" ;
VAL_ 1190 BattChrgSocErrtc_B_Falt 1 "Yes" 0 "No" ;
VAL_ 1190 BattTracUMx_B_Falt 1 "Yes" 0 "No" ;
VAL_ 1190 BattTracUMn_B_Falt 1 "Yes" 0 "No" ;
VAL_ 1190 BattTracTeMx_No_Actl 255 "Faulty" 254 "NoDataExists" ;
VAL_ 1190 BattTracTeMx_B_Falt 1 "Yes" 0 "No" ;
VAL_ 1190 BattTracTeMn_No_Actl 255 "Faulty" 254 "NoDataExists" ;
VAL_ 1190 BattTracTeDelta_B_Falt 1 "Yes" 0 "No" ;
VAL_ 1190 BattTracTeCnt_No_Actl 255 "Faulty" 254 "NoDataExists" ;
VAL_ 1190 BattTracSoftware_B_Falt 1 "Yes" 0 "No" ;
VAL_ 1188 BattTracTe13_Te_Actl 255 "Faulty" 254 "NoDataExists" ;
VAL_ 1188 BattTracTe12_Te_Actl 255 "Faulty" 254 "NoDataExists" ;
VAL_ 1188 BattTracTe11_Te_Actl 255 "Faulty" 254 "NoDataExists" ;
VAL_ 1188 BattTracTe10_Te_Actl 255 "Faulty" 254 "NoDataExists" ;
VAL_ 1188 BattTracTe09_Te_Actl 255 "Faulty" 254 "NoDataExists" ;
VAL_ 1188 BattTracTe08_Te_Actl 255 "Faulty" 254 "NoDataExists" ;
VAL_ 1188 BattTracTe07_Te_Actl 255 "Faulty" 254 "NoDataExists" ;
VAL_ 1187 BattTracTe06_Te_Actl 255 "Faulty" 254 "NoDataExists" ;
VAL_ 1187 BattTracTe05_Te_Actl 255 "Faulty" 254 "NoDataExists" ;
VAL_ 1187 BattTracTe04_Te_Actl 255 "Faulty" 254 "NoDataExists" ;
VAL_ 1187 BattTracTe03_Te_Actl 255 "Faulty" 254 "NoDataExists" ;
VAL_ 1187 BattTracTe02_Te_Actl 255 "Faulty" 254 "NoDataExists" ;
VAL_ 1187 BattTracTe01_Te_Actl 255 "Faulty" 254 "NoDataExists" ;
VAL_ 1187 BattTracCell96_U_Actl 4095 "Fault" 4094 "NoDataExists" ;
VAL_ 1169 BattTracCell10_U_Actl 4095 "Fault" 4094 "NoDataExists" ;
VAL_ 1169 BattTracCell09_U_Actl 4095 "Fault" 4094 "NoDataExists" ;
VAL_ 1169 BattTracCell08_U_Actl 4095 "Fault" 4094 "NoDataExists" ;
VAL_ 1169 BattTracCell07_U_Actl 4095 "Fault" 4094 "NoDataExists" ;
VAL_ 1169 BattTracCell06_U_Actl 4095 "Fault" 4094 "NoDataExists" ;
VAL_ 1192 BattTracCell95_U_Actl 4095 "Fault" 4094 "NoDataExists" ;
VAL_ 1192 BattTracCell94_U_Actl 4095 "Fault" 4094 "NoDataExists" ;
VAL_ 1192 BattTracCell93_U_Actl 4095 "Fault" 4094 "NoDataExists" ;
VAL_ 1192 BattTracCell92_U_Actl 4095 "Fault" 4094 "NoDataExists" ;
VAL_ 1192 BattTracCell91_U_Actl 4095 "Fault" 4094 "NoDataExists" ;
VAL_ 1185 BattTracCell90_U_Actl 4095 "Fault" 4094 "NoDataExists" ;
VAL_ 1185 BattTracCell89_U_Actl 4095 "Fault" 4094 "NoDataExists" ;
VAL_ 1185 BattTracCell88_U_Actl 4095 "Fault" 4094 "NoDataExists" ;
VAL_ 1185 BattTracCell87_U_Actl 4095 "Fault" 4094 "NoDataExists" ;
VAL_ 1185 BattTracCell86_U_Actl 4095 "Fault" 4094 "NoDataExists" ;
VAL_ 1184 BattTracCell85_U_Actl 4095 "Fault" 4094 "NoDataExists" ;
VAL_ 1184 BattTracCell84_U_Actl 4095 "Fault" 4094 "NoDataExists" ;
VAL_ 1184 BattTracCell83_U_Actl 4095 "Fault" 4094 "NoDataExists" ;
VAL_ 1184 BattTracCell82_U_Actl 4095 "Fault" 4094 "NoDataExists" ;
VAL_ 1184 BattTracCell81_U_Actl 4095 "Fault" 4094 "NoDataExists" ;
VAL_ 1183 BattTracCell80_U_Actl 4095 "Fault" 4094 "NoDataExists" ;
VAL_ 1183 BattTracCell79_U_Actl 4095 "Fault" 4094 "NoDataExists" ;
VAL_ 1183 BattTracCell78_U_Actl 4095 "Fault" 4094 "NoDataExists" ;
VAL_ 1183 BattTracCell77_U_Actl 4095 "Fault" 4094 "NoDataExists" ;
VAL_ 1183 BattTracCell76_U_Actl 4095 "Fault" 4094 "NoDataExists" ;
VAL_ 1182 BattTracCell75_U_Actl 4095 "Fault" 4094 "NoDataExists" ;
VAL_ 1182 BattTracCell74_U_Actl 4095 "Fault" 4094 "NoDataExists" ;
VAL_ 1182 BattTracCell73_U_Actl 4095 "Fault" 4094 "NoDataExists" ;
VAL_ 1182 BattTracCell72_U_Actl 4095 "Fault" 4094 "NoDataExists" ;
VAL_ 1182 BattTracCell71_U_Actl 4095 "Fault" 4094 "NoDataExists" ;
VAL_ 1181 BattTracCell70_U_Actl 4095 "Fault" 4094 "NoDataExists" ;
VAL_ 1181 BattTracCell69_U_Actl 4095 "Fault" 4094 "NoDataExists" ;
VAL_ 1181 BattTracCell68_U_Actl 4095 "Fault" 4094 "NoDataExists" ;
VAL_ 1181 BattTracCell67_U_Actl 4095 "Fault" 4094 "NoDataExists" ;
VAL_ 1181 BattTracCell66_U_Actl 4095 "Fault" 4094 "NoDataExists" ;
VAL_ 1180 BattTracCell65_U_Actl 4095 "Fault" 4094 "NoDataExists" ;
VAL_ 1180 BattTracCell64_U_Actl 4095 "Fault" 4094 "NoDataExists" ;
VAL_ 1180 BattTracCell63_U_Actl 4095 "Fault" 4094 "NoDataExists" ;
VAL_ 1180 BattTracCell62_U_Actl 4095 "Fault" 4094 "NoDataExists" ;
VAL_ 1180 BattTracCell61_U_Actl 4095 "Fault" 4094 "NoDataExists" ;
VAL_ 1179 BattTracCell60_U_Actl 4095 "Fault" 4094 "NoDataExists" ;
VAL_ 1179 BattTracCell59_U_Actl 4095 "Fault" 4094 "NoDataExists" ;
VAL_ 1179 BattTracCell58_U_Actl 4095 "Fault" 4094 "NoDataExists" ;
VAL_ 1179 BattTracCell57_U_Actl 4095 "Fault" 4094 "NoDataExists" ;
VAL_ 1179 BattTracCell56_U_Actl 4095 "Fault" 4094 "NoDataExists" ;
VAL_ 1178 BattTracCell55_U_Actl 4095 "Fault" 4094 "NoDataExists" ;
VAL_ 1178 BattTracCell54_U_Actl 4095 "Fault" 4094 "NoDataExists" ;
VAL_ 1178 BattTracCell53_U_Actl 4095 "Fault" 4094 "NoDataExists" ;
VAL_ 1178 BattTracCell52_U_Actl 4095 "Fault" 4094 "NoDataExists" ;
VAL_ 1178 BattTracCell51_U_Actl 4095 "Fault" 4094 "NoDataExists" ;
VAL_ 1177 BattTracCell50_U_Actl 4095 "Fault" 4094 "NoDataExists" ;
VAL_ 1177 BattTracCell49_U_Actl 4095 "Fault" 4094 "NoDataExists" ;
VAL_ 1177 BattTracCell48_U_Actl 4095 "Fault" 4094 "NoDataExists" ;
VAL_ 1177 BattTracCell47_U_Actl 4095 "Fault" 4094 "NoDataExists" ;
VAL_ 1177 BattTracCell46_U_Actl 4095 "Fault" 4094 "NoDataExists" ;
VAL_ 1168 BattTracCell05_U_Actl 4095 "Fault" 4094 "NoDataExists" ;
VAL_ 1168 BattTracCell04_U_Actl 4095 "Fault" 4094 "NoDataExists" ;
VAL_ 1168 BattTracCell03_U_Actl 4095 "Fault" 4094 "NoDataExists" ;
VAL_ 1168 BattTracCell02_U_Actl 4095 "Fault" 4094 "NoDataExists" ;
VAL_ 1168 BattTracCell01_U_Actl 4095 "Fault" 4094 "NoDataExists" ;
VAL_ 1245 RearDiffLckLamp_D_Cstm 3 "Not_Used" 2 "Flash" 1 "On" 0 "Off" ;
VAL_ 1245 FrontDiffLckLamp_D_Cstm 3 "Fast_Flash" 2 "Slow_Flash" 1 "On" 0 "Off" ;
VAL_ 1245 AwdMdeCstm_D_RqDrv 7 "Faulty" 6 "NotUsed_3" 5 "NotUsed_2" 4 "NotUsed_1" 3 "FourByFourLow" 2 "FourByFourHigh" 1 "FourByFourAuto" 0 "FourByTwo" ;
VAL_ 1245 SelDrvMdeAwd2_D_Cstm 31 "Faulty" 30 "NotUsed_17" 29 "NotUsed_16" 28 "NotUsed_15" 27 "NotUsed_14" 26 "NotUsed_13" 25 "NotUsed_12" 24 "NotUsed_11" 23 "NotUsed_10" 22 "NotUsed_9" 21 "NotUsed_8" 20 "CustomMode" 19 "OnePedalDrive" 18 "DragMode" 17 "EvLaterChargeMode" 16 "EvNowMode" 15 "TrackMode" 14 "RoughRoadMode" 13 "NotAvailable" 12 "HighSpeedDesertMode_Baja" 11 "SportAdaptiveMode" 10 "RockCrawlMode" 9 "MudRutsMode" 8 "SandMode" 7 "EconomyMode" 6 "GrassGravelSnow" 5 "TowHaulMode" 4 "SportMode" 3 "Normal_4L" 2 "Normal_4A" 1 "Normal_2H" 0 "NormalMode" ;
VAL_ 1242 SelDrvMdeCstmPt_D_Rq 31 "Faulty" 30 "NotUsed15" 29 "NotUsed14" 28 "NotUsed13" 27 "NotUsed12" 26 "NotUsed11" 25 "NotUsed10" 24 "NotUsed9" 23 "NotUsed8" 22 "NotUsed7" 21 "CustomMode" 20 "TrackMode" 19 "OnePedalDrive" 18 "EvLaterChargerMode" 17 "EvNowMode" 16 "DragMode" 15 "HighSpeedDesertMode_Baja" 14 "SportAdaptiveMode" 13 "NotAvailable_13" 12 "NotAvailable_12" 11 "NotAvailable_11" 10 "NotAvailable_10" 9 "RockCrawlMode" 8 "MudRutsMode" 7 "SandMode" 6 "EconomyMode" 5 "GrassGravelSnow" 4 "NotAvailable_04" 3 "TowHaulMode" 2 "NotAvailable_02" 1 "SportMode" 0 "NormalMode" ;
VAL_ 1242 EngExhMdeQuietCstm_D_Rq 7 "Faulty" 6 "NotUsed_2" 5 "NotUsed_1" 4 "Track" 3 "Sport" 2 "Normal" 1 "Stealth" 0 "Null" ;
VAL_ 1242 StopStrtCstm_D_Rq 3 "Faulty" 2 "On" 1 "Off" 0 "NotAvailable" ;
VAL_ 1116 TrlrAidSetup_D2_Rq 15 "NotUsed_9" 14 "NotUsed_8" 13 "NotUsed_7" 12 "NotUsed_6" 11 "NotUsed_5" 10 "NotUsed_4" 9 "NotUsed_3" 8 "NotUsed_2" 7 "NotUsed_1" 6 "CompleteSetup" 5 "ReturnToSetup" 4 "StickerNotCircled" 3 "ConfirmSetup" 2 "EndSetup" 1 "BeginSetup" 0 "Inactive" ;
VAL_ 1116 TrlrAidEnbl_D2_Rq 7 "NotUsed_4" 6 "NotUsed_3" 5 "NotUsed_2" 4 "NotUsed_1" 3 "Deactivate" 2 "ActivateTrg" 1 "ActivateTba" 0 "Inactive" ;
VAL_ 1116 TlightTest_D_Mnu 3 "TestEndAcknowledge" 2 "StartTest" 1 "StopTest" 0 "Null" ;
VAL_ 1116 TrlrRvrseCancl_B_Rq 1 "Cancel" 0 "Null" ;
VAL_ 1116 TrlrIdType_D_Stat 3 "Gooseneck" 2 "FifthWheel" 1 "Conventional" 0 "Null" ;
VAL_ 1116 TrlrAnOffstDir_D_Mem 3 "NotUSed" 2 "Right" 1 "Left_or_Center" 0 "Null" ;
VAL_ 954 ExtLghtFront_D_RqBody 3 "NotUsed" 2 "On" 1 "Off" 0 "Null" ;
VAL_ 954 VehWlcmFrwlMde_D_Stat 7 "IlluminatedExit" 6 "CourtesyLightingDelayExt" 5 "CourtesyLightingExtended" 4 "CourtesyLightingDelayAll" 3 "CourtesyLightingAll" 2 "IlluminatedEntry" 1 "Approach" 0 "Null" ;
VAL_ 954 CrtsyLghtRear_D_Stat 3 "NotUsed" 2 "Automatic" 1 "Manual" 0 "Null" ;
VAL_ 954 TrlrHitchLamp_D2_Stat 3 "NotUsed" 2 "Automatic" 1 "Manual" 0 "Null" ;
VAL_ 954 ChildLckMaint_D_Stat 3 "NotUsed" 2 "Overruled" 1 "On" 0 "Off" ;
VAL_ 954 PosLghtFl_D_Stat 3 "Faulty" 2 "Outage" 1 "On" 0 "Off" ;
VAL_ 954 PosLghtFr_D_Stat 3 "Faulty" 2 "Outage" 1 "On" 0 "Off" ;
VAL_ 954 PudSptLghtRight_D_Rq 3 "NotUsed" 2 "On" 1 "Off" 0 "Null" ;
VAL_ 954 PudSptLghtLeft_D_Rq 3 "NotUsed" 2 "On" 1 "Off" 0 "Null" ;
VAL_ 954 ExtLghtRight_D_Stat 3 "NotUsed" 2 "On" 1 "Off" 0 "Null" ;
VAL_ 954 ExtLghtRear_D_Stat 3 "NotUsed" 2 "On" 1 "Off" 0 "Null" ;
VAL_ 954 ExtLghtLeft_D_Stat 3 "NotUsed" 2 "On" 1 "Off" 0 "Null" ;
VAL_ 954 ExtLghtFront_D_Stat 3 "NotUsed" 2 "On" 1 "Off" 0 "Null" ;
VAL_ 954 CargoLght_D_Stat 3 "NotUsed" 2 "Automatic" 1 "Manual" 0 "Null" ;
VAL_ 954 TlghtTestLght_D_Stat 7 "Error" 6 "AllOff" 5 "TestingReverseLights" 4 "TestingBrakeLights" 3 "TestingLeftTurnSignal" 2 "TestingRightTurnSignal" 1 "ParkingLightsIlluminated" 0 "Null" ;
VAL_ 954 LghtAmbDrvMde_B_Stat 1 "Automatic" 0 "Manual" ;
VAL_ 954 KeylessIdl_B_Stat 1 "Pressed" 0 "Not_Pressed" ;
VAL_ 954 PwRnngBoardPoll_D_Stat 3 "NotUsed" 2 "PkPresent" 1 "PkNotPresent" 0 "NotPolling" ;
VAL_ 954 PoliceDmngLvl_D_Stat 7 "NotUsed" 6 "Off_Night" 5 "Off_Day" 4 "Low1Night" 3 "Low1Day" 2 "Inactive" 1 "Decommissioned" 0 "Null" ;
VAL_ 954 TrlrHitchLamp_D_Stat 1 "On" 0 "Off" ;
VAL_ 954 LicPlateLght_B_Stat 1 "On" 0 "Off" ;
VAL_ 954 TrukBedLght_B_Stat 1 "On" 0 "Off" ;
VAL_ 954 VehWlcmFrwl_D_Stat 3 "RunStart" 2 "Farewell" 1 "Welcome" 0 "Null" ;
VAL_ 954 TlghtTestPrecnd_D_Stat 7 "Error" 6 "NotStationary" 5 "InteractionPresent" 4 "PreconditionsPassed" 3 "BattSocLessThan75Percent" 2 "TailLightsOn" 1 "IgnitionNotOn" 0 "Null" ;
VAL_ 954 TlghtTest_D_Stat 3 "InProgress" 2 "Ended" 1 "Completed" 0 "Null" ;
VAL_ 954 ExtLghtAlrt_B_Rq 1 "Yes" 0 "No" ;
VAL_ 954 ExtLght_D_Falt 3 "Error" 2 "NoStationary" 1 "StartEngine" 0 "Null" ;
VAL_ 874 AirCondCluOpen_D_Falt 3 "NotUsed" 2 "Pass" 1 "Fail" 0 "Not_Diagnose_Yet" ;
VAL_ 874 AirCondCluLife_D_Falt 3 "NotUsed" 2 "Pass" 1 "Fail" 0 "Not_Diagnose_Yet" ;
VAL_ 874 AirCondCluGnd_D_Falt 3 "NotUsed" 2 "Pass" 1 "Fail" 0 "Not_Diagnose_Yet" ;
VAL_ 874 AirCondClu_D_Stat 7 "NotUsed" 6 "FetLifeLimitReached" 5 "FetOpenCircuit" 4 "FetOutputShortToPower" 3 "FetOutputShortToGround" 2 "FetNotControlled" 1 "OnPowerToLoad" 0 "OffNoPowerToLoad" ;
VAL_ 874 AirCondCluBatt_D_Falt 3 "NotUsed" 2 "Pass" 1 "Fail" 0 "Not_Diagnose_Yet" ;
VAL_ 874 BattTracShrtGrnd_D_Falt 3 "NotUsed" 2 "Pass" 1 "Fail" 0 "Not_Diagnose_Yet" ;
VAL_ 874 BattTracShrtBatt_D_Falt 3 "NotUsed" 2 "Pass" 1 "Fail" 0 "Not_Diagnose_Yet" ;
VAL_ 874 BattTracOpnCirct_D_Falt 3 "NotUsed" 2 "Pass" 1 "Fail" 0 "Not_Diagnose_Yet" ;
VAL_ 874 BattTracLifeLim_D_Falt 3 "NotUsed" 2 "Pass" 1 "Fail" 0 "Not_Diagnose_Yet" ;
VAL_ 874 BattChlrShrtGrnd_D_Falt 3 "NotUsed" 2 "Pass" 1 "Fail" 0 "Not_Diagnose_Yet" ;
VAL_ 874 BattChlrShrtBatt_D_Falt 3 "NotUsed" 2 "Pass" 1 "Fail" 0 "Not_Diagnose_Yet" ;
VAL_ 874 BattChlrOpnCirct_D_Falt 3 "NotUsed" 2 "Pass" 1 "Fail" 0 "Not_Diagnose_Yet" ;
VAL_ 874 BattChlrLifeLim_D_Falt 3 "NotUsed" 2 "Pass" 1 "Fail" 0 "Not_Diagnose_Yet" ;
VAL_ 874 BattTracLow_D_Falt 3 "NotUsed" 2 "Pass" 1 "Fail" 0 "Not_Diagnose_Yet" ;
VAL_ 551 PrkBrkPerfMnuOn_D_Stat 3 "Faulty" 2 "NotUsed" 1 "On" 0 "Off" ;
VAL_ 551 PrkBrkPerfButtn_D_Stat 3 "Faulty" 2 "NotUsed" 1 "Pressed" 0 "Not_Pressed" ;
VAL_ 551 TjaLaneBiasEnbl_D_RqMnu 3 "NotUsed" 2 "Enabled" 1 "Disabled" 0 "Null" ;
VAL_ 551 VehPerfDemo_B_RqDrv 1 "On" 0 "Off" ;
VAL_ 551 Rba_D_Rq 3 "NotUsed" 2 "On" 1 "Off" 0 "Null" ;
VAL_ 551 EmPrflNo_D_Rq 7 "NotUsed_3" 6 "NotUsed_2" 5 "NotUsed_1" 4 "Pers4" 3 "Pers3" 2 "Pers2" 1 "Pers1" 0 "Null" ;
VAL_ 551 EmPrflButtnAssoc_D_Rq 3 "NotUsed" 2 "ExitButtonAssociation" 1 "EnterButtonAssociation" 0 "Null" ;
VAL_ 551 EmPrflKeyAssoc_D_Rq 7 "NotUsed_3" 6 "DisassociatePhone" 5 "EnterPhoneAssociation" 4 "OverwriteKey" 3 "DisassociateKey" 2 "ExitKeyAssociation" 1 "EnterKeyAssociation" 0 "Null" ;
VAL_ 551 Em_D_Stat 3 "NotSupported" 2 "ProfilesOff" 1 "ProfilesOn" 0 "Null" ;
VAL_ 551 ChrgOvrdExitScrn_D_Rq 3 "NotUsed_1" 2 "Request_override" 1 "Do_not_request_override" 0 "Inactive" ;
VAL_ 551 PrcondEdit_D_RqMnu 7 "NotUsed_3" 6 "NotUsed_2" 5 "NotUsed_1" 4 "High" 3 "Medium" 2 "Low" 1 "Off" 0 "Null" ;
VAL_ 551 ChrgToPcEdit_Pc_RqMnu 127 "Faulty" 126 "NoDataExists" ;
VAL_ 551 EcoIdl_D_Rq 3 "NotUsed" 2 "Enabled" 1 "Disabled" 0 "Null" ;
VAL_ 551 PmCabnLvl_D_Stat 7 "NotUsed_1" 6 "Level_6_Worst" 5 "Level_5" 4 "Level_4" 3 "Level_3" 2 "Level_2" 1 "Level_1_Best" 0 "NotKnown" ;
VAL_ 551 PmCabn_D_Stat 3 "FilteringComplete" 2 "FilteringOn" 1 "FilteringOff" 0 "NotKnown" ;
VAL_ 551 PwRnngBoardSwtch_D_Rq 3 "NotUsed" 2 "DeployUnlocked" 1 "AlwaysActive" 0 "Inactive" ;
VAL_ 551 PwRnngBoardMde_D_Rq 0 "Inactive" 1 "Off" 2 "Out" 3 "Auto" ;
VAL_ 551 PwRnngBoardT_D_Rq 3 "NotUsed" 2 "Timer2" 1 "Timer1" 0 "Inactive" ;
VAL_ 551 OneTEditActv_B_RqMnu 1 "Yes" 0 "No" ;
VAL_ 551 Cntr_Plg_Mode_Cmd 1 "Enable" 0 "Disable" ;
VAL_ 551 BattTracLoThres_D_Rq 7 "NotUsed" 6 "Thres80km_50mi" 5 "Thres50km_31mi" 4 "Thres30km_18mi" 3 "Thres50mi_80km" 2 "Thres30mi_48km" 1 "Thres20mi_32km" 0 "Null" ;
VAL_ 551 ChrgCrdLckEnbl_B_Stat 1 "Enable" 0 "Disable" ;
VAL_ 551 Btt_L_Actl2 127 "Faulty" 126 "NoDataExists" ;
VAL_ 1006 PersIndexIpmb_D_Actl 7 "Unused_3" 6 "Unused_2" 5 "Unused_1" 4 "Vehicle" 3 "PERS_4" 2 "PERS_3" 1 "PERS_2" 0 "PERS_1" ;
VAL_ 1123 GpsUtcYr_No_Actl 31 "Fault" ;
VAL_ 1123 GpsUtcMnth_No_Actl 15 "Fault" ;
VAL_ 1123 GPS_UTC_seconds 63 "Fault" 62 "Unknown" ;
VAL_ 1123 GPS_UTC_minutes 63 "Fault" 62 "Unknown" ;
VAL_ 1123 GPS_UTC_hours 31 "Invalid" 30 "Unknown" ;
VAL_ 1123 GPS_Compass_direction 7 "NorthWest" 6 "West" 5 "SouthWest" 4 "South" 3 "SouthEast" 2 "East" 1 "NorthEast" 0 "North" ;
VAL_ 1123 GPS_Actual_vs_Infer_pos 1 "Inferred_Position" 0 "Actual_Postition" ;
VAL_ 1123 Gps_B_Falt 1 "Yes" 0 "No" ;
VAL_ 1123 GPS_Pdop 31 "Invalid" 30 "Unknown" ;
VAL_ 1122 GPS_Longitude_Minutes 63 "Fault" 62 "Unknown" ;
VAL_ 1122 GPS_Longitude_Min_dec 16383 "Invalid" 16382 "Unknown" ;
VAL_ 1122 GPS_Longitude_Degrees 511 "Fault" 510 "Unknown" ;
VAL_ 1122 GPS_Latitude_Minutes 63 "Fault" 62 "Unknown" ;
VAL_ 1122 GPS_Latitude_Min_dec 16383 "Invalid" 16382 "Unknown" ;
VAL_ 1122 GPS_Latitude_Degrees 255 "Invalid" 254 "Unknown" ;
VAL_ 1122 GpsHsphLongEast_D_Actl 0 "Invalid" 1 "Eastern" 2 "Western" 3 "Fault" ;
VAL_ 1122 GpsHsphLattSth_D_Actl 3 "Fault" 2 "Northern" 1 "Southern" 0 "Invalid" ;
VAL_ 1003 TailLghtLoadMde_D_Stat 7 "Faulty" 6 "NotUsed_2" 5 "NotUsed_1" 4 "TailLightModeOverride" 3 "FalrModeActive" 2 "HitchLoadModeActive" 1 "PayloadModeActive" 0 "NoTailLightActive" ;
VAL_ 1003 PersRecallSrc_D_Actl 7 "NotUsed_3" 6 "NotUsed_2" 5 "NotUsed_1" 4 "MemorySwitch" 3 "RemoteStart" 2 "KeyFob" 1 "CenterStack" 0 "Null" ;
VAL_ 1003 Pers4Key_D_Stat 3 "NotUsed_1" 2 "KeyUnAssociated" 1 "KeyAssociated" 0 "Null" ;
VAL_ 1003 Pers3Key_D_Stat 3 "NotUsed_1" 2 "KeyUnAssociated" 1 "KeyAssociated" 0 "Null" ;
VAL_ 1003 Pers2Key_D_Stat 3 "NotUsed_1" 2 "KeyUnAssociated" 1 "KeyAssociated" 0 "Null" ;
VAL_ 1003 Pers1Key_D_Stat 3 "NotUsed_1" 2 "KeyUnAssociated" 1 "KeyAssociated" 0 "Null" ;
VAL_ 1003 EmPrflNo_D_Stat 7 "NotUsed_3" 6 "NotUsed_2" 5 "NotUsed_1" 4 "Pers4" 3 "Pers3" 2 "Pers2" 1 "Pers1" 0 "Null" ;
VAL_ 1003 EmPrflKeyAssoc_D_Stat 7 "WrongDevice" 6 "KeyAssociateFailed" 5 "KeyAssociateSuccess" 4 "KeyAlreadyInUse" 3 "KeyDisassociated" 2 "KeyAssociationExited" 1 "KeyAssociationEntered" 0 "Null" ;
VAL_ 1003 VehKeyActv_D_Stat 15 "NotUsed7" 14 "NotUsed6" 13 "NotUsed5" 12 "NotUsed4" 11 "NotUsed3" 10 "NotUsed2" 9 "NotUsed1" 8 "Key8Active" 7 "Key7Active" 6 "Key6Active" 5 "Key5Active" 4 "Key4Active" 3 "Key3Active" 2 "Key2Active" 1 "Key1Active" 0 "NoKeyActive" ;
VAL_ 1003 PersNoPos_D_Actl 7 "Unused_3" 6 "Unused_2" 5 "Unused_1" 4 "Vehicle" 3 "PERS_4" 2 "PERS_3" 1 "PERS_2" 0 "PERS_1" ;
VAL_ 1003 PersSetupRestr_D_Actl 3 "Non_Moveable_Person" 2 "Moveable_Person" 1 "Vehicle" 0 "Factory" ;
VAL_ 1003 PersSetupAccessCtrl 1 "Limited" 0 "Full" ;
VAL_ 1003 PersConflict_D_Actl 1 "Conflict" 0 "No_Conflict" ;
VAL_ 1003 AssocConfirm_D_Actl 0 "None" 7 "Associate" 6 "Keycode_Rejected" 5 "Keycode_Accepted" 4 "In_Progress" 3 "Erase" 2 "Duplicate" 1 "Disassociate" ;
VAL_ 1003 PersNo_D_Actl 7 "Unused_3" 6 "Unused_2" 5 "NotDetermined" 4 "Vehicle" 3 "PERS_4" 2 "PERS_3" 1 "PERS_2" 0 "PERS_1" ;
VAL_ 580 BattTracVrtOck_B_Rq 1 "Yes" 0 "No" ;
VAL_ 994 PersCtaSplitView_D_Rq 3 "EnabledFull" 2 "Enabled_180SwitchOnly" 1 "Disabled" 0 "Null" ;
VAL_ 994 PersStore_D_Rq 7 "Unused_2" 6 "Unused_1" 5 "Vehicle" 4 "PERS_4" 3 "PERS_3" 2 "PERS_2" 1 "PERS_1" 0 "Null" ;
VAL_ 994 Pers4OptIn_B_Stats 1 "OPTED_IN" 0 "NOT_OPTED_IN" ;
VAL_ 994 Pers3OptIn_B_Stats 1 "OPTED_IN" 0 "NOT_OPTED_IN" ;
VAL_ 994 Pers2OptIn_B_Stats 1 "OPTED_IN" 0 "NOT_OPTED_IN" ;
VAL_ 994 Pers1OptIn_B_Stats 1 "OPTED_IN" 0 "NOT_OPTED_IN" ;
VAL_ 994 CtrStkPersIndex_D_Actl 7 "Unused_3" 6 "Unused_2" 5 "Unused_1" 4 "Vehicle" 3 "PERS_4" 2 "PERS_3" 1 "PERS_2" 0 "PERS_1" ;
VAL_ 994 CtrStkDsplyOp_D_Rq 7 "Unused_2" 6 "Unused_1" 5 "Copy" 4 "Restore" 3 "Upload" 2 "Set" 1 "Query" 0 "Null" ;
SIG_GROUP_ 932 Profile1A_SigGroup_HS1_3A4_FD1 1 : VehOnSrc2_D_Stat VehOnCtl_D_Stat VehStrtInhbt_D_Stat CanMsg3A4_No_Cnt VehInhbtMde_D_Stat CanMsg3A4_No_Crc RmtCtlBattMntr_B_Falt;
